VERSION "FL_IC_CANFD"

NS_ :

BS_:

BU_: AVAS BBCM CMSM DVR EAMP EPC FLZCU ICC PCL PLG SBOX SCU

BO_ 1265 ICC_ZCU_25: 24 ICC
 SG_ ICC_PwrOff : 18|1@0+ (1,0) [0|1] ""  FLZCU
 SG_ ICC_EtmEgySave : 20|1@0+ (1,0) [0|1] ""  FLZCU
 SG_ ICC_HoodSW : 23|2@0+ (1,0) [0|3] ""  FLZCU
 SG_ ICC_GloveboxSW : 25|2@0+ (1,0) [0|3] ""  FLZCU
 SG_ ICC_ChrgPortCover_Switch : 27|2@0+ (1,0) [0|3] ""  FLZCU
 SG_ ICC_ReWinDefrstSwt : 29|2@0+ (1,0) [0|3] ""  FLZCU
 SG_ ICC_RearMirrorFoldCmd : 31|2@0+ (1,0) [0|3] ""  FLZCU
 SG_ ICC_CenterLockSwt : 33|2@0+ (1,0) [0|3] ""  FLZCU
 SG_ ICC_ReverseExtMirrorSts : 36|3@0+ (1,0) [0|7] ""  FLZCU
 SG_ ICC_LightMainSwitchSts : 39|3@0+ (1,0) [0|7] ""  FLZCU
 SG_ ICC_AutoFoldSts : 41|2@0+ (1,0) [0|3] ""  FLZCU
 SG_ ICC_HeadlampHeightSts : 44|3@0+ (1,0) [0|7] ""  FLZCU
 SG_ ICC_WiprSnvty : 47|3@0+ (1,0) [0|7] ""  FLZCU
 SG_ ICC_WindowCmd : 52|5@0+ (1,0) [0|31] ""  FLZCU
 SG_ ICC_LowBeamDelayOff : 55|3@0+ (1,0) [0|7] ""  FLZCU
 SG_ DrvWinCmd_4F1h : 62|7@0+ (1,-1) [-1|100] "%"  FLZCU
 SG_ PassWinCmd_4F1h : 86|7@0+ (1,-1) [-1|100] "%"  FLZCU
 SG_ DrvRearWinCmd_4F1h : 94|7@0+ (1,-1) [-1|100] "%"  FLZCU
 SG_ PassRearWinCmd_4F1h : 102|7@0+ (1,-1) [-1|100] "%"  FLZCU
 SG_ ICC_FGHeatSts : 105|2@0+ (1,0) [0|3] ""  FLZCU
 SG_ ICC_AutolockSts : 107|2@0+ (1,0) [0|3] ""  FLZCU
 SG_ ICC_WiperID : 109|2@0+ (1,0) [0|3] ""  FLZCU
 SG_ ICC_MaintenanceMode : 111|2@0+ (1,0) [0|3] ""  FLZCU
 SG_ ICC_lockSetSwitchSts : 113|2@0+ (1,0) [0|3] ""  FLZCU
 SG_ ICC_ChildLockSW : 115|2@0+ (1,0) [0|3] ""  FLZCU
 SG_ ICC_ParkUnlockEnable : 117|2@0+ (1,0) [0|3] ""  FLZCU
 SG_ ICC_BLEOpenDriverDoorEnable : 119|2@0+ (1,0) [0|3] ""  FLZCU
 SG_ ICC_WinInhbSwt : 121|2@0+ (1,0) [0|3] ""  FLZCU
 SG_ ICC_SteerWhlHeatgSwt : 124|3@0+ (1,0) [0|7] ""  FLZCU
 SG_ ICC_AutoHeatingset : 127|2@0+ (1,0) [0|3] ""  FLZCU
 SG_ ICC_FrontFogSw : 145|2@0+ (1,0) [0|3] ""  FLZCU
 SG_ ICC_RearFogSw : 147|2@0+ (1,0) [0|3] ""  FLZCU
 SG_ ICC_DoorControlSW : 149|2@0+ (1,0) [0|3] ""  FLZCU
 SG_ ICC_LockCarWinCloseSw : 151|2@0+ (1,0) [0|3] ""  FLZCU
 SG_ ICC_NapStatusSet : 153|2@0+ (1,0) [0|3] ""  FLZCU
 SG_ ICC_NapAreaSet : 155|2@0+ (1,0) [0|3] ""  FLZCU
 SG_ ICC_EasyEntryExitSet : 157|2@0+ (1,0) [0|3] ""  FLZCU
 SG_ ICC_RainCarWinCloseSw : 159|2@0+ (1,0) [0|3] ""  FLZCU
 SG_ ICC_NapTimeSet : 166|6@0+ (1,-1) [-1|60] "min"  FLZCU
 SG_ ICC_NapSetTemperature : 173|5@0+ (0.5,15.5) [15.5|30.5] "℃"  FLZCU
 SG_ ICC_NapCFSStatusSet : 175|2@0+ (1,0) [0|3] ""  FLZCU
 SG_ ICC_HazardLightReq : 177|2@0+ (1,0) [0|3] ""  FLZCU
 SG_ ICC_SpoilerCtrlCmd : 181|3@0+ (1,0) [0|7] ""  FLZCU
 SG_ ICC_SpoilerWelcomeFunSet : 183|2@0+ (1,0) [0|3] ""  FLZCU
 SG_ ICC_CinemaStatus : 185|2@0+ (1,0) [0|3] ""  BBCM,FLZCU,PCL
 SG_ ICC_MusicStatus : 187|2@0+ (1,0) [0|3] ""  FLZCU

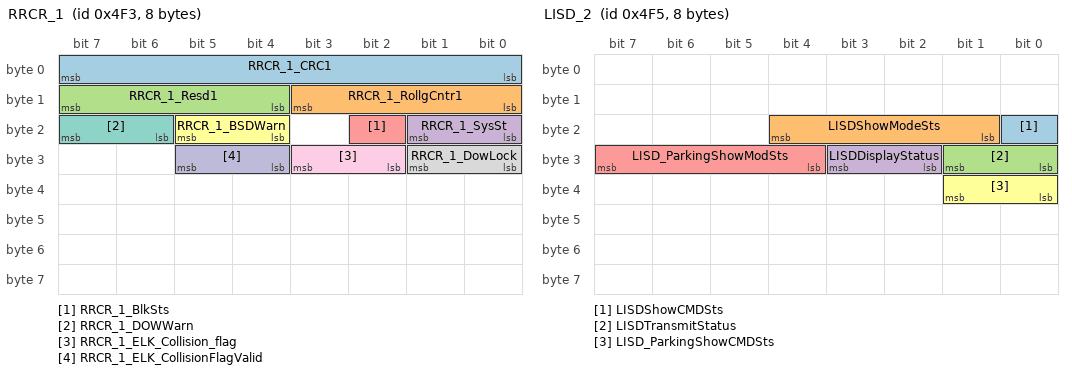
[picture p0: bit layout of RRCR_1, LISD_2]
BO_ 1267 RRCR_1: 8 FLZCU
 SG_ RRCR_1_CRC1 : 7|8@0+ (1,0) [0|255] ""  ICC
 SG_ RRCR_1_RollgCntr1 : 11|4@0+ (1,0) [0|14] ""  ICC
 SG_ RRCR_1_Resd1 : 15|4@0+ (1,0) [0|15] ""  ICC
 SG_ RRCR_1_SysSt : 17|2@0+ (1,0) [0|3] ""  ICC
 SG_ RRCR_1_BlkSts : 18|1@0+ (1,0) [0|1] ""  ICC
 SG_ RRCR_1_BSDWarn : 21|2@0+ (1,0) [0|3] ""  ICC
 SG_ RRCR_1_DOWWarn : 23|2@0+ (1,0) [0|3] ""  ICC
 SG_ RRCR_1_DowLock : 25|2@0+ (1,0) [0|3] ""  ICC
 SG_ RRCR_1_ELK_Collision_flag : 27|2@0+ (1,0) [0|3] ""  ICC
 SG_ RRCR_1_ELK_CollisionFlagValid : 29|2@0+ (1,0) [0|3] ""  ICC

BO_ 1269 LISD_2: 8 FLZCU
 SG_ LISDShowCMDSts : 16|1@0+ (1,0) [0|1] ""  ICC
 SG_ LISDShowModeSts : 20|4@0+ (1,0) [0|15] ""  ICC
 SG_ LISDTransmitStatus : 25|2@0+ (1,0) [0|3] ""  ICC
 SG_ LISDDisplayStatus : 27|2@0+ (1,0) [0|3] ""  ICC
 SG_ LISD_ParkingShowModSts : 31|4@0+ (1,0) [0|15] ""  ICC
 SG_ LISD_ParkingShowCMDSts : 33|2@0+ (1,0) [0|3] ""  ICC

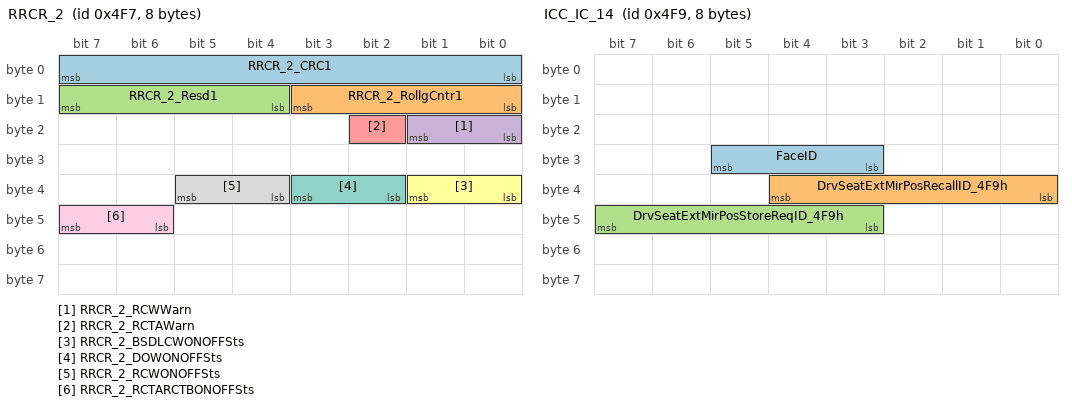
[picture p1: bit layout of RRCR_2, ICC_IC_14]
BO_ 1271 RRCR_2: 8 FLZCU
 SG_ RRCR_2_CRC1 : 7|8@0+ (1,0) [0|255] ""  ICC
 SG_ RRCR_2_RollgCntr1 : 11|4@0+ (1,0) [0|14] ""  ICC
 SG_ RRCR_2_Resd1 : 15|4@0+ (1,0) [0|15] ""  ICC
 SG_ RRCR_2_RCWWarn : 17|2@0+ (1,0) [0|3] ""  ICC
 SG_ RRCR_2_RCTAWarn : 18|1@0+ (1,0) [0|1] ""  ICC
 SG_ RRCR_2_BSDLCWONOFFSts : 33|2@0+ (1,0) [0|3] ""  ICC
 SG_ RRCR_2_DOWONOFFSts : 35|2@0+ (1,0) [0|3] ""  ICC
 SG_ RRCR_2_RCWONOFFSts : 37|2@0+ (1,0) [0|3] ""  ICC
 SG_ RRCR_2_RCTARCTBONOFFSts : 47|2@0+ (1,0) [0|3] ""  ICC

BO_ 1273 ICC_IC_14: 8 ICC
 SG_ FaceID : 29|3@0+ (1,0) [0|7] ""  FLZCU
 SG_ DrvSeatExtMirPosRecallID_4F9h : 36|5@0+ (1,0) [0|31] ""  FLZCU
 SG_ DrvSeatExtMirPosStoreReqID_4F9h : 47|5@0+ (1,0) [0|31] ""  FLZCU

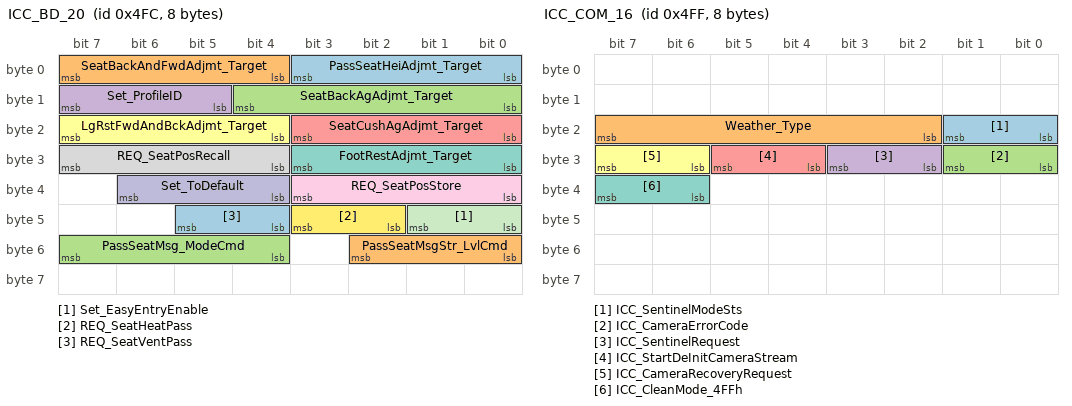
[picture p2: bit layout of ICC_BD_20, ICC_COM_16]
BO_ 1276 ICC_BD_20: 8 ICC
 SG_ PassSeatHeiAdjmt_Target : 3|4@0+ (1,0) [0|15] "" Vector__XXX
 SG_ SeatBackAndFwdAdjmt_Target : 7|4@0+ (1,0) [0|15] "" Vector__XXX
 SG_ SeatBackAgAdjmt_Target : 12|5@0+ (1,0) [0|31] "" Vector__XXX
 SG_ Set_ProfileID : 15|3@0+ (1,0) [0|7] "" Vector__XXX
 SG_ SeatCushAgAdjmt_Target : 19|4@0+ (1,0) [0|15] "" Vector__XXX
 SG_ LgRstFwdAndBckAdjmt_Target : 23|4@0+ (1,0) [0|15] "" Vector__XXX
 SG_ FootRestAdjmt_Target : 27|4@0+ (1,0) [0|15] "" Vector__XXX
 SG_ REQ_SeatPosRecall : 31|4@0+ (1,0) [0|15] "" Vector__XXX
 SG_ REQ_SeatPosStore : 35|4@0+ (1,0) [0|15] "" Vector__XXX
 SG_ Set_ToDefault : 38|3@0+ (1,0) [0|7] "" Vector__XXX
 SG_ Set_EasyEntryEnable : 41|2@0+ (1,0) [0|3] "" Vector__XXX
 SG_ REQ_SeatHeatPass : 43|2@0+ (1,0) [0|3] "" Vector__XXX
 SG_ REQ_SeatVentPass : 45|2@0+ (1,0) [0|3] "" Vector__XXX
 SG_ PassSeatMsgStr_LvlCmd : 50|3@0+ (1,0) [0|7] "" Vector__XXX
 SG_ PassSeatMsg_ModeCmd : 55|4@0+ (1,0) [0|15] "" Vector__XXX

BO_ 1279 ICC_COM_16: 8 ICC
 SG_ ICC_SentinelModeSts : 17|2@0+ (1,0) [0|3] ""  FLZCU
 SG_ Weather_Type : 23|6@0+ (1,0) [0|63] ""  FLZCU
 SG_ ICC_CameraErrorCode : 25|2@0+ (1,0) [0|3] ""  FLZCU
 SG_ ICC_SentinelRequest : 27|2@0+ (1,0) [0|3] ""  FLZCU
 SG_ ICC_StartDeInitCameraStream : 29|2@0+ (1,0) [0|3] ""  FLZCU
 SG_ ICC_CameraRecoveryRequest : 31|2@0+ (1,0) [0|3] ""  FLZCU
 SG_ ICC_CleanMode_4FFh : 39|2@0+ (1,0) [0|3] ""  FLZCU

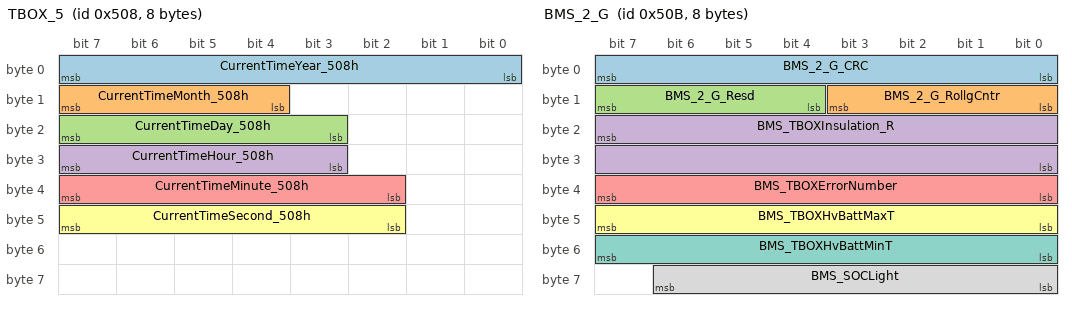
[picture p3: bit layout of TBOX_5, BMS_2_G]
BO_ 1288 TBOX_5: 8 FLZCU
 SG_ CurrentTimeYear_508h : 7|8@0+ (1,2000) [2000|2255] ""  ICC
 SG_ CurrentTimeMonth_508h : 15|4@0+ (1,0) [1|12] ""  ICC
 SG_ CurrentTimeDay_508h : 23|5@0+ (1,0) [1|31] ""  ICC
 SG_ CurrentTimeHour_508h : 31|5@0+ (1,0) [0|23] ""  ICC
 SG_ CurrentTimeMinute_508h : 39|6@0+ (1,0) [0|59] ""  ICC
 SG_ CurrentTimeSecond_508h : 47|6@0+ (1,0) [0|59] ""  ICC

BO_ 1289 ICC_34: 32 ICC
 SG_ ICC_ToggleUnits : 19|2@0+ (1,0) [0|3] ""  FLZCU
 SG_ ICC_TireTemperatureDisplayUnit : 21|2@0+ (1,0) [0|3] ""  FLZCU
 SG_ ICC_TirePressureDisplayUnit : 23|2@0+ (1,0) [0|3] ""  FLZCU
 SG_ ICC_GPSSwitchSet : 25|2@0+ (1,0) [0|3] ""  FLZCU
 SG_ ICC_BtConFlag : 28|3@0+ (1,0) [0|7] ""  FLZCU,SBOX
 SG_ ICC_LanguageSet_509h : 37|6@0+ (1,0) [0|63] ""  FLZCU
 SG_ ICC_Day_Displaysts_509h : 49|2@0+ (1,0) [0|3] ""  FLZCU

BO_ 1290 BMS_8: 8 FLZCU
 SG_ BMS_8_CRC1 : 7|8@0+ (1,0) [0|255] ""  ICC
 SG_ BMS_8_RollgCntr1 : 11|4@0+ (1,0) [0|14] ""  ICC
 SG_ BMS_8_Resd1 : 15|4@0+ (1,0) [0|15] ""  ICC
 SG_ BMS_HvBattCellOverU : 18|3@0+ (1,0) [0|7] ""  ICC
 SG_ BMS_HvBattCellUnderU : 21|3@0+ (1,0) [0|7] ""  ICC
 SG_ BMS_HvBattUnderU : 23|2@0+ (1,0) [0|3] ""  ICC
 SG_ BMS_HvBattDischargeOverCurrent : 26|3@0+ (1,0) [0|7] ""  ICC
 SG_ BMS_HvBattChargeOverCurrent : 29|3@0+ (1,0) [0|7] ""  ICC
 SG_ BMS_HvBattOverU : 31|2@0+ (1,0) [0|3] ""  ICC
 SG_ BMS_HvBattMismatching : 32|1@0+ (1,0) [0|1] ""  ICC
 SG_ BMS_HvBattSocJump : 33|1@0+ (1,0) [0|1] ""  ICC
 SG_ BMS_HvBattCellUUnif : 34|1@0+ (1,0) [0|1] ""  ICC
 SG_ BMS_HvBattLowSoc : 35|1@0+ (1,0) [0|1] ""  ICC
 SG_ BMS_HvBattOverSoc : 36|1@0+ (1,0) [0|1] ""  ICC
 SG_ BMS_HvBattTempUniformity : 37|1@0+ (1,0) [0|1] ""  ICC
 SG_ BMS_BattInterCANErr : 38|1@0+ (1,0) [0|1] ""  ICC
 SG_ BMS_HvBattOverCharging : 39|1@0+ (1,0) [0|1] ""  ICC
 SG_ BMS_HvBattOverTemperature : 47|3@0+ (1,0) [0|7] ""  ICC

BO_ 1291 BMS_2_G: 8 FLZCU
 SG_ BMS_2_G_CRC : 7|8@0+ (1,0) [0|255] ""  ICC
 SG_ BMS_2_G_RollgCntr : 11|4@0+ (1,0) [0|14] ""  ICC
 SG_ BMS_2_G_Resd : 15|4@0+ (1,0) [0|15] ""  ICC
 SG_ BMS_TBOXInsulation_R : 23|16@0+ (1,0) [0|60000] "kiloohm(kΩ)"  ICC
 SG_ BMS_TBOXErrorNumber : 39|8@0+ (1,0) [0|255] ""  ICC
 SG_ BMS_TBOXHvBattMaxT : 47|8@0+ (1,-40) [-40|210] "gradcelsius(°C)"  ICC
 SG_ BMS_TBOXHvBattMinT : 55|8@0+ (1,-40) [-40|210] "gradcelsius(°C)"  ICC
 SG_ BMS_SOCLight : 62|7@0+ (1,0) [0|100] "%"  ICC

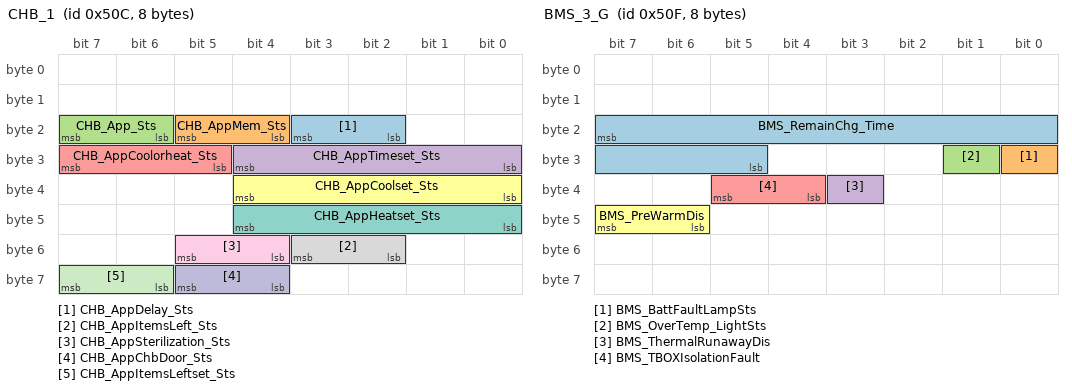
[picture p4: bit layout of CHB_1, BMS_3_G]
BO_ 1292 CHB_1: 8 FLZCU
 SG_ CHB_AppDelay_Sts : 19|2@0+ (1,0) [0|3] ""  ICC
 SG_ CHB_AppMem_Sts : 21|2@0+ (1,0) [0|3] ""  ICC
 SG_ CHB_App_Sts : 23|2@0+ (1,0) [0|3] ""  ICC
 SG_ CHB_AppTimeset_Sts : 28|5@0+ (1,0) [0|31] "h"  ICC
 SG_ CHB_AppCoolorheat_Sts : 31|3@0+ (1,0) [0|7] ""  ICC
 SG_ CHB_AppCoolset_Sts : 36|5@0+ (1,0) [0|31] ""  ICC
 SG_ CHB_AppHeatset_Sts : 44|5@0+ (1,0) [0|31] ""  ICC
 SG_ CHB_AppItemsLeft_Sts : 51|2@0+ (1,0) [0|3] ""  ICC
 SG_ CHB_AppSterilization_Sts : 53|2@0+ (1,0) [0|3] ""  ICC
 SG_ CHB_AppChbDoor_Sts : 61|2@0+ (1,0) [0|3] ""  ICC
 SG_ CHB_AppItemsLeftset_Sts : 63|2@0+ (1,0) [0|3] ""  ICC

BO_ 1295 BMS_3_G: 8 FLZCU
 SG_ BMS_RemainChg_Time : 23|11@0+ (1,0) [0|2047] "min"  ICC
 SG_ BMS_BattFaultLampSts : 24|1@0+ (1,0) [0|1] ""  ICC
 SG_ BMS_OverTemp_LightSts : 25|1@0+ (1,0) [0|1] ""  ICC
 SG_ BMS_ThermalRunawayDis : 35|1@0+ (1,0) [0|1] ""  ICC
 SG_ BMS_TBOXIsolationFault : 37|2@0+ (1,0) [0|3] ""  ICC
 SG_ BMS_PreWarmDis : 47|2@0+ (1,0) [0|3] ""  ICC

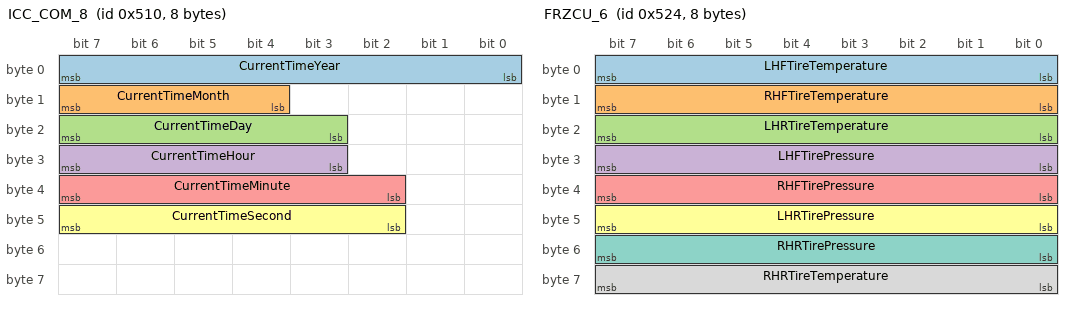
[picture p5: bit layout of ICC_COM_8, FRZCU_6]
BO_ 1296 ICC_COM_8: 8 ICC
 SG_ CurrentTimeYear : 7|8@0+ (1,2000) [2000|2255] ""  DVR,EPC,FLZCU,PLG
 SG_ CurrentTimeMonth : 15|4@0+ (1,0) [1|12] ""  DVR,EPC,FLZCU,PLG
 SG_ CurrentTimeDay : 23|5@0+ (1,0) [1|31] ""  DVR,EPC,FLZCU,PLG
 SG_ CurrentTimeHour : 31|5@0+ (1,0) [0|23] ""  DVR,EPC,FLZCU,PLG
 SG_ CurrentTimeMinute : 39|6@0+ (1,0) [0|59] ""  DVR,EPC,FLZCU,PLG
 SG_ CurrentTimeSecond : 47|6@0+ (1,0) [0|59] ""  DVR,EPC,FLZCU,PLG

BO_ 1299 BMS_1_G: 8 FLZCU
 SG_ BMS_PackVoltageDis : 23|16@0+ (0.1,0) [0|1000] "volt(V)"  ICC
 SG_ BMS_PackCurrentDis : 39|16@0+ (0.1,-2047) [-2047|2047] "ampere(A)"  ICC

BO_ 1310 BBCM_1: 32 SCU
 SG_ DrvSecSeatEasyEntryExitFb_51Eh : 17|2@0+ (1,0) [0|3] ""  ICC
 SG_ PassSecSeatEasyEntryExitFb_51Eh : 19|2@0+ (1,0) [0|3] ""  ICC
 SG_ DrvSecSeatNeedMemory_51Eh : 21|2@0+ (1,0) [0|3] ""  ICC
 SG_ DrvSecMemoryFb_51Eh : 23|2@0+ (1,0) [0|3] ""  ICC
 SG_ DrvSecRecoverFb_51Eh : 25|2@0+ (1,0) [0|3] ""  ICC
 SG_ PassSecSeatNeedMemory_51Eh : 27|2@0+ (1,0) [0|3] ""  ICC
 SG_ PassSecMemoryFb_51Eh : 29|2@0+ (1,0) [0|3] ""  ICC
 SG_ PassSecRecoverFb_51Eh : 31|2@0+ (1,0) [0|3] ""  ICC
 SG_ DrvSecSeatLvlFb_51Eh : 38|7@0+ (1,-1) [-1|100] "%"  ICC
 SG_ DrvSecSeatBackAgFb_51Eh : 46|7@0+ (1,-1) [-1|100] "%"  ICC
 SG_ DrvSecSeatLegSpprtFb_51Eh : 54|7@0+ (1,-1) [-1|100] "%"  ICC
 SG_ DrvSecSeatLegRestAngleFb_51Eh : 62|7@0+ (1,-1) [-1|100] "%"  ICC
 SG_ PassSecSeatLvlFb_51Eh : 70|7@0+ (1,-1) [-1|100] "%"  ICC
 SG_ PassSecSeatBackAgFb_51Eh : 78|7@0+ (1,-1) [-1|100] "%"  ICC
 SG_ PassSecSeatLegSpprtFb_51Eh : 86|7@0+ (1,-1) [-1|100] "%"  ICC
 SG_ PassSecSeatLegRestAngleFb_51Eh : 94|7@0+ (1,-1) [-1|100] "%"  ICC
 SG_ DrvTrdSeatBackAgFb_51Eh : 102|7@0+ (1,-1) [-1|100] "%"  ICC
 SG_ PassTrdSeatBackAgFb_51Eh : 110|7@0+ (1,-1) [-1|100] "%"  ICC
 SG_ DrvTrdSeatFrontFlipFb_51Eh : 118|7@0+ (1,-1) [-1|100] "%"  ICC
 SG_ PassTrdSeatFrontFlipFb_51Eh : 126|7@0+ (1,-1) [-1|100] "%"  ICC
 SG_ PassSecSeatExpSwCmd_51Eh : 145|2@0+ (1,0) [0|3] ""  ICC
 SG_ PassTrdSeatSwCmd_51Eh : 148|3@0+ (1,0) [0|7] ""  ICC
 SG_ BBCM_RLSeatSwCmd3rd : 151|3@0+ (1,0) [0|7] ""  ICC
 SG_ BBCM_RLSeatExpSwCmd2rd : 153|2@0+ (1,0) [0|3] ""  ICC
 SG_ BBCM_RLSeatExpSwSt2rd : 157|2@0+ (1,0) [0|3] ""  ICC
 SG_ PassSecSeatExpSwSt_51Eh : 159|2@0+ (1,0) [0|3] ""  ICC
 SG_ BBCM_RRSeatZeroFb2nd : 166|7@0+ (1,-1) [-1|100] "%"  ICC
 SG_ BBCM_RLSeatZeroFb2nd : 174|7@0+ (1,-1) [-1|100] "%"  ICC
 SG_ BBCM_RLSeatExpRstStsFb : 211|2@0+ (1,0) [0|3] ""  ICC
 SG_ PassSecSeatMovFailCause_51Eh : 243|4@0+ (1,0) [0|15] ""  ICC
 SG_ DrvSecSeatMovFailCause_51Eh : 247|4@0+ (1,0) [0|15] ""  ICC
 SG_ PassTrdSeatMovFailCause_51Eh : 251|4@0+ (1,0) [0|15] ""  ICC
 SG_ DrvTrdSeatMovFailCause_51Eh : 255|4@0+ (1,0) [0|15] ""  ICC

BO_ 1312 ICC_RemoteDiag: 32 ICC
 SG_ ICC_TotalFaultNum : 7|8@0+ (1,0) [0|255] ""  FLZCU
 SG_ ICC_FrameIndex : 12|5@0+ (1,0) [0|31] ""  FLZCU
 SG_ ICC_SupplierNum : 15|3@0+ (1,0) [0|7] ""  FLZCU
 SG_ ICC_FaultNum1 : 23|12@0+ (1,0) [0|4095] ""  FLZCU
 SG_ ICC_FaultNum2 : 27|12@0+ (1,0) [0|4095] ""  FLZCU
 SG_ ICC_FaultNum3 : 47|12@0+ (1,0) [0|4095] ""  FLZCU
 SG_ ICC_FaultNum4 : 51|12@0+ (1,0) [0|4095] ""  FLZCU
 SG_ ICC_FaultNum5 : 71|12@0+ (1,0) [0|4095] ""  FLZCU
 SG_ ICC_FaultNum6 : 75|12@0+ (1,0) [0|4095] ""  FLZCU
 SG_ ICC_FaultNum7 : 95|12@0+ (1,0) [0|4095] ""  FLZCU
 SG_ ICC_FaultNum8 : 99|12@0+ (1,0) [0|4095] ""  FLZCU
 SG_ ICC_FaultNum9 : 119|12@0+ (1,0) [0|4095] ""  FLZCU
 SG_ ICC_FaultNum10 : 123|12@0+ (1,0) [0|4095] ""  FLZCU
 SG_ ICC_FaultNum11 : 143|12@0+ (1,0) [0|4095] ""  FLZCU
 SG_ ICC_FaultNum12 : 147|12@0+ (1,0) [0|4095] ""  FLZCU
 SG_ ICC_FaultNum13 : 167|12@0+ (1,0) [0|4095] ""  FLZCU
 SG_ ICC_FaultNum14 : 171|12@0+ (1,0) [0|4095] ""  FLZCU
 SG_ ICC_FaultNum15 : 191|12@0+ (1,0) [0|4095] ""  FLZCU
 SG_ ICC_FaultNum16 : 195|12@0+ (1,0) [0|4095] ""  FLZCU
 SG_ ICC_FaultNum17 : 215|12@0+ (1,0) [0|4095] ""  FLZCU
 SG_ ICC_FaultNum18 : 219|12@0+ (1,0) [0|4095] ""  FLZCU
 SG_ ICC_FaultNum19 : 239|12@0+ (1,0) [0|4095] ""  FLZCU
 SG_ ICC_FaultNum20 : 243|12@0+ (1,0) [0|4095] ""  FLZCU

BO_ 1314 HCU_25: 64 FLZCU
 SG_ HCU_V2lDisChgBck : 17|2@0+ (1,0) [0|3] ""  ICC
 SG_ HCU_DisChgMemFed : 19|2@0+ (1,0) [0|3] ""  ICC
 SG_ HCU_V2VDisChgBck : 21|2@0+ (1,0) [0|3] ""  ICC
 SG_ HCU_V2l_IntlDisChgBck : 23|2@0+ (1,0) [0|3] ""  ICC
 SG_ HCU_FuelDetnOpDefeated : 25|2@0+ (1,0) [0|3] ""  ICC
 SG_ HCU_FuelDetnModSwtFed : 27|2@0+ (1,0) [0|3] ""  ICC
 SG_ HCU_FuelDetnStateFed : 29|2@0+ (1,0) [0|3] ""  ICC
 SG_ HCU_HVDownRepairModeFed : 31|2@0+ (1,0) [0|3] ""  ICC
 SG_ HCU_SumFuCns : 37|9@0+ (0.1,0) [0|50] "L/km"  ICC
 SG_ HCU_TrailerMode : 39|2@0+ (1,0) [0|3] ""  ICC
 SG_ HCU_TABSwtFed_522h : 40|2@0+ (1,0) [0|3] ""  ICC
 SG_ HCU_KeyDriveModememory : 49|2@0+ (1,0) [0|3] ""  ICC
 SG_ HCU_DrivePowerDispSetFed : 51|2@0+ (1,0) [0|3] ""  ICC
 SG_ HCU_EXPERTNormFed : 57|2@0+ (1,0) [0|3] ""  ICC
 SG_ HCU_4LModeFed : 58|1@0+ (1,0) [0|1] ""  ICC
 SG_ HCU_EXPERTEcoFed : 60|2@0+ (1,0) [0|3] ""  ICC
 SG_ HCU_SingleRegnRmn : 61|1@0+ (1,0) [0|1] ""  ICC
 SG_ HCU_DRIFTModeSts : 63|2@0+ (1,0) [0|3] ""  ICC
 SG_ HCU_EXPERTAWDFed : 81|2@0+ (1,0) [0|3] ""  ICC
 SG_ HCU_EXPERTRWDFed : 83|2@0+ (1,0) [0|3] ""  ICC
 SG_ HCU_CrossaxisFed : 85|2@0+ (1,0) [0|3] ""  ICC
 SG_ HCU_EXPERTSportFed : 87|2@0+ (1,0) [0|3] ""  ICC
 SG_ HCU_StopChrgnModeFed : 89|2@0+ (1,0) [0|3] ""  ICC
 SG_ HCU_StopChrgnFed : 91|2@0+ (1,0) [0|3] ""  ICC
 SG_ HCU_CLIMBFed : 93|2@0+ (1,0) [0|3] ""  ICC
 SG_ HCU_EXPERTAutoFed : 95|2@0+ (1,0) [0|3] ""  ICC
 SG_ HCU_HEV_FunctionLimit : 96|1@0+ (1,0) [0|1] ""  ICC
 SG_ HCU_ParkingChargeReminder : 97|1@0+ (1,0) [0|1] ""  ICC
 SG_ HCU_PowerCut : 98|1@0+ (1,0) [0|1] ""  ICC
 SG_ HCU_IMMOReleaseSignal : 99|1@0+ (1,0) [0|1] ""  ICC
 SG_ HCU_LVPowSupSYSAbn_lit : 100|1@0+ (1,0) [0|1] ""  ICC
 SG_ HCU_ChrgnFctMemSt : 102|2@0+ (1,0) [0|3] ""  ICC
 SG_ HCU_PowerModeChangeInhibit : 104|1@0+ (1,0) [0|1] ""  ICC
 SG_ HCU_DisconnectChagWarn : 105|1@0+ (1,0) [0|1] ""  ICC
 SG_ HCU_EngineRunClmReq : 106|1@0+ (1,0) [0|1] ""  ICC
 SG_ HCU_VehicleSpeedMax_Limit : 107|1@0+ (1,0) [0|1] ""  ICC
 SG_ HCU_AccleAbility_Limit : 108|1@0+ (1,0) [0|1] ""  ICC
 SG_ HCU_DriveInhibit_GearP : 109|1@0+ (1,0) [0|1] ""  ICC
 SG_ HCU_SetModeNotChange : 110|1@0+ (1,0) [0|1] ""  ICC
 SG_ HCU_UTURNSnowFed : 111|1@0+ (1,0) [0|1] ""  ICC
 SG_ HCU_PowerLevel : 114|3@0+ (1,0) [0|7] ""  ICC
 SG_ HCU_TowingModeEna : 115|1@0+ (1,0) [0|1] ""  ICC
 SG_ HCU_LeaveVehicleWarning : 116|1@0+ (1,0) [0|1] ""  ICC
 SG_ HCU_DedicatedModeInhibit : 117|1@0+ (1,0) [0|1] ""  ICC
 SG_ HCU_DisChargeStopFault : 119|2@0+ (1,0) [0|3] ""  ICC
 SG_ HCU_RearEDLSts : 123|4@0+ (1,0) [0|15] ""  ICC
 SG_ HCU_FrntEDLSts : 127|4@0+ (1,0) [0|15] ""  ICC
 SG_ HCU_CruiseLimitSpeedValue : 146|13@0+ (0.0625,0) [0|511.875] "km/h"  ICC
 SG_ HCU_DriveMode_JT : 151|5@0+ (1,0) [0|31] ""  ICC
 SG_ HCU_SocManageFed : 162|3@0+ (1,0) [0|7] ""  ICC
 SG_ HCU_SinglePedalMemFed : 163|1@0+ (1,0) [0|1] ""  ICC
 SG_ HCU_CCOSwtFed : 165|2@0+ (1,0) [0|3] ""  ICC
 SG_ HCU_Pwr : 175|12@0+ (1,-2000) [-2000|2000] "KW"  ICC
 SG_ HCU_DrvGearShiftFailureIndcn : 179|4@0+ (1,0) [0|15] ""  ICC
 SG_ HCU_UTURNSandFed : 184|1@0+ (1,0) [0|1] ""  ICC
 SG_ HCU_CruiseControlStatus : 186|2@0+ (1,0) [0|3] ""  ICC
 SG_ HCU_EXPERTEESPSet : 188|2@0+ (1,0) [0|3] ""  ICC
 SG_ HCU_EgyRegenLevel : 191|3@0+ (1,0) [0|7] ""  ICC
 SG_ HCU_EngyFlowToDisp : 211|5@0+ (1,0) [0|31] ""  ICC
 SG_ HCU_UTURNGrassFed : 212|1@0+ (1,0) [0|1] ""  ICC
 SG_ HCU_UTURNMudFed : 213|1@0+ (1,0) [0|1] ""  ICC
 SG_ HCU_LTCDispFed : 215|2@0+ (1,0) [0|3] ""  ICC
 SG_ HCU_iTAS_Warn : 217|3@0+ (1,0) [0|7] ""  ICC
 SG_ HCU_iCCO_Warn : 221|4@0+ (1,0) [0|15] ""  ICC
 SG_ HCU_DriveModeChangeFail : 222|1@0+ (1,0) [0|1] ""  ICC
 SG_ HCU_25_Crossaxis_Warn : 225|3@0+ (1,0) [0|7] ""  ICC
 SG_ HCU_25_EDLFed : 227|2@0+ (1,0) [0|3] ""  ICC
 SG_ HCU_DraggingModeRemind : 230|3@0+ (1,0) [0|7] ""  ICC
 SG_ HCU_iTASSceneReq : 232|3@0+ (1,0) [0|7] ""  ICC
 SG_ HCU_25_iTAS_SlopWarn : 234|2@0+ (1,0) [0|3] ""  ICC
 SG_ HCU_ExterTempLowHint : 236|2@0+ (1,0) [0|3] ""  ICC
 SG_ HCU_iTAS_Active : 238|2@0+ (1,0) [0|3] ""  ICC
 SG_ HCU_25_VehSpdOffroadRmn : 240|1@0+ (1,0) [0|1] ""  ICC
 SG_ HCU_DrivingModReq : 245|5@0+ (1,0) [0|31] ""  ICC
 SG_ HCU_25_iDRIFT_Warn : 298|3@0+ (1,0) [0|7] ""  ICC
 SG_ HCU_25_SetVehSpdOffroad : 300|2@0+ (1,0) [0|3] ""  ICC
 SG_ HCU_25_LaunchMod_Warn : 303|3@0+ (1,0) [0|7] ""  ICC
 SG_ HCU_25_TAB_Warn : 307|3@0+ (1,0) [0|7] ""  ICC
 SG_ HCU_25_CCO_TextDisp : 311|4@0+ (1,0) [0|15] ""  ICC
 SG_ HCU_25_DCM_Warn : 315|4@0+ (1,0) [0|15] ""  ICC
 SG_ HCU_25_CCMFed : 317|2@0+ (1,0) [0|3] ""  ICC
 SG_ HCU_SumElecCns : 339|12@0+ (0.1,-100) [-100|100] "kwh/100km"  ICC
 SG_ HCU_CrossBorderSts : 341|2@0+ (1,0) [0|3] ""  ICC
 SG_ HCU_DischgSetSOCFed : 367|8@0+ (1,0) [0|100] "%"  ICC
 SG_ HCU_facCleverDrvAct_522h : 369|5@0+ (0.1,-1) [-1|2.1] ""  ICC
 SG_ HCU_stCleverDrvAct_522h : 371|2@0+ (1,0) [0|3] ""  ICC
 SG_ HCU_stCleverRgnAct_522h : 373|2@0+ (1,0) [0|3] ""  ICC
 SG_ HCU_stCleverMainAct_522h : 375|2@0+ (1,0) [0|3] ""  ICC
 SG_ EnergySavingModeSts_522h : 378|2@0+ (1,0) [0|3] ""  ICC
 SG_ HCU_facCleverDrvActRstFed_522h : 380|2@0+ (1,0) [0|3] ""  ICC
 SG_ HCU_SailramainingT_Indc_522h : 407|16@0+ (1,0) [0|65535] "s"  ICC
 SG_ HCU_ATCM_Operation_REQ_522h : 416|3@0+ (1,0) [0|7] ""  ICC
 SG_ HCU_ModeSwFailureIndc_522h : 419|3@0+ (1,0) [0|7] ""  ICC
 SG_ HCU_Sailmode_522h : 423|4@0+ (1,0) [0|15] ""  ICC
 SG_ HCU_CarSickRelfModeFb : 425|2@0+ (1,0) [0|3] ""  ICC
 SG_ HCU_DeepSnowSts_522h : 427|2@0+ (1,0) [0|3] ""  ICC
 SG_ DriveModeChangeFailReason_522h : 429|2@0+ (1,0) [0|3] ""  ICC
 SG_ HCU_CarSickRelfModeDisReason : 436|3@0+ (1,0) [0|7] ""  ICC
 SG_ HCU_DCMSwtFed : 439|3@0+ (1,0) [0|7] ""  ICC

BO_ 1316 FRZCU_6: 8 FLZCU
 SG_ LHFTireTemperature : 7|8@0+ (0.65,-40) [-40|125.1] "℃"  ICC
 SG_ RHFTireTemperature : 15|8@0+ (0.65,-40) [-40|125.1] "℃"  ICC
 SG_ LHRTireTemperature : 23|8@0+ (0.65,-40) [-40|125.1] "℃"  ICC
 SG_ LHFTirePressure : 31|8@0+ (2.75,0) [0|701.25] "kPa"  ICC
 SG_ RHFTirePressure : 39|8@0+ (2.75,0) [0|701.25] "kPa"  ICC
 SG_ LHRTirePressure : 47|8@0+ (2.75,0) [0|701.25] "kPa"  ICC
 SG_ RHRTirePressure : 55|8@0+ (2.75,0) [0|701.25] "kPa"  ICC
 SG_ RHRTireTemperature : 63|8@0+ (0.65,-40) [-40|125.1] "℃"  ICC

BO_ 1318 ICC_TDL_41: 8 ICC
 SG_ ICC_SET_TDL_Rhythm_Switch : 1|2@0+ (1,0) [0|3] ""  FLZCU
 SG_ ICC_SET_TDL_Switch : 3|2@0+ (1,0) [0|3] ""  FLZCU
 SG_ ICC_SET_TDL_ColourModeAdj : 6|3@0+ (1,0) [0|7] ""  FLZCU
 SG_ ICC_TDL_RhythmReq : 10|3@0+ (1,0) [0|7] ""  FLZCU
 SG_ ICC_VoiceWake : 13|3@0+ (1,0) [0|7] ""  FLZCU
 SG_ ICC_TDLAssociatedDriverModeSw : 15|2@0+ (1,0) [0|3] ""  FLZCU
 SG_ ICC_SET_ApiluminanceAdj : 19|4@0+ (1,0) [0|15] ""  FLZCU
 SG_ ICC_SET_MusicLoudness_120HZ : 23|4@0+ (1,0) [0|15] ""  FLZCU
 SG_ ICC_SET_MusicLoudness_250HZ : 27|4@0+ (1,0) [0|15] ""  FLZCU
 SG_ ICC_SET_MusicLoudness_500HZ : 31|4@0+ (1,0) [0|15] ""  FLZCU
 SG_ ICC_SET_MusicLoudness_1000HZ : 35|4@0+ (1,0) [0|15] ""  FLZCU
 SG_ ICC_SET_MusicLoudness_1500HZ : 39|4@0+ (1,0) [0|15] ""  FLZCU
 SG_ ICC_SET_MusicLoudness_2000HZ : 43|4@0+ (1,0) [0|15] ""  FLZCU
 SG_ ICC_SET_MusicLoudness_6000HZ : 47|4@0+ (1,0) [0|15] ""  FLZCU
 SG_ ICC_SET_256ColourAdj : 48|9@0+ (1,0) [0|511] ""  FLZCU
 SG_ ICC_TDL_FlowLightSw : 51|2@0+ (1,0) [0|3] ""  FLZCU
 SG_ ICC_TDL_FlowLightModeAdj : 54|3@0+ (1,0) [0|7] ""  FLZCU

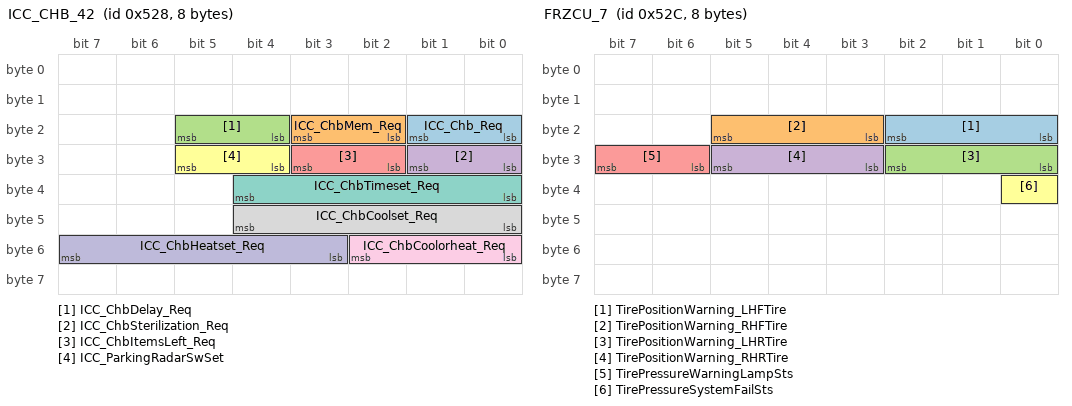
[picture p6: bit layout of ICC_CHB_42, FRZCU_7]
BO_ 1320 ICC_CHB_42: 8 ICC
 SG_ ICC_Chb_Req : 17|2@0+ (1,0) [0|3] ""  FLZCU
 SG_ ICC_ChbMem_Req : 19|2@0+ (1,0) [0|3] ""  FLZCU
 SG_ ICC_ChbDelay_Req : 21|2@0+ (1,0) [0|3] ""  FLZCU
 SG_ ICC_ChbSterilization_Req : 25|2@0+ (1,0) [0|3] ""  FLZCU
 SG_ ICC_ChbItemsLeft_Req : 27|2@0+ (1,0) [0|3] ""  FLZCU
 SG_ ICC_ParkingRadarSwSet : 29|2@0+ (1,0) [0|3] ""  FLZCU
 SG_ ICC_ChbTimeset_Req : 36|5@0+ (1,0) [0|31] "h"  FLZCU
 SG_ ICC_ChbCoolset_Req : 44|5@0+ (1,0) [0|31] ""  FLZCU
 SG_ ICC_ChbCoolorheat_Req : 50|3@0+ (1,0) [0|7] ""  FLZCU
 SG_ ICC_ChbHeatset_Req : 55|5@0+ (1,0) [0|31] ""  FLZCU

BO_ 1322 ICC_IC_2: 8 ICC
 SG_ STAT_AMPAlarm : 7|6@0+ (1,0) [0|63] ""  EAMP

BO_ 1324 FRZCU_7: 8 FLZCU
 SG_ TirePositionWarning_LHFTire : 18|3@0+ (1,0) [0|7] ""  ICC
 SG_ TirePositionWarning_RHFTire : 21|3@0+ (1,0) [0|7] ""  ICC
 SG_ TirePositionWarning_LHRTire : 26|3@0+ (1,0) [0|7] ""  ICC
 SG_ TirePositionWarning_RHRTire : 29|3@0+ (1,0) [0|7] ""  ICC
 SG_ TirePressureWarningLampSts : 31|2@0+ (1,0) [0|3] ""  ICC
 SG_ TirePressureSystemFailSts : 32|1@0+ (1,0) [0|1] ""  ICC

BO_ 1326 ICC_BD_36: 8 ICC
 SG_ ICC_DWDOnOff_Req : 17|2@0+ (1,0) [0|3] ""  FLZCU
 SG_ ICC_ContainerLightSet : 19|2@0+ (1,0) [0|3] ""  FLZCU

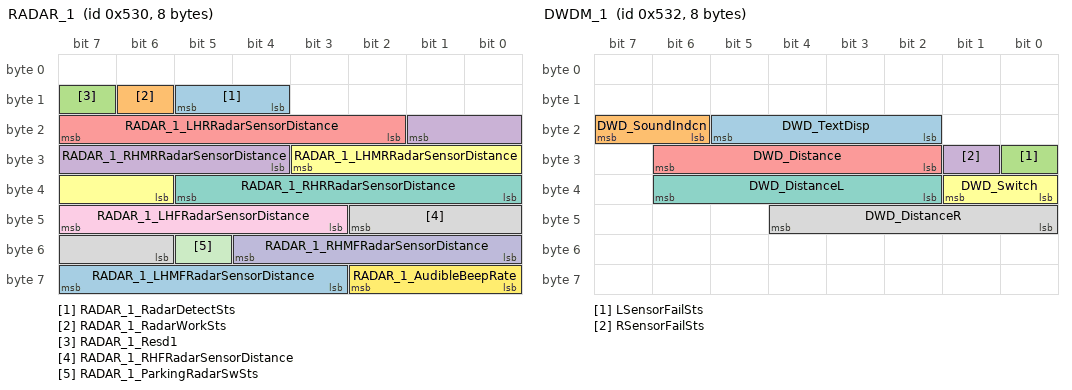
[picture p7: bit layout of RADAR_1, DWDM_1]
BO_ 1328 RADAR_1: 8 FLZCU
 SG_ RADAR_1_RadarDetectSts : 13|2@0+ (1,0) [0|3] ""  ICC
 SG_ RADAR_1_RadarWorkSts : 14|1@0+ (1,0) [0|1] ""  ICC
 SG_ RADAR_1_Resd1 : 15|1@0+ (1,0) [0|1] ""  ICC
 SG_ RADAR_1_RHMRRadarSensorDistance : 17|6@0+ (5,25) [25|180] "Cm"  ICC
 SG_ RADAR_1_LHRRadarSensorDistance : 23|6@0+ (5,25) [25|180] "Cm"  ICC
 SG_ RADAR_1_LHMRRadarSensorDistance : 27|6@0+ (5,25) [25|180] "Cm"  ICC
 SG_ RADAR_1_RHRRadarSensorDistance : 37|6@0+ (5,25) [25|180] "Cm"  ICC
 SG_ RADAR_1_RHFRadarSensorDistance : 42|5@0+ (5,25) [25|160] "Cm"  ICC
 SG_ RADAR_1_LHFRadarSensorDistance : 47|5@0+ (5,25) [25|160] "Cm"  ICC
 SG_ RADAR_1_RHMFRadarSensorDistance : 52|5@0+ (5,25) [25|160] "Cm"  ICC
 SG_ RADAR_1_ParkingRadarSwSts : 53|1@0+ (1,0) [0|1] ""  ICC
 SG_ RADAR_1_AudibleBeepRate : 58|3@0+ (1,0) [0|7] ""  ICC
 SG_ RADAR_1_LHMFRadarSensorDistance : 63|5@0+ (5,25) [25|160] "Cm"  ICC

BO_ 1330 DWDM_1: 8 FLZCU
 SG_ DWD_TextDisp : 21|4@0+ (1,0) [0|15] ""  ICC
 SG_ DWD_SoundIndcn : 23|2@0+ (1,0) [0|3] ""  ICC
 SG_ LSensorFailSts : 24|1@0+ (1,0) [0|1] ""  ICC
 SG_ RSensorFailSts : 25|1@0+ (1,0) [0|1] ""  ICC
 SG_ DWD_Distance : 30|5@0+ (1,0) [0|31] ""  ICC
 SG_ DWD_Switch : 33|2@0+ (1,0) [0|3] ""  ICC
 SG_ DWD_DistanceL : 38|5@0+ (1,0) [0|31] ""  ICC
 SG_ DWD_DistanceR : 44|5@0+ (1,0) [0|31] ""  ICC

BO_ 1331 ICC_IC_37: 32 ICC
 SG_ Set_AMPSoundEffectSupTreble : 147|4@0+ (1,0) [0|15] ""  EAMP,FLZCU
 SG_ ICC_RLSeatEasyEntryExitSet : 17|2@0+ (1,0) [0|3] ""  BBCM,FLZCU,PCL
 SG_ ICC_RRSeatEasyEntryExitSet : 19|2@0+ (1,0) [0|3] ""  BBCM,FLZCU,PCL
 SG_ ICC_RLMemoryRecoveryCmd : 21|2@0+ (1,0) [0|3] ""  BBCM,FLZCU,PCL
 SG_ ICC_RRMemoryRecoveryCmd : 23|2@0+ (1,0) [0|3] ""  BBCM,FLZCU,PCL
 SG_ ICC_RLSitPosnlocation : 25|2@0+ (1,0) [0|3] ""  BBCM,FLZCU,PCL
 SG_ ICC_RRSitPosnlocation : 27|2@0+ (1,0) [0|3] ""  BBCM,FLZCU,PCL
 SG_ ICC_CMSMDisplaySwitch : 29|2@0+ (1,0) [0|3] ""  CMSM,FLZCU
 SG_ ICC_CMSMDisplayAdjustmode : 31|2@0+ (1,0) [0|3] ""  CMSM,FLZCU
 SG_ ICC_CMSMSetstandardSwitch : 33|2@0+ (1,0) [0|3] ""  CMSM,FLZCU
 SG_ ICC_LeftPedalControl : 35|2@0+ (1,0) [0|3] ""  EPC,FLZCU
 SG_ ICC_RightPedalControl : 37|2@0+ (1,0) [0|3] ""  EPC,FLZCU
 SG_ ICC_EPCEnable : 39|2@0+ (1,0) [0|3] ""  EPC,FLZCU
 SG_ ICC_AMPKTVvoiceVolumeSet : 45|6@0+ (1,0) [0|63] ""  EAMP,FLZCU
 SG_ ICC_AMPA2BENCSoundReq : 47|2@0+ (1,0) [0|3] ""  EAMP,FLZCU
 SG_ ICC_AMPENCVolumeSet : 53|6@0+ (1,0) [0|63] ""  EAMP,FLZCU
 SG_ ICC_AMPA2BChimeSoundReq : 55|2@0+ (1,0) [0|3] ""  EAMP,FLZCU
 SG_ ICC_AMPA2BKTVvoiceSoundReq : 58|3@0+ (1,0) [0|7] ""  EAMP,FLZCU
 SG_ Set_AMPSoundFocus_2 : 63|4@0+ (1,0) [0|15] ""  EAMP,FLZCU
 SG_ ICC_MedStatusSet : 81|2@0+ (1,0) [0|3] ""  FLZCU
 SG_ Set_AMPLoudness : 83|2@0+ (1,0) [0|3] ""  FLZCU
 SG_ ICC_MedAreaSet : 87|4@0+ (1,0) [0|15] ""  BBCM,FLZCU,PCL
 SG_ ICC_LeftElectricPedalsSet : 89|2@0+ (1,0) [0|3] ""  EPC,FLZCU
 SG_ ICC_RightElectricPedalsSet : 91|2@0+ (1,0) [0|3] ""  EPC,FLZCU
 SG_ ICC_NapAreaSet2 : 95|3@0+ (1,0) [0|7] ""  BBCM,FLZCU,PCL
 SG_ ICC_DisplayAdjustrAngReq : 103|8@0+ (1,0) [0|255] "°"  CMSM,FLZCU
 SG_ Set_AMPExSoundmode : 113|3@0+ (1,0) [0|7] ""  EAMP,FLZCU
 SG_ Set_AMPKeyVolume : 119|6@0+ (1,0) [0|63] ""  EAMP,FLZCU
 SG_ ICC_CMSMTouchSts : 123|2@0+ (1,0) [0|3] ""  CMSM,FLZCU
 SG_ Set_AMPA2BENCSound : 126|3@0+ (1,0) [0|7] ""  EAMP,FLZCU

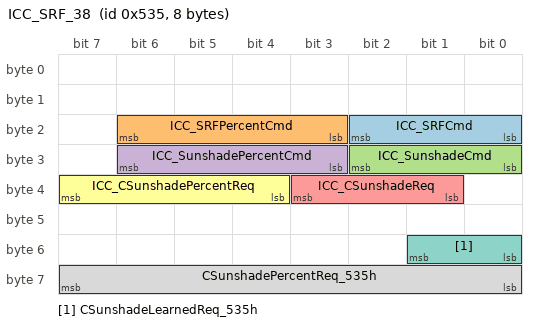
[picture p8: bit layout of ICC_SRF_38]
BO_ 1333 ICC_SRF_38: 8 ICC
 SG_ ICC_SRFCmd : 18|3@0+ (1,0) [0|7] ""  FLZCU
 SG_ ICC_SRFPercentCmd : 22|4@0+ (1,0) [0|15] ""  FLZCU
 SG_ ICC_SunshadeCmd : 26|3@0+ (1,0) [0|7] ""  FLZCU
 SG_ ICC_SunshadePercentCmd : 30|4@0+ (1,0) [0|15] ""  FLZCU
 SG_ ICC_CSunshadeReq : 35|3@0+ (1,0) [0|7] ""  FLZCU
 SG_ ICC_CSunshadePercentReq : 39|4@0+ (1,0) [0|15] ""  FLZCU
 SG_ CSunshadeLearnedReq_535h : 49|2@0+ (1,0) [0|3] ""  FLZCU
 SG_ CSunshadePercentReq_535h : 63|8@0+ (1,0) [0|255] "%"  FLZCU

BO_ 1335 ICC_CH_39: 32 ICC
 SG_ ICC_SET_EPS_SteerReturnRmdSts : 17|2@0+ (1,0) [0|3] ""  FLZCU
 SG_ ICC_SET_MFSShake : 19|2@0+ (1,0) [0|3] ""  FLZCU
 SG_ ICC_DMS_1_DistractionLevel : 22|3@0+ (1,0) [0|7] ""  FLZCU
 SG_ ICC_SET_EPS_AsociWithDrvModSts : 25|2@0+ (1,0) [0|3] ""  FLZCU
 SG_ ICC_OverLoadWarnShieldSet : 27|2@0+ (1,0) [0|3] ""  FLZCU
 SG_ ICC_BSWReq : 29|2@0+ (1,0) [0|3] ""  FLZCU
 SG_ ICC_horizontalReq : 31|2@0+ (1,0) [0|3] ""  FLZCU
 SG_ ICC_RolloverSetCmd : 33|2@0+ (1,0) [0|3] ""  FLZCU
 SG_ ICC_TrekThroughReq_537h : 35|2@0+ (1,0) [0|3] ""  FLZCU
 SG_ ICC_InflateReq_537h : 37|2@0+ (1,0) [0|3] ""  FLZCU
 SG_ ICC_UndergroundModeReq_537h : 39|2@0+ (1,0) [0|3] ""  FLZCU
 SG_ ICC_SandABSSw_537h : 41|2@0+ (1,0) [0|3] ""  FLZCU
 SG_ ICC_SandABSCmd_537h : 43|2@0+ (1,0) [0|3] ""  FLZCU
 SG_ ICC_EPBAUTOCmd_537h : 45|2@0+ (1,0) [0|3] ""  FLZCU
 SG_ ICC_SpeParkSet_537h : 47|2@0+ (1,0) [0|3] ""  FLZCU

BO_ 1337 ICC_TMS_40: 16 ICC
 SG_ ICC_SET_BT_ReduceWindSpeed : 17|2@0+ (1,0) [0|3] ""  FLZCU
 SG_ ICC_SET_IPM_FirstBlowing : 19|2@0+ (1,0) [0|3] ""  FLZCU
 SG_ ICC_SET_IPM_BlowerDelay : 21|2@0+ (1,0) [0|3] ""  FLZCU
 SG_ ICC_SET_CirculationInTunnels : 23|2@0+ (1,0) [0|3] ""  FLZCU
 SG_ ICC_UVCLuminanceReq : 25|2@0+ (1,0) [0|3] ""  FLZCU
 SG_ ICC_UVCControlReq : 27|2@0+ (1,0) [0|3] ""  FLZCU
 SG_ ICC_CrossCountryCoolingReq : 29|2@0+ (1,0) [0|3] ""  FLZCU
 SG_ ICC_KeepWarmReq : 31|2@0+ (1,0) [0|3] ""  FLZCU
 SG_ ICC_keepwarmSetTemperatureReq : 39|8@0+ (1,0) [0|255] ""  FLZCU
 SG_ ICC_ParkingAirConditioning : 41|2@0+ (1,0) [0|3] ""  FLZCU
 SG_ ICC_CoolantFill_Req : 43|2@0+ (1,0) [0|3] ""  FLZCU
 SG_ ICC_FraganceLightoffReq : 45|2@0+ (1,0) [0|3] ""  FLZCU
 SG_ ICC_FraganceMemoffReq : 47|2@0+ (1,0) [0|3] ""  FLZCU
 SG_ ICC_TimingLevel : 50|3@0+ (1,0) [0|7] ""  FLZCU
 SG_ ICC_CFSCycleLevel : 53|3@0+ (1,0) [0|7] ""  FLZCU
 SG_ ICC_AirPurgeReminderReq : 55|2@0+ (1,0) [0|3] ""  FLZCU
 SG_ ICC_TimedVentilationReq : 57|2@0+ (1,0) [0|3] ""  FLZCU
 SG_ ICC_BiochemicalFuncReq : 59|2@0+ (1,0) [0|3] ""  FLZCU
 SG_ ICC_ModeAdjustDisplaySts : 63|4@0+ (1,0) [0|15] ""  FLZCU
 SG_ ICC_PetModeSetTemperature_R_C : 82|5@0+ (0.5,15.5) [15.5|30.5] "℃"  FLZCU
 SG_ ICC_PetmodeSetTemperature_L_C : 87|5@0+ (0.5,15.5) [15.5|30.5] "℃"  FLZCU
 SG_ ICC_PetModeSetCirculationSts : 89|2@0+ (1,0) [0|3] ""  FLZCU
 SG_ ICC_PetModeSetAutoKeySts : 91|2@0+ (1,0) [0|3] ""  FLZCU
 SG_ ICC_PetModeSetCLMOn : 93|2@0+ (1,0) [0|3] ""  FLZCU
 SG_ ICC_ISSFctCmd_539h : 97|2@0+ (1,0) [0|3] ""  FLZCU

BO_ 1338 FMCU_1_G: 8 FLZCU
 SG_ FMCU_ErrLvlDis : 19|3@0+ (1,0) [0|7] ""  ICC
 SG_ FMCU_SpdAct_EDR : 39|16@0+ (1,-32767) [-32767|32766] "rpm"  ICC

BO_ 1341 BMS_44: 48 FLZCU
 SG_ BMS_44_PackPowerRealTime : 23|15@0+ (0.1,-1024) [-1024|1024] "kW"  ICC

BO_ 1345 DVR_1: 16 DVR
 SG_ DVR_1_DVRFailReasons : 20|3@0+ (1,0) [0|7] ""  ICC
 SG_ DVR_1_RecordSts : 22|2@0+ (1,0) [0|3] ""  ICC
 SG_ DVR_1_Sdcard_Sts : 26|3@0+ (1,0) [0|7] ""  ICC

BO_ 1349 SBOX_MSD_1: 16 SBOX
 SG_ SBOX_MSD_Res : 3|4@0+ (1,0) [0|15] ""  ICC
 SG_ SBOX_Ecallphonenub_Res : 7|4@0+ (1,0) [0|15] ""  ICC

BO_ 1351 SBOX_CFG_3: 32 SBOX
 SG_ SBOX_SetMsgTotal : 15|16@0+ (1,0) [0|1000] ""  ICC
 SG_ SBOX_SetMSDTotal : 31|16@0+ (1,0) [0|1000] ""  ICC
 SG_ SBOX_SetCallTimeThreshold : 55|16@0+ (1,0) [0|65535] "min"  ICC
 SG_ SBOX_SetTodayCallTimeThreshold : 71|16@0+ (1,0) [0|65535] "min"  ICC
 SG_ SBOX_SetCurretnCallTime : 87|16@0+ (1,0) [0|65535] "min"  ICC
 SG_ SBOX_SetCurretnMsgThreshold : 103|16@0+ (1,0) [0|1000] ""  ICC
 SG_ SBOX_SetMsgTotalThreshold : 119|16@0+ (1,0) [0|1000] ""  ICC
 SG_ SBOX_SetMsdThreshold : 135|16@0+ (1,0) [0|1000] ""  ICC
 SG_ SBOX_SetCurrenMsdCnt : 151|16@0+ (1,0) [0|1000] ""  ICC
 SG_ SBOX_SetCustomMsgThreshold : 167|16@0+ (1,0) [0|1000] ""  ICC
 SG_ SBOX_SetCurrentCustomMsgCnt : 183|16@0+ (1,0) [0|1000] ""  ICC

BO_ 1353 SBOX_CFG_4: 16 SBOX
 SG_ SBOX_ICC_MACReq : 0|1@0+ (1,0) [0|1] ""  ICC
 SG_ SBOX_MAC_Req0 : 15|8@0+ (1,0) [0|255] ""  ICC
 SG_ SBOX_MAC_Req1 : 23|8@0+ (1,0) [0|255] ""  ICC
 SG_ SBOX_MAC_Req2 : 31|8@0+ (1,0) [0|255] ""  ICC
 SG_ SBOX_MAC_Req3 : 39|8@0+ (1,0) [0|255] ""  ICC
 SG_ SBOX_MAC_Req4 : 47|8@0+ (1,0) [0|255] ""  ICC
 SG_ SBOX_MAC_Req5 : 55|8@0+ (1,0) [0|255] ""  ICC

BO_ 1354 ICC_CFG_46: 32 ICC
 SG_ ICC_SetMsgTotal : 15|16@0+ (1,0) [0|1000] ""  SBOX
 SG_ ICC_SetMSDTotal : 31|16@0+ (1,0) [0|1000] ""  SBOX
 SG_ ICC_SetCallTimeThreshold : 55|16@0+ (1,0) [0|65535] "min"  SBOX
 SG_ ICC_SetTodayCallTimeThreshold : 71|16@0+ (1,0) [0|65535] "min"  SBOX
 SG_ ICC_SetCurretnCallTime : 87|16@0+ (1,0) [0|65535] "min"  SBOX
 SG_ ICC_SetCurretnMsgThreshold : 103|16@0+ (1,0) [0|1000] ""  SBOX
 SG_ ICC_SetMsgTotalThreshold : 119|16@0+ (1,0) [0|1000] ""  SBOX
 SG_ ICC_SetMsdThreshold : 135|16@0+ (1,0) [0|1000] ""  SBOX
 SG_ ICC_SetCurrenMsdCnt : 151|16@0+ (1,0) [0|1000] ""  SBOX
 SG_ ICC_SetCustomMsgThreshold : 167|16@0+ (1,0) [0|1000] ""  SBOX
 SG_ ICC_SetCurrentCustomMsgCnt : 183|16@0+ (1,0) [0|1000] ""  SBOX

BO_ 1356 ICC_CFG_47: 32 ICC
 SG_ ICC_flag : 1|2@0+ (1,0) [0|3] ""  SBOX
 SG_ ICC_ActiveTsp_Req : 3|2@0+ (1,0) [0|3] ""  SBOX
 SG_ ICC_ActiveSim_Req : 5|2@0+ (1,0) [0|3] ""  SBOX
 SG_ ICC_GetMac_req : 6|1@0+ (1,0) [0|1] ""  SBOX
 SG_ ICC_GetIccid_Vin : 7|1@0+ (1,0) [0|1] ""  SBOX
 SG_ ICC_Platform_Phonenub1 : 11|4@0+ (1,0) [0|9] ""  SBOX
 SG_ ICC_Platform_Phonenub2 : 15|4@0+ (1,0) [0|9] ""  SBOX
 SG_ ICC_Platform_Phonenub3 : 19|4@0+ (1,0) [0|9] ""  SBOX
 SG_ ICC_Platform_Phonenub4 : 23|4@0+ (1,0) [0|9] ""  SBOX
 SG_ ICC_Platform_Phonenub5 : 27|4@0+ (1,0) [0|9] ""  SBOX
 SG_ ICC_Platform_Phonenub6 : 31|4@0+ (1,0) [0|9] ""  SBOX
 SG_ ICC_Platform_Phonenub7 : 35|4@0+ (1,0) [0|9] ""  SBOX
 SG_ ICC_Platform_Phonenub8 : 39|4@0+ (1,0) [0|9] ""  SBOX
 SG_ ICC_Platform_Phonenub9 : 43|4@0+ (1,0) [0|9] ""  SBOX
 SG_ ICC_Platform_Phonenub10 : 47|4@0+ (1,0) [0|9] ""  SBOX
 SG_ ICC_Platform_Phonenub11 : 51|4@0+ (1,0) [0|9] ""  SBOX
 SG_ ICC_Platform_Phonenub12 : 55|4@0+ (1,0) [0|9] ""  SBOX
 SG_ ICC_Platform_Phonenub13 : 59|4@0+ (1,0) [0|9] ""  SBOX
 SG_ ICC_Platform_Phonenub14 : 63|4@0+ (1,0) [0|9] ""  SBOX
 SG_ ICC_Platform_Phonenub15 : 67|4@0+ (1,0) [0|9] ""  SBOX
 SG_ ICC_Platform_Phonenub16 : 71|4@0+ (1,0) [0|9] ""  SBOX
 SG_ ICC_Platform_Phonenub17 : 75|4@0+ (1,0) [0|9] ""  SBOX
 SG_ ICC_Platform_Phonenub18 : 79|4@0+ (1,0) [0|9] ""  SBOX
 SG_ ICC_Platform_Phonenub19 : 83|4@0+ (1,0) [0|9] ""  SBOX
 SG_ ICC_Platform_Phonenub20 : 87|4@0+ (1,0) [0|9] ""  SBOX
 SG_ ICC_Mac0 : 95|8@0+ (1,0) [0|255] ""  SBOX
 SG_ ICC_Mac1 : 103|8@0+ (1,0) [0|255] ""  SBOX
 SG_ ICC_Mac2 : 111|8@0+ (1,0) [0|255] ""  SBOX
 SG_ ICC_Mac3 : 119|8@0+ (1,0) [0|255] ""  SBOX
 SG_ ICC_Mac4 : 127|8@0+ (1,0) [0|255] ""  SBOX
 SG_ ICC_Mac5 : 135|8@0+ (1,0) [0|255] ""  SBOX
 SG_ ICC_GivePlatformNumber_Flag : 248|1@0+ (1,0) [0|1] ""  SBOX
 SG_ ICC_Mac_Flag : 249|1@0+ (1,0) [0|1] ""  SBOX

BO_ 1358 SBOX_CFG_5: 64 SBOX
 SG_ SBOX_ActiveTsp_Res : 0|1@0+ (1,0) [0|1] ""  ICC
 SG_ SBOX_ActiveSim_Res : 1|1@0+ (1,0) [0|1] ""  ICC
 SG_ SBOX_GetPlatformNumberRes : 2|1@0+ (1,0) [0|1] ""  ICC
 SG_ SBOX_Mac_Res0 : 15|8@0+ (1,0) [0|255] ""  ICC
 SG_ SBOX_Mac_Res1 : 23|8@0+ (1,0) [0|255] ""  ICC
 SG_ SBOX_Mac_Res2 : 31|8@0+ (1,0) [0|255] ""  ICC
 SG_ SBOX_Mac_Res3 : 39|8@0+ (1,0) [0|255] ""  ICC
 SG_ SBOX_Mac_Res4 : 47|8@0+ (1,0) [0|255] ""  ICC
 SG_ SBOX_Mac_Res5 : 55|8@0+ (1,0) [0|255] ""  ICC
 SG_ SBOX_ICCId_Res0 : 99|4@0+ (1,0) [0|9] ""  ICC
 SG_ SBOX_ICCId_Res1 : 103|4@0+ (1,0) [0|9] ""  ICC
 SG_ SBOX_ICCId_Res2 : 107|4@0+ (1,0) [0|9] ""  ICC
 SG_ SBOX_ICCId_Res3 : 111|4@0+ (1,0) [0|9] ""  ICC
 SG_ SBOX_ICCId_Res4 : 115|4@0+ (1,0) [0|9] ""  ICC
 SG_ SBOX_ICCId_Res5 : 119|4@0+ (1,0) [0|9] ""  ICC
 SG_ SBOX_ICCId_Res6 : 123|4@0+ (1,0) [0|9] ""  ICC
 SG_ SBOX_ICCId_Res7 : 127|4@0+ (1,0) [0|9] ""  ICC
 SG_ SBOX_ICCId_Res8 : 131|4@0+ (1,0) [0|9] ""  ICC
 SG_ SBOX_ICCId_Res9 : 135|4@0+ (1,0) [0|9] ""  ICC
 SG_ SBOX_ICCId_Res10 : 139|4@0+ (1,0) [0|9] ""  ICC
 SG_ SBOX_ICCId_Res11 : 143|4@0+ (1,0) [0|9] ""  ICC
 SG_ SBOX_ICCId_Res12 : 147|4@0+ (1,0) [0|9] ""  ICC
 SG_ SBOX_ICCId_Res13 : 151|4@0+ (1,0) [0|9] ""  ICC
 SG_ SBOX_ICCId_Res14 : 155|4@0+ (1,0) [0|9] ""  ICC
 SG_ SBOX_ICCId_Res15 : 159|4@0+ (1,0) [0|9] ""  ICC
 SG_ SBOX_ICCId_Res16 : 163|4@0+ (1,0) [0|9] ""  ICC
 SG_ SBOX_ICCId_Res17 : 167|4@0+ (1,0) [0|9] ""  ICC
 SG_ SBOX_ICCId_Res18 : 171|4@0+ (1,0) [0|9] ""  ICC
 SG_ SBOX_ICCId_Res19 : 175|4@0+ (1,0) [0|9] ""  ICC
 SG_ SBOX_Vin0 : 183|8@0+ (1,0) [0|90] ""  ICC
 SG_ SBOX_Vin1 : 191|8@0+ (1,0) [0|90] ""  ICC
 SG_ SBOX_Vin2 : 199|8@0+ (1,0) [0|90] ""  ICC
 SG_ SBOX_Vin3 : 207|8@0+ (1,0) [0|90] ""  ICC
 SG_ SBOX_Vin4 : 215|8@0+ (1,0) [0|90] ""  ICC
 SG_ SBOX_Vin5 : 223|8@0+ (1,0) [0|90] ""  ICC
 SG_ SBOX_Vin6 : 231|8@0+ (1,0) [0|90] ""  ICC
 SG_ SBOX_Vin7 : 239|8@0+ (1,0) [0|90] ""  ICC
 SG_ SBOX_Vin8 : 247|8@0+ (1,0) [0|90] ""  ICC
 SG_ SBOX_Vin9 : 255|8@0+ (1,0) [0|90] ""  ICC
 SG_ SBOX_Vin10 : 263|8@0+ (1,0) [0|90] ""  ICC
 SG_ SBOX_Vin11 : 271|8@0+ (1,0) [0|90] ""  ICC
 SG_ SBOX_Vin12 : 279|8@0+ (1,0) [0|90] ""  ICC
 SG_ SBOX_Vin13 : 287|8@0+ (1,0) [0|90] ""  ICC
 SG_ SBOX_Vin14 : 295|8@0+ (1,0) [0|90] ""  ICC
 SG_ SBOX_Vin15 : 303|8@0+ (1,0) [0|90] ""  ICC
 SG_ SBOX_Vin16 : 311|8@0+ (1,0) [0|90] ""  ICC

BO_ 1360 ICC_LC_42: 64 ICC
 SG_ ICC_LISD_DisplaySwitch : 1|2@0+ (1,0) [0|3] ""  FLZCU
 SG_ ICC_LISD_ParkingShowCMD : 3|2@0+ (1,0) [0|3] ""  FLZCU
 SG_ ICC_RISD_DisplaySwitch : 7|2@0+ (1,0) [0|3] ""  FLZCU
 SG_ ICC_RISD_ParkingShowCMD : 9|2@0+ (1,0) [0|3] ""  FLZCU
 SG_ ICC_LogoParkingReq : 13|2@0+ (1,0) [0|3] ""  FLZCU
 SG_ ICC_LogoChargingReq : 15|2@0+ (1,0) [0|3] ""  FLZCU
 SG_ ICC_DRLSw : 17|2@0+ (1,0) [0|3] ""  FLZCU
 SG_ ICC_LISD_ParkingShowMod : 27|4@0+ (1,0) [0|15] ""  FLZCU
 SG_ ICC_RISD_ParkingShowMod : 31|4@0+ (1,0) [0|15] ""  FLZCU
 SG_ ICC_LogoColorReq : 33|9@0+ (1,0) [0|511] ""  FLZCU
 SG_ ICC_MusicLampShowSW : 35|2@0+ (1,0) [0|3] ""  FLZCU
 SG_ ICC_PenetrationLampSetF : 37|2@0+ (1,0) [0|3] ""  FLZCU
 SG_ ICC_XDriveMode : 40|5@0+ (1,0) [0|31] ""  FLZCU
 SG_ ICC_DowWaringSw : 57|2@0+ (1,0) [0|3] ""  FLZCU
 SG_ ICC_CarSearhSetSwitchSts : 59|2@0+ (1,0) [0|3] ""  FLZCU
 SG_ ICC_TDL_NightBright_SW_550h : 61|2@0+ (1,0) [0|3] ""  FLZCU

BO_ 1361 EPC_1: 64 EPC
 SG_ EPC_LeftPedalSystem_Sts : 27|4@0+ (1,0) [0|15] ""  ICC
 SG_ EPC_RightPedalSystem_Sts : 31|4@0+ (1,0) [0|15] ""  ICC
 SG_ EPC_LeftPedalTimeTravel : 39|8@0+ (1,0) [0|100] "%"  ICC
 SG_ EPC_RightPedalTimeTravel : 47|8@0+ (1,0) [0|100] "%"  ICC
 SG_ EPC_RightPedalRealTime_Sts : 50|3@0+ (1,0) [0|7] ""  ICC
 SG_ EPC_LeftPedalBreakIce_Sts : 52|2@0+ (1,0) [0|3] ""  ICC
 SG_ EPC_LeftPedalRealTime_Sts : 55|3@0+ (1,0) [0|7] ""  ICC
 SG_ EPC_RightPedalCmdStatus : 57|2@0+ (1,0) [0|3] ""  ICC
 SG_ EPC_LeftPedalCmdStatus : 59|2@0+ (1,0) [0|3] ""  ICC
 SG_ EPC_Enable_CmdStatus : 61|2@0+ (1,0) [0|3] ""  ICC
 SG_ EPC_RightPedalBreakIce_Sts : 63|2@0+ (1,0) [0|3] ""  ICC
 SG_ EPC_RightPedal3D_Sts : 253|2@0+ (1,0) [0|3] ""  ICC
 SG_ EPC_LeftPedal3D_Sts : 255|2@0+ (1,0) [0|3] ""  ICC

BO_TX_BU_ 1310 : SCU,BBCM;
CM_ SG_ 1265 ICC_PwrOff "车辆下电";
CM_ SG_ 1265 ICC_EtmEgySave "极致节能模式";
CM_ SG_ 1265 ICC_HoodSW "前舱盖开关";
CM_ SG_ 1265 ICC_GloveboxSW "手套箱开关";
CM_ SG_ 1265 ICC_ChrgPortCover_Switch "充电口盖开关";
CM_ SG_ 1265 ICC_ReWinDefrstSwt "Rear window defrost后风窗加热";
CM_ SG_ 1265 ICC_RearMirrorFoldCmd "后视镜手动折叠开关";
CM_ SG_ 1265 ICC_CenterLockSwt "CenterLock中控锁开关";
CM_ SG_ 1265 ICC_ReverseExtMirrorSts "DVD设置倒车外后视镜下翻功能开启";
CM_ SG_ 1265 ICC_LightMainSwitchSts "小灯、近光、Auto开关";
CM_ SG_ 1265 ICC_AutoFoldSts "后视镜自动折叠";
CM_ SG_ 1265 ICC_HeadlampHeightSts "大灯高度调节设置信号";
CM_ SG_ 1265 ICC_WiprSnvty "WiperSensitivity雨刮灵敏度";
CM_ SG_ 1265 ICC_WindowCmd "语音控制车窗指令：
1、包含对左前车窗、右前车窗、左后车窗、右后车窗、前排车窗、后排车窗、全部车窗的指令控制；
2、具备open（打开）、close（关闭）、comfort（通风）三种动作指令，目前只有同时控制四个车窗时有comfort指令。
3、没有此功能，其他信号触发此帧报文发送时，此信号发“Not active”；";
CM_ SG_ 1265 ICC_LowBeamDelayOff "大灯延迟关闭开关";
CM_ SG_ 1265 DrvWinCmd_4F1h "玻璃升降防夹（霍尔、纹波）主驾窗";
CM_ SG_ 1265 PassWinCmd_4F1h "玻璃升降防夹（霍尔、纹波）副驾窗";
CM_ SG_ 1265 DrvRearWinCmd_4F1h "玻璃升降防夹（霍尔、纹波）主驾后窗";
CM_ SG_ 1265 PassRearWinCmd_4F1h "玻璃升降防夹（霍尔、纹波）副驾后窗";
CM_ SG_ 1265 ICC_FGHeatSts "设置前挡风加热";
CM_ SG_ 1265 ICC_AutolockSts "设置自动落锁模式";
CM_ SG_ 1265 ICC_WiperID "雨刮ID";
CM_ SG_ 1265 ICC_MaintenanceMode "雨刮维修模式开关";
CM_ SG_ 1265 ICC_lockSetSwitchSts "解闭锁设置";
CM_ SG_ 1265 ICC_ChildLockSW "儿童锁开关";
CM_ SG_ 1265 ICC_ParkUnlockEnable "驻车解锁设置";
CM_ SG_ 1265 ICC_BLEOpenDriverDoorEnable "蓝牙靠近开门设置";
CM_ SG_ 1265 ICC_WinInhbSwt "Window Inhibit 玻璃禁止开关";
CM_ SG_ 1265 ICC_SteerWhlHeatgSwt "Steering Wheel heating方向盘加热";
CM_ SG_ 1265 ICC_AutoHeatingset "后视镜自动加热设置";
CM_ SG_ 1265 ICC_FrontFogSw "屏内前雾灯开关";
CM_ SG_ 1265 ICC_RearFogSw "屏内后雾灯开关";
CM_ SG_ 1265 ICC_DoorControlSW "顶灯门控开关";
CM_ SG_ 1265 ICC_LockCarWinCloseSw "锁车自动升窗开关";
CM_ SG_ 1265 ICC_NapStatusSet "小憩模式开关设置";
CM_ SG_ 1265 ICC_NapAreaSet "小憩模式开启区域设置";
CM_ SG_ 1265 ICC_EasyEntryExitSet "便捷进入\离车";
CM_ SG_ 1265 ICC_RainCarWinCloseSw "雨天自动升窗开关";
CM_ SG_ 1265 ICC_NapTimeSet "小憩模式时长设置
0x0:Not Active";
CM_ SG_ 1265 ICC_NapSetTemperature "小憩模式设置空调温度";
CM_ SG_ 1265 ICC_NapCFSStatusSet "小憩模式香氛系统开关设置";
CM_ SG_ 1265 ICC_HazardLightReq "双闪灯请求";
CM_ SG_ 1265 ICC_SpoilerCtrlCmd "电动尾翼控制设置";
CM_ SG_ 1265 ICC_SpoilerWelcomeFunSet "电动尾翼迎宾功能设置";
CM_ SG_ 1265 ICC_CinemaStatus "影院模式状态";
CM_ SG_ 1265 ICC_MusicStatus "K歌模式状态";
CM_ BO_ 1267 "报文路由（捷途域控控制BSD灯）";
CM_ SG_ 1267 RRCR_1_CRC1 "Profile1A:E2E CRC (SAE J1850 CRC-8) for 8 Bytes
DataID:0x0046";
CM_ SG_ 1267 RRCR_1_RollgCntr1 "Profile1A:E2E Rolling message counter(the maximum value of Alive counter is 14)";
CM_ SG_ 1267 RRCR_1_Resd1 "Profile1A:E2E Reserved";
CM_ SG_ 1267 RRCR_1_SysSt "System self-test State";
CM_ SG_ 1267 RRCR_1_BlkSts "Blockage Status";
CM_ SG_ 1267 RRCR_1_BSDWarn "BSD/LCA Warning";
CM_ SG_ 1267 RRCR_1_DOWWarn "Door open warning Warning";
CM_ SG_ 1267 RRCR_1_DowLock "Door locking Warning
功能预留，不发";
CM_ SG_ 1269 LISDShowCMDSts "ISD灯光开启状态";
CM_ SG_ 1269 LISDShowModeSts "ISD灯光模式状态";
CM_ SG_ 1269 LISDTransmitStatus "灯具反馈信息：反馈当前数据帧是否接收成功、数据校验是否正确、图片显示是否成功。";
CM_ SG_ 1269 LISDDisplayStatus "灯具反馈信息：反馈当前图片显示状态。";
CM_ SG_ 1269 LISD_ParkingShowModSts "驻车动画状态反馈";
CM_ SG_ 1269 LISD_ParkingShowCMDSts "驻车动画开关反馈";
CM_ SG_ 1271 RRCR_2_CRC1 "Profile1A:E2E CRC (SAE J1850 CRC-8) for 8 Bytes
DataID:0x0047";
CM_ SG_ 1271 RRCR_2_RollgCntr1 "Profile1A:E2E Rolling message counter(the maximum value of Alive counter is 14)";
CM_ SG_ 1271 RRCR_2_Resd1 "Profile1A:E2E Reserved";
CM_ SG_ 1271 RRCR_2_RCWWarn "Rear Collision Warning Warning";
CM_ SG_ 1271 RRCR_2_RCTAWarn "FCTA Warning高配不发";
CM_ SG_ 1271 RRCR_2_BSDLCWONOFFSts "BSD/LCA Switch status";
CM_ SG_ 1271 RRCR_2_DOWONOFFSts "Door open warning Switch status";
CM_ SG_ 1271 RRCR_2_RCWONOFFSts "Rear Collision Warning Switch Status";
CM_ SG_ 1271 RRCR_2_RCTARCTBONOFFSts "RCTA/RCTB Switch status
高配不发
无RCTB功能，开关反馈无0x2";
CM_ SG_ 1273 FaceID "人脸ID";
CM_ SG_ 1273 DrvSeatExtMirPosRecallID_4F9h "主驾座椅位置调出请求";
CM_ SG_ 1273 DrvSeatExtMirPosStoreReqID_4F9h "主驾座椅位置记忆请求";
CM_ SG_ 1276 PassSeatHeiAdjmt_Target "座椅高度调节目标位置（大屏调节请求）";
CM_ SG_ 1276 SeatBackAndFwdAdjmt_Target "座椅水平调节目标值（大屏调节请求）";
CM_ SG_ 1276 SeatBackAgAdjmt_Target "座椅靠背角度调节目标值（大屏调节请求）";
CM_ SG_ 1276 Set_ProfileID "Set personalization profile ID number（记忆设置）";
CM_ SG_ 1276 SeatCushAgAdjmt_Target "座椅坐垫角度调节目标值（大屏调节请求）";
CM_ SG_ 1276 LgRstFwdAndBckAdjmt_Target "腿托前后位置目标值（大屏调节请求）";
CM_ SG_ 1276 FootRestAdjmt_Target "脚托调整位置目标值（大屏调节请求）";
CM_ SG_ 1276 REQ_SeatPosRecall "Seat position recall request";
CM_ SG_ 1276 REQ_SeatPosStore "Seat position store request";
CM_ SG_ 1276 Set_ToDefault "IHU setting function";
CM_ SG_ 1276 Set_EasyEntryEnable "Easy entry Set";
CM_ SG_ 1276 REQ_SeatHeatPass "Passenger Seat heating request from head unit";
CM_ SG_ 1276 REQ_SeatVentPass "Passenger Seat venting request from head unit";
CM_ SG_ 1276 PassSeatMsgStr_LvlCmd "0x0:未激活
0x1:关
0x2:低
0x3:中
0x4:高";
CM_ SG_ 1276 PassSeatMsg_ModeCmd "00x0：无动作
0x1:脉冲模式
0x2:波浪模式
0x3:猫步模式
0x4:单排模式
0x5:交叉模式
0x6:蝶形模式
0x7:腰部按摩模式
0x8:蛇形模式
0x9:特殊模式1
0xA:特殊模式2
0xB:特殊模式3
0xC:特殊模式4";
CM_ SG_ 1279 ICC_SentinelModeSts "哨兵模式开启/关闭的状态";
CM_ SG_ 1279 Weather_Type "天气类型
0x1：晴天
0x2：多云
0x3：阴天
0x4：阵雨
0x5：雷阵雨
0x6：雷阵雨夹冰雹
0x7：雨夹雪
0x8：小雨
0x9：中雨
0xA：大雨
0xB：暴风雨
0xF：小雪
0x10：中雪
0x11：大雪
0x12：暴风雪
0x13：雾天
0x15：尘暴
0x1E：尘埃
0x1F：风沙
0x21：雾霾";
CM_ SG_ 1279 ICC_CameraErrorCode "ICC侧Camera链路错误码";
CM_ SG_ 1279 ICC_SentinelRequest "哨兵模式进入，退出请求";
CM_ SG_ 1279 ICC_StartDeInitCameraStream "ICC通知ADCC开始关闭Camera视频流";
CM_ SG_ 1279 ICC_CameraRecoveryRequest "ICC通知ADCC恢复Camera视频链路";
CM_ SG_ 1279 ICC_CleanMode_4FFh "洗车模式(主项目沿用)";
CM_ BO_ 1288 "ICC收到此帧报文后通过ICC_COM_8（0x510）转发出去";
CM_ SG_ 1288 CurrentTimeYear_508h "GPS时间（年）";
CM_ SG_ 1288 CurrentTimeMonth_508h "GPS时间（月）";
CM_ SG_ 1288 CurrentTimeDay_508h "GPS时间（日）";
CM_ SG_ 1288 CurrentTimeHour_508h "GPS时间（时）";
CM_ SG_ 1288 CurrentTimeMinute_508h "GPS时间（分）";
CM_ SG_ 1288 CurrentTimeSecond_508h "GPS时间（秒）";
CM_ SG_ 1289 ICC_ToggleUnits "英制单位切换";
CM_ SG_ 1289 ICC_TireTemperatureDisplayUnit "胎温显示单位";
CM_ SG_ 1289 ICC_TirePressureDisplayUnit "胎压显示单位";
CM_ SG_ 1289 ICC_GPSSwitchSet "GPS定位开关设置";
CM_ SG_ 1289 ICC_BtConFlag "蓝牙连接状态反馈";
CM_ SG_ 1289 ICC_LanguageSet_509h "语言设置信号";
CM_ SG_ 1289 ICC_Day_Displaysts_509h "白天黑夜模式设置：
0x0:白天模式
0x1:黑夜模式";
CM_ SG_ 1290 BMS_8_CRC1 "Profile1A:E2E CRC (SAE J1850 CRC-8) for 8 Bytes
DataID:0x0023";
CM_ SG_ 1290 BMS_8_RollgCntr1 "Profile1A:E2E Rolling message counter(the maximum value of Alive counter is 14)";
CM_ SG_ 1290 BMS_8_Resd1 "Profile1A:E2E Reserved";
CM_ SG_ 1290 BMS_HvBattCellOverU "电池电芯过压故障  
（默认发0，检测到电芯过压时根据阈值发送过压等级)";
CM_ SG_ 1290 BMS_HvBattCellUnderU "电池电芯欠压故障
（默认发0，检测到电芯欠压时根据阈值发送过压等级)";
CM_ SG_ 1290 BMS_HvBattUnderU "电池包总压欠压故障
（默认发0，检测到电池过压时根据阈值发送过压等级)";
CM_ SG_ 1290 BMS_HvBattDischargeOverCurrent "放电过流
（默认发0 检测到放电电流过流时根据阈值发送过流等级)";
CM_ SG_ 1290 BMS_HvBattChargeOverCurrent "充电过流
（默认发0 检测到充电电流过流时根据阈值发送过流等级)";
CM_ SG_ 1290 BMS_HvBattOverU "电池包总压过压故障 
（默认发0，检测到电池过压时根据阈值发送过压等级)";
CM_ SG_ 1290 BMS_HvBattMismatching "电池包不匹配故障";
CM_ SG_ 1290 BMS_HvBattSocJump "SOC跳变故障（默认发0，检测到SOC跳变发1）";
CM_ SG_ 1290 BMS_HvBattCellUUnif "电芯压差过大";
CM_ SG_ 1290 BMS_HvBattLowSoc "SOC过低
（默认发0检测到SOC过低时发1)";
CM_ SG_ 1290 BMS_HvBattOverSoc "SOC过高（默认发0检测到SOC过高时发1)";
CM_ SG_ 1290 BMS_HvBattTempUniformity "电池温差过大（默认发0，检测到电池温差过大故障发1）";
CM_ SG_ 1290 BMS_BattInterCANErr "内部CAN通讯故障  
（当出现：
SCAN总线故障
SCAN BUSOFF故障
菊花链通讯故障
任一故障均发1，默认发0）";
CM_ SG_ 1290 BMS_HvBattOverCharging "电池电压过充故障（默认 发0 检测到电池包过压一级及以上时发1）";
CM_ SG_ 1290 BMS_HvBattOverTemperature "电池过温故障
（默认发0检测到电池包过温时根据阈值发送过温故障等级）";
CM_ SG_ 1291 BMS_2_G_CRC "Profile1A:E2E CRC (SAE J1850 CRC-8) for 8 Bytes
DataID:0x0075";
CM_ SG_ 1291 BMS_2_G_RollgCntr "Profile1A:E2E Rolling message counter(the maximum value of Alive counter is 14)";
CM_ SG_ 1291 BMS_2_G_Resd "Profile1A:E2E Reserved";
CM_ SG_ 1291 BMS_TBOXInsulation_R "insulation resistance";
CM_ SG_ 1291 BMS_TBOXErrorNumber "BMS Error Numbers";
CM_ SG_ 1291 BMS_TBOXHvBattMaxT "battery max temperature";
CM_ SG_ 1291 BMS_TBOXHvBattMinT "battery min temperature";
CM_ SG_ 1291 BMS_SOCLight "BMS SOCLight
SOC电量显示（仪表显示）";
CM_ SG_ 1292 CHB_AppDelay_Sts "延时开关状态/离车持续工作开关状态";
CM_ SG_ 1292 CHB_AppMem_Sts "记忆开关状态";
CM_ SG_ 1292 CHB_App_Sts "冰箱开关状态（捷途预留）";
CM_ SG_ 1292 CHB_AppTimeset_Sts "延时时间设置/离车持续工作时间设置";
CM_ SG_ 1292 CHB_AppCoolorheat_Sts "制冷制热选择状态
冰箱工作模式（捷途使用）
0x0：无请求
0x1：制冷
0x2：制热
0x3：关
0x4：冷饮模式
0x5：冰淇淋模式
0x6：温奶模式
0x7：热饮模式";
CM_ SG_ 1292 CHB_AppCoolset_Sts "制冷温度设置
0x1~0xD:-6℃~6℃（捷途使用）
0xE~0x19:-18℃~-7℃（股份使用，捷途预留）";
CM_ SG_ 1292 CHB_AppHeatset_Sts "制热温度调节设置";
CM_ SG_ 1292 CHB_AppItemsLeft_Sts "物品遗留开关状态";
CM_ SG_ 1292 CHB_AppSterilization_Sts "杀菌开关状态";
CM_ SG_ 1292 CHB_AppChbDoor_Sts "冰箱是门开关状态反馈信号";
CM_ SG_ 1292 CHB_AppItemsLeftset_Sts "冰箱是否检测到物品的状态";
CM_ SG_ 1295 BMS_RemainChg_Time "BMS_RemainChg_Time";
CM_ SG_ 1295 BMS_BattFaultLampSts "高压电池故障灯显示";
CM_ SG_ 1295 BMS_OverTemp_LightSts "BMS_OverTemp_LightSts";
CM_ SG_ 1295 BMS_ThermalRunawayDis "Thermal run-away";
CM_ SG_ 1295 BMS_TBOXIsolationFault "battery insulation fault state";
CM_ SG_ 1295 BMS_PreWarmDis "preheat and keepwarm indication";
CM_ SG_ 1296 CurrentTimeYear "时间（年)";
CM_ SG_ 1296 CurrentTimeMonth "时间（月）";
CM_ SG_ 1296 CurrentTimeDay "时间（日）";
CM_ SG_ 1296 CurrentTimeHour "时间（时）";
CM_ SG_ 1296 CurrentTimeMinute "时间（分）";
CM_ SG_ 1296 CurrentTimeSecond "时间（秒）";
CM_ SG_ 1299 BMS_PackVoltageDis "Battery Voltage";
CM_ SG_ 1299 BMS_PackCurrentDis "Baattery Current(direction:discharge+ charge -)";
CM_ SG_ 1310 DrvSecSeatEasyEntryExitFb_51Eh "二排主驾侧便捷进入\离车";
CM_ SG_ 1310 PassSecSeatEasyEntryExitFb_51Eh "二排副驾便捷进入\离车";
CM_ SG_ 1310 DrvSecSeatNeedMemory_51Eh "二排主驾侧座椅记忆弹框请求";
CM_ SG_ 1310 DrvSecMemoryFb_51Eh "二排左主驾侧记忆保存状态";
CM_ SG_ 1310 DrvSecRecoverFb_51Eh "二排主驾侧记忆恢复状态";
CM_ SG_ 1310 PassSecSeatNeedMemory_51Eh "二排副驾侧座椅记忆弹框请求";
CM_ SG_ 1310 PassSecMemoryFb_51Eh "二排副驾侧记忆保存状态";
CM_ SG_ 1310 PassSecRecoverFb_51Eh "二排副驾侧记忆恢复状态";
CM_ SG_ 1310 DrvSecSeatLvlFb_51Eh "二排主驾侧座椅水平位置
0x0:Not active";
CM_ SG_ 1310 DrvSecSeatBackAgFb_51Eh "二排主驾侧座椅靠背角度位置
0x0:Not active";
CM_ SG_ 1310 DrvSecSeatLegSpprtFb_51Eh "二排主驾侧座椅腿托旋转位置
0x0:Not active";
CM_ SG_ 1310 DrvSecSeatLegRestAngleFb_51Eh "二排主驾侧座椅腿托延伸位置
0x0:Not active";
CM_ SG_ 1310 PassSecSeatLvlFb_51Eh "二排副驾侧座椅水平位置
0x0:Not active";
CM_ SG_ 1310 PassSecSeatBackAgFb_51Eh "二排副驾侧座椅靠背角度位置
0x0:Not active";
CM_ SG_ 1310 PassSecSeatLegSpprtFb_51Eh "二排副驾侧座椅腿托旋转位置
0x0:Not active";
CM_ SG_ 1310 PassSecSeatLegRestAngleFb_51Eh "二排副驾侧座椅腿托延伸位置
0x0:Not active";
CM_ SG_ 1310 DrvTrdSeatBackAgFb_51Eh "三排主驾侧座椅靠背角度位置
0x0:Not active";
CM_ SG_ 1310 PassTrdSeatBackAgFb_51Eh "三排副驾侧座椅靠背角度位置
0x0:Not active";
CM_ SG_ 1310 DrvTrdSeatFrontFlipFb_51Eh "三排主驾侧座椅前翻角度位置
0x0:Not active";
CM_ SG_ 1310 PassTrdSeatFrontFlipFb_51Eh "三排副驾侧座椅前翻角度位置
0x0:Not active";
CM_ SG_ 1310 PassSecSeatExpSwCmd_51Eh "二排副驾侧座椅一键展开/复位执行状态";
CM_ SG_ 1310 PassTrdSeatSwCmd_51Eh "三排副驾侧座椅一键开关调节指令
0x1:靠背折叠
0x2:靠背展开
0x3:坐垫前翻
0x4:坐垫回位";
CM_ SG_ 1310 BBCM_RLSeatSwCmd3rd "三排左侧座椅一键开关调节指令
0x1:靠背折叠
0x2:靠背展开
0x3:坐垫前翻
0x4:坐垫回位";
CM_ SG_ 1310 BBCM_RLSeatExpSwCmd2rd "二排左侧座椅一键展开/复位执行状态（ICC进行提示）";
CM_ SG_ 1310 BBCM_RLSeatExpSwSt2rd "二排左侧座椅一键展开/复位调节指令(FLZCU进行主驾避让)";
CM_ SG_ 1310 PassSecSeatExpSwSt_51Eh "二排副驾侧座椅一键展开/复位调节指令";
CM_ SG_ 1310 BBCM_RRSeatZeroFb2nd "二排右侧座椅零重力位置
0x0:Not active";
CM_ SG_ 1310 BBCM_RLSeatZeroFb2nd "二排左侧座椅零重力位置
0x0:Not active";
CM_ SG_ 1310 BBCM_RLSeatExpRstStsFb "二排左侧座椅是否处于一键展开位置
0x0:不处于一键展开位置
0x1:处于一键展开位置";
CM_ SG_ 1310 PassSecSeatMovFailCause_51Eh "二排副驾侧座椅调节失败原因
0x1:发生防夹
0x2:座椅未学习
0x3:存在故障（电机故障/开关故障/过压/欠压/霍尔丢失）
0x4:二排右侧座椅手动调节开关打断
0x5:三排一键开关打断
0x6:副驾坐人
0x7:三排右侧座椅坐人
0x8:三排右侧座椅不在展开状态
0x9:副驾调节异常中断
0xA:当前处于女王副驾模式中
0xB:优先级不满足
0xC:无当前配置";
CM_ SG_ 1310 DrvSecSeatMovFailCause_51Eh "二排主驾侧座椅调节失败原因
0x1:发生防夹
0x2:座椅未学习
0x3:存在故障（电机故障/开关故障/过压/欠压/霍尔丢失）
0x4:二排左侧座椅手动调节开关打断
0x5:优先级不满足
0x6:无当前配置";
CM_ SG_ 1310 PassTrdSeatMovFailCause_51Eh "三排副驾侧座椅调节失败原因
0x0:Not active
0x1:发生防夹
0x2:座椅未学习
0x3:存在故障（电机故障/开关故障/过压/欠压/霍尔丢失）
0x4:车辆非P挡
0x5:三排右侧座椅坐人
0x6:三排右侧座椅手动开关按键打断
0x7:优先级不满足
0x8:触发防玩保护
0x9:三排右侧靠背未处于折叠状态
0xA:三排右侧座椅坐垫未处于回位状态
0xB:无当前配置";
CM_ SG_ 1310 DrvTrdSeatMovFailCause_51Eh "三排主驾侧座椅调节失败原因
0x0:Not active
0x1:发生防夹
0x2:座椅未学习
0x3:存在故障（电机故障/开关故障/过压/欠压/霍尔丢失）
0x4:车辆非P挡
0x5:三排左侧座椅坐人
0x6:三排左侧座椅手动开关按键打断
0x7:优先级不满足
0x8:触发防玩保护
0x9:三排左侧靠背未处于折叠状态
0xA:三排左侧座椅坐垫未处于回位状态
0xB:无当前配置";
CM_ SG_ 1312 ICC_TotalFaultNum "当前故障总数";
CM_ SG_ 1312 ICC_FrameIndex "帧序号";
CM_ SG_ 1312 ICC_SupplierNum "供应商代码";
CM_ SG_ 1312 ICC_FaultNum1 "故障列表1";
CM_ SG_ 1312 ICC_FaultNum2 "故障列表2";
CM_ SG_ 1312 ICC_FaultNum3 "故障列表3";
CM_ SG_ 1312 ICC_FaultNum4 "故障列表4";
CM_ SG_ 1312 ICC_FaultNum5 "故障列表5";
CM_ SG_ 1312 ICC_FaultNum6 "故障列表6";
CM_ SG_ 1312 ICC_FaultNum7 "故障列表7";
CM_ SG_ 1312 ICC_FaultNum8 "故障列表8";
CM_ SG_ 1312 ICC_FaultNum9 "故障列表9";
CM_ SG_ 1312 ICC_FaultNum10 "故障列表10";
CM_ SG_ 1312 ICC_FaultNum11 "故障列表11";
CM_ SG_ 1312 ICC_FaultNum12 "故障列表12";
CM_ SG_ 1312 ICC_FaultNum13 "故障列表13";
CM_ SG_ 1312 ICC_FaultNum14 "故障列表14";
CM_ SG_ 1312 ICC_FaultNum15 "故障列表15";
CM_ SG_ 1312 ICC_FaultNum16 "故障列表16";
CM_ SG_ 1312 ICC_FaultNum17 "故障列表17";
CM_ SG_ 1312 ICC_FaultNum18 "故障列表18";
CM_ SG_ 1312 ICC_FaultNum19 "故障列表19";
CM_ SG_ 1312 ICC_FaultNum20 "故障列表20";
CM_ SG_ 1314 HCU_V2lDisChgBck "V2L外放电开关反馈";
CM_ SG_ 1314 HCU_DisChgMemFed "V2L外放电记忆开关反馈";
CM_ SG_ 1314 HCU_V2VDisChgBck "V2V放电开关反馈";
CM_ SG_ 1314 HCU_V2l_IntlDisChgBck "V2L内放电开关反馈";
CM_ SG_ 1314 HCU_FuelDetnOpDefeated "燃油检测开启失败提示";
CM_ SG_ 1314 HCU_FuelDetnModSwtFed "燃油检测开关反馈";
CM_ SG_ 1314 HCU_FuelDetnStateFed "燃油检测模式状态反馈";
CM_ SG_ 1314 HCU_HVDownRepairModeFed "断高压维修模式开关反馈";
CM_ SG_ 1314 HCU_SumFuCns "自清零后累计百公里油耗显示(仅仪表使用)";
CM_ SG_ 1314 HCU_TrailerMode "被拖模式开关反馈";
CM_ SG_ 1314 HCU_TABSwtFed_522h "ICC坦克转向开关反馈
0x0:Not_Active 使能位
0x1:Active 激活
0x2:Stand_by 就绪
0x3:Failed 失败";
CM_ SG_ 1314 HCU_KeyDriveModememory "驾驶模式记忆开关反馈";
CM_ SG_ 1314 HCU_DrivePowerDispSetFed "驱动系统功率显示方式开关反馈";
CM_ SG_ 1314 HCU_EXPERTNormFed "专家模式动力设置标准模式开关反馈";
CM_ SG_ 1314 HCU_4LModeFed "低速四驱开关反馈";
CM_ SG_ 1314 HCU_EXPERTEcoFed "专家模式动力设置柔和模式开关反馈";
CM_ SG_ 1314 HCU_SingleRegnRmn "当车机收到HCU发送信号“HCU_SingleRegnRmn =0x1”时，弹框提示“单踏板受限已退出，请注意安全驾驶！”，并播放报警音持续3s；
当车机收到HCU发送信号“HCU_SingleRegnRmn=0x0”时，停止提示，并停止报警音；";
CM_ SG_ 1314 HCU_DRIFTModeSts "通过大屏设置漂移模式灵敏度开关反馈
0x0:不动作
0x1:入门
0x2:大师
0x3:专家";
CM_ SG_ 1314 HCU_EXPERTAWDFed "专家模式驱动形式四驱开关设置反馈";
CM_ SG_ 1314 HCU_EXPERTRWDFed "专家模式驱动形式后驱开关设置反馈";
CM_ SG_ 1314 HCU_CrossaxisFed "专家模式交叉轴模式开关设置反馈";
CM_ SG_ 1314 HCU_EXPERTSportFed "专家模式动力设置激进模式开关反馈";
CM_ SG_ 1314 HCU_StopChrgnModeFed "驻车发电模式开关反馈";
CM_ SG_ 1314 HCU_StopChrgnFed "驻车发电开关反馈";
CM_ SG_ 1314 HCU_CLIMBFed "防溜设置开关反馈";
CM_ SG_ 1314 HCU_EXPERTAutoFed "专家模式驱动形式Auto开关设置反馈";
CM_ SG_ 1314 HCU_HEV_FunctionLimit "仪表文字提示“HEV模式不可用”";
CM_ SG_ 1314 HCU_ParkingChargeReminder "仪表文字提示“请先驻车再充电”";
CM_ SG_ 1314 HCU_PowerCut "仪表文字提示“动力即将切断，请靠边停车”";
CM_ SG_ 1314 HCU_IMMOReleaseSignal "防盗报警指示灯信号";
CM_ SG_ 1314 HCU_LVPowSupSYSAbn_lit "低压供电系统异常状态";
CM_ SG_ 1314 HCU_ChrgnFctMemSt "强制保电记忆开关反馈";
CM_ SG_ 1314 HCU_PowerModeChangeInhibit "仪表文字提示“为保障越野性能，模式无法切换”";
CM_ SG_ 1314 HCU_DisconnectChagWarn "仪表文字提示“请拔下充电枪”";
CM_ SG_ 1314 HCU_EngineRunClmReq "仪表文字提示“空调请求发动机运行中”";
CM_ SG_ 1314 HCU_VehicleSpeedMax_Limit "仪表文字提示“最高车速受限，请尽快联系售后检修”";
CM_ SG_ 1314 HCU_AccleAbility_Limit "仪表文字提示“加速性能受限，请尽快联系售后检修”";
CM_ SG_ 1314 HCU_DriveInhibit_GearP "仪表文字提示“动力受限，进入P挡后无法再次行驶，请尽快联系售后检修”";
CM_ SG_ 1314 HCU_SetModeNotChange "仪表文字提示“模式禁止切换”";
CM_ SG_ 1314 HCU_UTURNSnowFed "极限调头雪地场景反馈";
CM_ SG_ 1314 HCU_PowerLevel "仪表驱动能力等级";
CM_ SG_ 1314 HCU_TowingModeEna "大屏被拖提醒文字提示ICC接收
0x1时，大屏文字提示“切换至被拖模式需满足以下条件：1、挡位处于P挡；2、踩下刹车；3、车辆不在充电状态”";
CM_ SG_ 1314 HCU_LeaveVehicleWarning "仪表声音提醒";
CM_ SG_ 1314 HCU_DedicatedModeInhibit "仪表文字提示“当前模式不可用，请切换至越野模式”";
CM_ SG_ 1314 HCU_DisChargeStopFault "0x1时仪表文字提示“电池电量过低，放电停止”0x2时仪表文字提示“燃油不足，放电停止”";
CM_ SG_ 1314 HCU_RearEDLSts "后差速锁状态
0x0:不锁
0x1:解锁
0x2:锁止
0x3:切换提醒
0x4:不满足锁止条件
0x5:差速锁无法锁止故障
0x6:差速锁无法解锁故障";
CM_ SG_ 1314 HCU_FrntEDLSts "前差速锁状态
0x0: 不锁
0x1: 解锁
0x2：锁止
0x3：切换提醒
0x4：不满足锁止条件
0x5：差速锁无法锁止故障
0x6：差速锁无法解锁故障
0x7：提示需挂入后锁和4L
0x8：提示开启后锁
0x9：提示开启4L";
CM_ SG_ 1314 HCU_CruiseLimitSpeedValue "定速巡航设定车速";
CM_ SG_ 1314 HCU_DriveMode_JT "驾驶模式反馈
0x0:经济
0x1:标准
0x2:运动
0x3:雪/草地
0x4:泥地
0x5:越野
0x6:沙地
0x7:岩石
0x8:专家
0x9:智能
0xA:涉水
0xB:极限掉头
0xC:漂移
0xD:拖挂
0xE:越野竞速
0xF:晕车舒缓
0x10:智慧能量管理
0x11:纵横征服
0x12~0x1F：预留";
CM_ SG_ 1314 HCU_SocManageFed "Soc_Manage_Feedback";
CM_ SG_ 1314 HCU_SinglePedalMemFed "单踏板记忆开关反馈";
CM_ SG_ 1314 HCU_CCOSwtFed "越野蠕行开关反馈";
CM_ SG_ 1314 HCU_Pwr "instant_power";
CM_ SG_ 1314 HCU_UTURNSandFed "极限调头泥地场景开关反馈";
CM_ SG_ 1314 HCU_CruiseControlStatus "定速巡航指示灯";
CM_ SG_ 1314 HCU_EXPERTEESPSet "关闭牵引力控制系统&车身稳定控制系统（TCS&VDC_OFF）
全开（TCS、VDC等与ESP有关功能全部开启）
全关（TCS、VDC及RMI放侧翻、DTC发动机拖滞力矩管理）";
CM_ SG_ 1314 HCU_EgyRegenLevel "power_regeneration_level";
CM_ SG_ 1314 HCU_EngyFlowToDisp "0x0:初始化
0x1:无能量流状态
0x2:发动机单独运行
0x3:纯电前驱
0x4:纯电前驱回馈
0x5:纯电后驱
0x6:纯电后驱回馈
0x7:纯电四驱
0x8:纯电四驱回馈
0x9:串联前驱电池充电
0xA:串联前驱电池放电
0xB:串联前驱电池无电流
0xC:串联前驱回馈
0xD:串联后驱电池充电
0xE:串联后驱电池放电
0xF:串联后驱电池无电流
0x10:串联后驱回馈
0x11:串联四驱电池充电
0x12:串联四驱电池放电
0x13:串联四驱电池无电流
0x14:串联四驱回馈
0x15:并联前驱电池充电
0x16:并联前驱电池放电
0x17:并联前驱电池无电流
0x18:并联前驱回馈
0x19:并联四驱电池充电
0x1A:并联四驱电池放电
0x1B:并联四驱电池无电流
0x1C:并联四驱回馈
0x1D:原地发电电池充电
0x1E:原地发电电池放电
0x1F:原地发电电池无电流";
CM_ SG_ 1314 HCU_UTURNGrassFed "极限调头草地场景反馈";
CM_ SG_ 1314 HCU_UTURNMudFed "极限调头沙地场景开关反馈";
CM_ SG_ 1314 HCU_LTCDispFed "续航里程选择开关反馈";
CM_ SG_ 1314 HCU_iTAS_Warn "0x0: 无提示
0x1:iTAS功能已激活，无法锁止后桥差速锁
0x2:请释放EPB
0x3:当前车速过高，请减速
0x4：制动盘温度过高，极限掉头功能已退出
0x5：车辆被卡住，极限掉头功能退出
0x6：极限掉头使用时间到达极限，功能退出
0x7：请切换至D档开启极限掉头";
CM_ SG_ 1314 HCU_iCCO_Warn "0x0: 无提示
0x1:请释放EPB
0x2:当前车速过高，请减速
0x3:请关好车门，系好安全带
0x4:请切换至D档或N档开启越野蠕行
0x5:请关闭 APA/ACC/CC巡航
0x6:请退出HDC陡坡缓降/自动驻车
0x7:请手动切换驾驶模式至雪地或泥地或沙地或岩石
0x8:请踩制动踏板
0x9:iCCO越野蠕行已退出";
CM_ SG_ 1314 HCU_DriveModeChangeFail "驾驶模式切换不满足条件，提示“请停车后退出当前驾驶模式”";
CM_ SG_ 1314 HCU_25_Crossaxis_Warn "0x0: 无提示
0x1:请释放EPB
0x2:当前车速过高，交叉轴功能已退出
0x3:请切换至D档开启交叉轴功能
0x4:请关好车门，系好安全带
0x5:请将车辆静止后踩制动踏板
0x6:进入交叉轴模式后进行空簧高度调节";
CM_ SG_ 1314 HCU_25_EDLFed "中央差速锁显示信号";
CM_ SG_ 1314 HCU_DraggingModeRemind "0x0: 无提示
0x1:禁用ECO和越野模式
0x2:拖挂模式下仅支持Normal和Sport
0x3:ECO和越野模式恢复
0x4~0x7:预留";
CM_ SG_ 1314 HCU_iTASSceneReq "iTAS场景选择信息";
CM_ SG_ 1314 HCU_25_iTAS_SlopWarn "极限调头坡度条件不满足提醒
0x0:无提示
0x1:地面坡度过大
0x2~0x3:Reserved";
CM_ SG_ 1314 HCU_ExterTempLowHint "0x0:无提示
0x1:环境温度低切换为HEV模式
0x2:环境温度过低发动机运行中";
CM_ SG_ 1314 HCU_iTAS_Active "极限掉头激活状态（仪表）";
CM_ SG_ 1314 HCU_25_VehSpdOffroadRmn "漂移，掉头，专家，交叉轴，越野蠕行，越野竞速功能，用户在车辆未静止状态下点退出按钮或硬开关，仪表接收该信号0x1后显示“请将车辆禁止后再设置”";
CM_ SG_ 1314 HCU_DrivingModReq "HCU给IPB映射驾驶模式";
CM_ SG_ 1314 HCU_25_iDRIFT_Warn "0x0:无提示
0x1:请关好车门，系好安全带
0x2:请将车辆停止
0x3:系统故障，漂移模式暂无法开启
0x4:进入漂移模式后进行空簧高度调节";
CM_ SG_ 1314 HCU_25_SetVehSpdOffroad "越野模式切换车速条件不满足提示
0x0:无提示
0x1:请将车辆静止后再设置
0x2~0x3:Reserved";
CM_ SG_ 1314 HCU_25_LaunchMod_Warn "越野竞速弹射模式弹窗提示
0x0:无提示
0x1:弹射模式已激活，松开制动踏板，开始弹射
0x2:弹射模式已退出
0x3:条件不满足，弹射模式不可用
0x4~0x7:Reserved";
CM_ SG_ 1314 HCU_25_TAB_Warn "TAB功能提醒(T1J FL2华为智驾使用，D01及D01华为智驾版不使用)";
CM_ SG_ 1314 HCU_25_CCO_TextDisp "CCO功能提示信息
越野蠕行功能提示
(T1J FL2华为智驾使用，D01及D01华为智驾版不使用)";
CM_ SG_ 1314 HCU_25_DCM_Warn "纵横征服功能提示
0x0:No_Warn
0x1:请释放 EPB
0x2:请关好车门,系好安全带
0x3:请切换至D/R档开启攀爬模式
0x4:请关闭APA/ACC/CC巡航
0x5:请退出HDC 陡坡缓降/AVH自动驻车
0x6:请踩制动踏板
0x7:纵横征服 已退出
0x8: 请在车辆静止时进入或退出该模式
0x9:功率限制，功能无法正常使用
0xA: 请丢开加速踏板
0xB:请踩制动
0xC~0xF:Reserved";
CM_ SG_ 1314 HCU_25_CCMFed "攀爬设置开关反馈";
CM_ SG_ 1314 HCU_SumElecCns "自清零后累计百公里电耗显示(仅仪表使用)";
CM_ SG_ 1314 HCU_CrossBorderSts "HCU 反馈飞车模式执行情况
0x1: On 表示飞车模式限制已开启
0x2: Off 表示飞车模式限制未开启";
CM_ SG_ 1314 HCU_DischgSetSOCFed "放电SOC设置状态反馈
0xFE:Abnormal
0xFF:Invalid";
CM_ SG_ 1314 HCU_facCleverDrvAct_522h "驾驶运动因子";
CM_ SG_ 1314 HCU_stCleverDrvAct_522h "智慧驾驶风格状态";
CM_ SG_ 1314 HCU_stCleverRgnAct_522h "智慧能量回收状态";
CM_ SG_ 1314 HCU_stCleverMainAct_522h "智慧能量管理状态";
CM_ SG_ 1314 EnergySavingModeSts_522h "节能模式设置反馈";
CM_ SG_ 1314 HCU_facCleverDrvActRstFed_522h "驾驶运动因子重置反馈";
CM_ SG_ 1314 HCU_SailramainingT_Indc_522h "剩余航行时间（对比）,真实显示的";
CM_ SG_ 1314 HCU_ATCM_Operation_REQ_522h "航行模式按键确认信号
0x0:Not Active
0x1:进入航行提示  Switch to sailfunc indiction
0x2:进入上滩提示Switch to upbeach indiction
0x3:陆地时点击航行物理开关误操作提示 misoperation indiction: press sailfunc sw when conenmod 
0x4:陆地时点击上滩物理开关误操作提示misoperation indiction: press upbeach  sw when conenmod 
0x5:涉水时点击上滩物理开关误操作提示misoperation indiction: press upbeach sw when wadests
0x6:reserved
0x7:reserved";
CM_ SG_ 1314 HCU_ModeSwFailureIndc_522h "模式切换失效提示
0x0: Not Active
0x1:进入航行失败：车门未关
Entry navigation failed: Car door is not closed
0x2：进入航行失败：后视镜未展开
Entry navigation failed: Rearview mirror not deployed
0x3:进入航行失败：进排气防水阀故障
Entry navigation failed: Intake and exhaust waterproof valve malfunction
0x4：进入航行失败：车速过大
Entry navigation failed: Speed too fast
0x5：进入航行失败：电量过低
Entry navigation failed: Low battery
0x6：进入航行失败：空调放水阀故障|散热风扇故障
Entry navigation failed: Air conditioning drain valve malfunction| Cooling fan malfunction";
CM_ SG_ 1314 HCU_Sailmode_522h "涉水模式
0x0:Convenmod
0x1:SalWadeSts  浅涉水
0x2:DpWadeSts 深涉水（保留）
0x3:SailingFunc  航行
0x4:UpbeachSts  上滩
0x5:WaitfinspSts 待检（保留）
0x6:EmerfloatingSts 应急浮水
0x7:Reserved2";
CM_ SG_ 1314 HCU_CarSickRelfModeFb "晕车舒缓状态反馈";
CM_ SG_ 1314 HCU_DeepSnowSts_522h "深雪模式状态信号";
CM_ SG_ 1314 DriveModeChangeFailReason_522h "驾驶模式切换失败原因提示";
CM_ SG_ 1314 HCU_CarSickRelfModeDisReason "晕车舒缓开启失败原因
0x0:不提示
0x1:请退出越野模式
0x2:请退出越野蠕行
0X3:请退出节能模式
0X4:请退出拖挂模式
0X5:请退出被拖模式
0X6:请退出定速巡航模式
0X7:请退出智驾模式";
CM_ SG_ 1314 HCU_DCMSwtFed "纵横征服模式场景
0x0:not active
0x1:泥沙脱困
0x2:雪地暴行
0x3:攀爬挑战
0x4:丛林探路
0x5:拔河
0x6:救援
0x7:Reserved";
CM_ SG_ 1316 LHFTireTemperature "左前方位轮胎温度";
CM_ SG_ 1316 RHFTireTemperature "右前方位轮胎温度";
CM_ SG_ 1316 LHRTireTemperature "左后方位轮胎温度";
CM_ SG_ 1316 LHFTirePressure "左前方位轮胎胎压";
CM_ SG_ 1316 RHFTirePressure "右前方位轮胎胎压";
CM_ SG_ 1316 LHRTirePressure "左后方位轮胎胎压";
CM_ SG_ 1316 RHRTirePressure "右后方位轮胎胎压";
CM_ SG_ 1316 RHRTireTemperature "右后方位轮胎温度";
CM_ SG_ 1318 ICC_SET_TDL_Rhythm_Switch "氛围灯律动开关";
CM_ SG_ 1318 ICC_SET_TDL_Switch "氛围灯开关";
CM_ SG_ 1318 ICC_SET_TDL_ColourModeAdj "氛围灯颜色模式调节

Monochrome_单色
panchromatic为全色
FLZCU_TDL";
CM_ SG_ 1318 ICC_TDL_RhythmReq "音乐律动模式调节";
CM_ SG_ 1318 ICC_VoiceWake "语音唤醒";
CM_ SG_ 1318 ICC_TDLAssociatedDriverModeSw "氛围灯关联驾驶模式开关";
CM_ SG_ 1318 ICC_SET_ApiluminanceAdj "氛围灯亮度调节
氛围灯亮度_Level1最暗_Level8最亮FLZCU_TDL";
CM_ SG_ 1318 ICC_SET_MusicLoudness_120HZ "均衡器设置";
CM_ SG_ 1318 ICC_SET_MusicLoudness_250HZ "均衡器设置";
CM_ SG_ 1318 ICC_SET_MusicLoudness_500HZ "均衡器设置";
CM_ SG_ 1318 ICC_SET_MusicLoudness_1000HZ "均衡器设置";
CM_ SG_ 1318 ICC_SET_MusicLoudness_1500HZ "均衡器设置";
CM_ SG_ 1318 ICC_SET_MusicLoudness_2000HZ "均衡器设置";
CM_ SG_ 1318 ICC_SET_MusicLoudness_6000HZ "均衡器设置";
CM_ SG_ 1318 ICC_SET_256ColourAdj "多元颜色设置（256色）";
CM_ SG_ 1318 ICC_TDL_FlowLightSw "流水灯开关";
CM_ SG_ 1318 ICC_TDL_FlowLightModeAdj "流水灯模式调节";
CM_ BO_ 1320 "触发一次发送三帧有效+三帧 Not Active";
CM_ SG_ 1320 ICC_Chb_Req "冰箱开关请求";
CM_ SG_ 1320 ICC_ChbMem_Req "记忆开关请求";
CM_ SG_ 1320 ICC_ChbDelay_Req "延时开关请求";
CM_ SG_ 1320 ICC_ChbSterilization_Req "杀菌开关请求";
CM_ SG_ 1320 ICC_ChbItemsLeft_Req "物品遗留开关请求";
CM_ SG_ 1320 ICC_ParkingRadarSwSet "驻车雷达开关请求";
CM_ SG_ 1320 ICC_ChbTimeset_Req "延时时间设置请求";
CM_ SG_ 1320 ICC_ChbCoolset_Req "制冷温度设置
0x1~0xD:-6℃~6℃（捷途使用）
0xE~0x19:-18℃~-7℃（股份使用，捷途预留）";
CM_ SG_ 1320 ICC_ChbCoolorheat_Req "制冷制热开关请求";
CM_ SG_ 1320 ICC_ChbHeatset_Req "制热温度调节设置请求";
CM_ SG_ 1322 STAT_AMPAlarm "Instrument panel cluster alarm status to amplifier for chime play";
CM_ SG_ 1324 TirePositionWarning_LHFTire "左前方位轮胎胎压报警，含快速失压、低压、高压、高温。";
CM_ SG_ 1324 TirePositionWarning_RHFTire "右前方位轮胎胎压报警，含快速失压、低压、高压、高温。";
CM_ SG_ 1324 TirePositionWarning_LHRTire "左后方位轮胎胎压报警，含快速失压、低压、高压、高温。";
CM_ SG_ 1324 TirePositionWarning_RHRTire "右后方位轮胎胎压报警，含快速失压、低压、高压、高温。";
CM_ SG_ 1324 TirePressureWarningLampSts "胎压报警灯状态，含熄灭、闪烁（快速失压）、常亮（低压）三种状态";
CM_ SG_ 1324 TirePressureSystemFailSts "胎压系统失效状态";
CM_ BO_ 1326 "触发一次发送三帧有效+三帧 Not Active";
CM_ SG_ 1326 ICC_DWDOnOff_Req "涉水雷达开关设置";
CM_ SG_ 1326 ICC_ContainerLightSet "货箱灯开关(D01P）";
CM_ SG_ 1328 RADAR_1_RadarDetectSts "雷达探测状态
当发01，IHU_以前探头音讯蜂鸣扬声器；
当发10，IHU_以后探头音讯蜂鸣扬声器
ICM_接收此信号，但前_后探头均用一种音讯蜂鸣。";
CM_ SG_ 1328 RADAR_1_RadarWorkSts "雷达系统工作状态
1、Active:当打开PAS_开关或打到倒文件，雷达模块开始工作，此时发1，
IHU_接收到后即便用户未打开IHU，也会通过此信号自动点亮屏幕；
2、Not_Active:当不在倒档且PAS_开关关闭，或者车速大于15km_h_时，发0(Not_Active)。
3、自检提示音:雷达工作状态位由0_变化为1_时，仪表根据探头状态信息发出相应提示音，如果探头有故障则长鸣2_秒提示探头故障，如果探头没有故障则鸣叫，0.5_秒提示雷达进入工作状态。";
CM_ SG_ 1328 RADAR_1_Resd1 "Profile1A:E2E_Reserved";
CM_ SG_ 1328 RADAR_1_RHMRRadarSensorDistance "右中后探头信息
自检故障:发送Sensor_Err
自检正常或雷达待机:发送0x3
E正常测距:距离=(D)*5+25
无障碍物:发送0x3E
0x20~0x3D:无效数据";
CM_ SG_ 1328 RADAR_1_LHRRadarSensorDistance "左后探头信息
自检故障:发送Sensor_Err
自检正常或雷达待机:发送0x3
E正常测距:距离=(D)*5+25
无障碍物:发送0x3E
0x20~0x3D:无效数据";
CM_ SG_ 1328 RADAR_1_LHMRRadarSensorDistance "左中后探头信息
自检故障:发送Sensor_Err
自检正常或雷达待机:发送0x3
E正常测距:距离=(D)*5+25
无障碍物:发送0x3E
0x20~0x3D:无效数据";
CM_ SG_ 1328 RADAR_1_RHRRadarSensorDistance "右后探头信息
自检故障:发送Sensor_Err
自检正常或雷达待机:发送0x3
E正常测距:距离=(D)*5+25
无障碍物:发送0x3E
0x20~0x3D:无效数据";
CM_ SG_ 1328 RADAR_1_RHFRadarSensorDistance "右前探头信息
自检故障:发送Sensor_Err
自检正常或雷达待机:发送0x3
E正常测距:距离=(D)*5+25
无障碍物:发送0x1E
0x20~0x3D:无效数据";
CM_ SG_ 1328 RADAR_1_LHFRadarSensorDistance "左前探头信息
自检故障:发送Sensor_Err
自检正常或雷达待机:发送0x3
E正常测距:距离=(D)*5+25
无障碍物:发送0x1E
0x20~0x3D:无效数据";
CM_ SG_ 1328 RADAR_1_RHMFRadarSensorDistance "右中前探头信息
自检故障:发送Sensor_Err
自检正常或雷达待机:发送0x1E
正常测距:距离=(D)*5+25
无障碍物:发送0x1E
低配雷达(后4_探头):发送0x1E
0x1C~0x1D:无效数据";
CM_ SG_ 1328 RADAR_1_AudibleBeepRate "报警频率
1、自检过程或雷达待机时发送Startup
2、进入测距模式后:发送频率信息
3、自检提示音见
RadarWorkSts_详细说明";
CM_ SG_ 1328 RADAR_1_LHMFRadarSensorDistance "左中前探头信息
自检故障:发送Sensor_Err
自检正常或雷达待机:发送0x1E
正常测距:距离=(D)*5+25
无障碍物:发送0x1E
低配雷达(后4_探头):发送0x1E
0x1C~0x1D:无效数据";
CM_ SG_ 1330 DWD_TextDisp "报警提示内容";
CM_ SG_ 1330 DWD_SoundIndcn "报警声音提示";
CM_ SG_ 1330 LSensorFailSts "左探头工作状态";
CM_ SG_ 1330 RSensorFailSts "右探头工作状态";
CM_ SG_ 1330 DWD_Distance "报警距离分段";
CM_ SG_ 1330 DWD_Switch "涉水雷达开关状态";
CM_ SG_ 1330 DWD_DistanceL "左报警距离分段";
CM_ BO_ 1331 "触发一次发送三帧有效+三帧 Not Active";
CM_ SG_ 1331 ICC_RLSeatEasyEntryExitSet "二排左侧便捷进入\离车";
CM_ SG_ 1331 ICC_RRSeatEasyEntryExitSet "二排右侧便捷进入\离车";
CM_ SG_ 1331 ICC_RLMemoryRecoveryCmd "ICC二排左侧记忆保存/恢复指令";
CM_ SG_ 1331 ICC_RRMemoryRecoveryCmd "ICC二排右侧记忆保存/恢复指令";
CM_ SG_ 1331 ICC_RLSitPosnlocation "二排左侧座椅记忆设置";
CM_ SG_ 1331 ICC_RRSitPosnlocation "二排右侧座椅记忆设置";
CM_ SG_ 1331 ICC_CMSMDisplaySwitch "吸顶屏开关";
CM_ SG_ 1331 ICC_CMSMDisplayAdjustmode "吸顶屏模式调节
0x1:正常角度
0x2:观影角度";
CM_ SG_ 1331 ICC_CMSMSetstandardSwitch "吸顶屏标定开关0x1:标定打开 0x2:标定关闭";
CM_ SG_ 1331 ICC_LeftPedalControl "左边电踏请求（左边电踏软开关展开缩回请求）";
CM_ SG_ 1331 ICC_RightPedalControl "右边电踏请求（右边电踏软开关展开缩回请求）";
CM_ SG_ 1331 ICC_EPCEnable "电踏电动功能模式
0：无效值；
1：电动踏板启用（软开关启用）
2：电动踏板禁用（软开关禁用）";
CM_ SG_ 1331 ICC_AMPKTVvoiceVolumeSet "Amplifier KTV voice volume status
KTV人声音量设定";
CM_ SG_ 1331 ICC_AMPA2BENCSoundReq "Head unit ENC sound request to amplifier
ENC音源需求状态";
CM_ SG_ 1331 ICC_AMPENCVolumeSet "Amplifier ENC volume status
ENC声音量设定";
CM_ SG_ 1331 ICC_AMPA2BChimeSoundReq "Head unit Chime sound request to amplifier
Chime音源需求状态";
CM_ SG_ 1331 ICC_AMPA2BKTVvoiceSoundReq "Head unit KTV voice/IESS sound request to amplifier
KTV人声/模拟声浪音源需求状态";
CM_ SG_ 1331 Set_AMPSoundFocus_2 "Amplifier sound focus status";
CM_ SG_ 1331 ICC_MedStatusSet "冥想模式开关";
CM_ SG_ 1331 Set_AMPLoudness "Amplifier Loudness setting / 响度设定";
CM_ SG_ 1331 ICC_MedAreaSet "冥想模式开启区域设置";
CM_ SG_ 1331 ICC_LeftElectricPedalsSet "左电踏收回和展开软开关（前提自动打开）
0x1:踏板3D软开关开启
0x2:踏板3D软开关关闭";
CM_ SG_ 1331 ICC_RightElectricPedalsSet "右电踏收回和展开软开关（前提自动打开）
0x1:踏板3D软开关开启
0x2:踏板3D软开关关闭";
CM_ SG_ 1331 ICC_NapAreaSet2 "小憩模式开启区域设置2";
CM_ SG_ 1331 ICC_DisplayAdjustrAngReq "微信小程序遥控器控制吸顶屏角度90-110
0x0:Not active";
CM_ SG_ 1331 Set_AMPExSoundmode "Amplifier Exsound mode setting / 设定高级音效模式";
CM_ SG_ 1331 Set_AMPKeyVolume "Amplifier Keytone volume setting /设定按键音通道音量设定";
CM_ SG_ 1331 ICC_CMSMTouchSts "吸顶屏触摸信号0x1:有触摸 0x2:无触摸";
CM_ SG_ 1331 Set_AMPA2BENCSound "扬声器位置";
CM_ BO_ 1333 "触发一次发送三帧有效+三帧 Not Active";
CM_ SG_ 1333 ICC_SRFCmd "天窗开关设置
全开
全关
翘起";
CM_ SG_ 1333 ICC_SRFPercentCmd "手滑动开启天窗百分比";
CM_ SG_ 1333 ICC_SunshadeCmd "遮阳帘开关设置
全开
全关
一半";
CM_ SG_ 1333 ICC_SunshadePercentCmd "手滑动开启遮阳帘百分比";
CM_ SG_ 1333 ICC_CSunshadeReq "天幕遮阳帘开关设置";
CM_ SG_ 1333 ICC_CSunshadePercentReq "手滑动开启天幕遮阳帘百分比";
CM_ SG_ 1333 CSunshadeLearnedReq_535h "遮阳帘学习请求";
CM_ SG_ 1333 CSunshadePercentReq_535h "遮阳帘开度";
CM_ BO_ 1335 "触发一次发送三帧有效+三帧 Not Active";
CM_ SG_ 1335 ICC_SET_EPS_SteerReturnRmdSts "方向盘回正开关";
CM_ SG_ 1335 ICC_SET_MFSShake "方向盘震动开关";
CM_ SG_ 1335 ICC_DMS_1_DistractionLevel "方向盘震动等级调节";
CM_ SG_ 1335 ICC_SET_EPS_AsociWithDrvModSts "EPS与驾驶模式关联开关";
CM_ SG_ 1335 ICC_OverLoadWarnShieldSet "重量报警屏蔽软开关";
CM_ SG_ 1335 ICC_BSWReq "智能擦盘开启信号";
CM_ SG_ 1335 ICC_horizontalReq "露营找平软开关";
CM_ SG_ 1335 ICC_RolloverSetCmd "翻滚设置开关";
CM_ SG_ 1335 ICC_TrekThroughReq_537h "越野穿越开关";
CM_ SG_ 1335 ICC_InflateReq_537h "一键充气开关";
CM_ SG_ 1335 ICC_UndergroundModeReq_537h "地库模式开关";
CM_ SG_ 1335 ICC_SandABSSw_537h "沙地ABS模式-ABS状态请求";
CM_ SG_ 1335 ICC_SandABSCmd_537h "沙地ABS模式-开启请求";
CM_ SG_ 1335 ICC_EPBAUTOCmd_537h "熄火自动驻车
EPB AUTO开关
0x1:开关按钮点亮，功能开启
0x2:开关按钮熄灭，功能关闭";
CM_ SG_ 1335 ICC_SpeParkSet_537h "熄火移车/印尼驻车";
CM_ BO_ 1337 "触发一次发送三帧有效+三帧 Not Active";
CM_ SG_ 1337 ICC_SET_BT_ReduceWindSpeed "大屏设置蓝牙通话降低风速";
CM_ SG_ 1337 ICC_SET_IPM_FirstBlowing "夏日热风规避_大屏设置空调启动时第一口风";
CM_ SG_ 1337 ICC_SET_IPM_BlowerDelay "大屏设置车辆熄火空调鼓风机延时";
CM_ SG_ 1337 ICC_SET_CirculationInTunnels "大屏设置隧道内循环";
CM_ SG_ 1337 ICC_UVCLuminanceReq "大屏设置紫外线杀菌灯强度请求";
CM_ SG_ 1337 ICC_UVCControlReq "大屏设置紫外线杀菌灯";
CM_ SG_ 1337 ICC_CrossCountryCoolingReq "越野散热开关";
CM_ SG_ 1337 ICC_KeepWarmReq "恒温模式状态开关请求";
CM_ SG_ 1337 ICC_keepwarmSetTemperatureReq "恒温模式温度设置请求";
CM_ SG_ 1337 ICC_ParkingAirConditioning "驻车空调使能开关
ventilate通风";
CM_ SG_ 1337 ICC_CoolantFill_Req "冷却液加注开关请求";
CM_ SG_ 1337 ICC_FraganceLightoffReq "香氛氛围灯开关状态";
CM_ SG_ 1337 ICC_FraganceMemoffReq "香氛记忆开关状态";
CM_ SG_ 1337 ICC_TimingLevel "香氛定时等级";
CM_ SG_ 1337 ICC_CFSCycleLevel "香氛循环等级";
CM_ SG_ 1337 ICC_AirPurgeReminderReq "空气净化提醒开关请求";
CM_ SG_ 1337 ICC_TimedVentilationReq "大屏定时换气功能开关";
CM_ SG_ 1337 ICC_BiochemicalFuncReq "大屏生化功能开关";
CM_ SG_ 1337 ICC_ModeAdjustDisplaySts "空调模式";
CM_ SG_ 1337 ICC_PetModeSetTemperature_R_C "宠物模式前右空调温度设置";
CM_ SG_ 1337 ICC_PetmodeSetTemperature_L_C "宠物模式前左空调温度设置";
CM_ SG_ 1337 ICC_PetModeSetCirculationSts "宠物模式空调内外循环切换设置";
CM_ SG_ 1337 ICC_PetModeSetAutoKeySts "宠物模式空调自动模式设置";
CM_ SG_ 1337 ICC_PetModeSetCLMOn "宠物模式空调开关设置";
CM_ SG_ 1337 ICC_ISSFctCmd_539h "启停开关信号";
CM_ SG_ 1338 FMCU_ErrLvlDis "前驱动电机故障等级";
CM_ SG_ 1338 FMCU_SpdAct_EDR "前驱动电机实际转速";
CM_ BO_ 1341 "该报文为捷途在4.X平台上新增报文";
CM_ SG_ 1341 BMS_44_PackPowerRealTime "捷途新增动力电池包实时功率";
CM_ BO_ 1345 "捷途ID新增";
CM_ SG_ 1345 DVR_1_DVRFailReasons "DVR失效原因";
CM_ SG_ 1345 DVR_1_RecordSts "DVR普通录像状态";
CM_ SG_ 1345 DVR_1_Sdcard_Sts "DVR TF卡状态
0x0: Normal（正常）
0x1: Not inserted（TF卡未插入）
0x2: Filesystem unsupported（TF卡文件系统不支持）
0x3: Capacity unsupported（TF卡容量不支持）
0x4: Abnormal（TF卡异常）
0x5: Full（TF卡满）
0x6~0x7: Reserved";
CM_ BO_ 1349 "捷途ID新增";
CM_ SG_ 1349 SBOX_MSD_Res "MSD发送状态
0x0:inial
0x4:短信条数不够";
CM_ SG_ 1349 SBOX_Ecallphonenub_Res "通话状态";
CM_ BO_ 1351 "捷途ID新增";
CM_ SG_ 1351 SBOX_SetMsgTotal "当前短信总条数";
CM_ SG_ 1351 SBOX_SetMSDTotal "设置MSD短信阈值";
CM_ SG_ 1351 SBOX_SetCallTimeThreshold "设置通话总时长阈值";
CM_ SG_ 1351 SBOX_SetTodayCallTimeThreshold "设置当日通话时长阈值";
CM_ SG_ 1351 SBOX_SetCurretnCallTime "设置当前通话总时长";
CM_ SG_ 1351 SBOX_SetCurretnMsgThreshold "设置当前短信总条数";
CM_ SG_ 1351 SBOX_SetMsgTotalThreshold "设置短信总条数阈值";
CM_ SG_ 1351 SBOX_SetMsdThreshold "设置MSD短信阈值";
CM_ SG_ 1351 SBOX_SetCurrenMsdCnt "设置当前MSD短条数";
CM_ SG_ 1351 SBOX_SetCustomMsgThreshold "设置客户短信阈值";
CM_ SG_ 1351 SBOX_SetCurrentCustomMsgCnt "设置当前客户短信条数";
CM_ BO_ 1353 "捷途ID新增";
CM_ SG_ 1353 SBOX_ICC_MACReq "SBOX请求车机连接蓝牙";
CM_ SG_ 1353 SBOX_MAC_Req0 "本地MAC第0个字节";
CM_ SG_ 1353 SBOX_MAC_Req1 "本地MAC第1个字节";
CM_ SG_ 1353 SBOX_MAC_Req2 "本地MAC第2个字节";
CM_ SG_ 1353 SBOX_MAC_Req3 "本地MAC第3个字节";
CM_ SG_ 1353 SBOX_MAC_Req4 "本地MAC第4个字节";
CM_ SG_ 1353 SBOX_MAC_Req5 "本地MAC第5个字节";
CM_ SG_ 1354 ICC_SetMsgTotal "当前短信总条数";
CM_ SG_ 1354 ICC_SetMSDTotal "设置MSD短信阈值";
CM_ SG_ 1354 ICC_SetCallTimeThreshold "设置通话总时长阈值";
CM_ SG_ 1354 ICC_SetTodayCallTimeThreshold "设置当日通话时长阈值";
CM_ SG_ 1354 ICC_SetCurretnCallTime "设置当前通话总时长";
CM_ SG_ 1354 ICC_SetCurretnMsgThreshold "设置当前短信总条数";
CM_ SG_ 1354 ICC_SetMsgTotalThreshold "设置短信总条数阈值";
CM_ SG_ 1354 ICC_SetMsdThreshold "设置MSD短信阈值";
CM_ SG_ 1354 ICC_SetCurrenMsdCnt "设置当前MSD短条数";
CM_ SG_ 1354 ICC_SetCustomMsgThreshold "设置客户短信阈值";
CM_ SG_ 1354 ICC_SetCurrentCustomMsgCnt "设置当前客户短信条数";
CM_ SG_ 1356 ICC_flag "选择激活类型";
CM_ SG_ 1356 ICC_ActiveTsp_Req "车机发起SBOX端的TSP注册";
CM_ SG_ 1356 ICC_ActiveSim_Req "车机切换sbox sim卡激活与未激活状态";
CM_ SG_ 1356 ICC_GetMac_req "请求查询MAC地址";
CM_ SG_ 1356 ICC_GetIccid_Vin "查询VIN和ICCID请求";
CM_ SG_ 1356 ICC_Platform_Phonenub1 "平台号码第1个数（从最左边开始）";
CM_ SG_ 1356 ICC_Platform_Phonenub2 "平台号码第2个数";
CM_ SG_ 1356 ICC_Platform_Phonenub3 "平台号码第3个数";
CM_ SG_ 1356 ICC_Platform_Phonenub4 "平台号码第4个数";
CM_ SG_ 1356 ICC_Platform_Phonenub5 "平台号码第5个数";
CM_ SG_ 1356 ICC_Platform_Phonenub6 "平台号码第6个数";
CM_ SG_ 1356 ICC_Platform_Phonenub7 "平台号码第7个数";
CM_ SG_ 1356 ICC_Platform_Phonenub8 "平台号码第8个数";
CM_ SG_ 1356 ICC_Platform_Phonenub9 "平台号码第9个数";
CM_ SG_ 1356 ICC_Platform_Phonenub10 "平台号码第10个数";
CM_ SG_ 1356 ICC_Platform_Phonenub11 "平台号码第11个数";
CM_ SG_ 1356 ICC_Platform_Phonenub12 "平台号码第12个数";
CM_ SG_ 1356 ICC_Platform_Phonenub13 "平台号码第13个数";
CM_ SG_ 1356 ICC_Platform_Phonenub14 "平台号码第14个数";
CM_ SG_ 1356 ICC_Platform_Phonenub15 "平台号码第15个数";
CM_ SG_ 1356 ICC_Platform_Phonenub16 "平台号码第16个数";
CM_ SG_ 1356 ICC_Platform_Phonenub17 "平台号码第17个数";
CM_ SG_ 1356 ICC_Platform_Phonenub18 "平台号码第18个数";
CM_ SG_ 1356 ICC_Platform_Phonenub19 "平台号码第19个数";
CM_ SG_ 1356 ICC_Platform_Phonenub20 "平台号码第20个数";
CM_ SG_ 1356 ICC_Mac0 "车机MAC第0个字节";
CM_ SG_ 1356 ICC_Mac1 "车机MAC第1个字节";
CM_ SG_ 1356 ICC_Mac2 "车机MAC第2个字节";
CM_ SG_ 1356 ICC_Mac3 "车机MAC第3个字节";
CM_ SG_ 1356 ICC_Mac4 "车机MAC第4个字节";
CM_ SG_ 1356 ICC_Mac5 "车机MAC第5个字节";
CM_ SG_ 1356 ICC_GivePlatformNumber_Flag "平台号码是否有效";
CM_ SG_ 1356 ICC_Mac_Flag "车机蓝牙MAC是否有效";
CM_ BO_ 1358 "捷途ID新增";
CM_ SG_ 1358 SBOX_ActiveTsp_Res "TSP激活状态";
CM_ SG_ 1358 SBOX_ActiveSim_Res "SIM激活状态";
CM_ SG_ 1358 SBOX_GetPlatformNumberRes "平台号状态（有效，无效）";
CM_ SG_ 1358 SBOX_Mac_Res0 "本地MAC第0个字节";
CM_ SG_ 1358 SBOX_Mac_Res1 "本地MAC第1个字节";
CM_ SG_ 1358 SBOX_Mac_Res2 "本地MAC第2个字节";
CM_ SG_ 1358 SBOX_Mac_Res3 "本地MAC第3个字节";
CM_ SG_ 1358 SBOX_Mac_Res4 "本地MAC第4个字节";
CM_ SG_ 1358 SBOX_Mac_Res5 "本地MAC第5个字节";
CM_ SG_ 1358 SBOX_ICCId_Res0 "ICCID第0个字节（从左边开始）";
CM_ SG_ 1358 SBOX_ICCId_Res1 "ICCID第1个字节";
CM_ SG_ 1358 SBOX_ICCId_Res2 "ICCID第2个字节";
CM_ SG_ 1358 SBOX_ICCId_Res3 "ICCID第3个字节";
CM_ SG_ 1358 SBOX_ICCId_Res4 "ICCID第4个字节";
CM_ SG_ 1358 SBOX_ICCId_Res5 "ICCID第5个字节";
CM_ SG_ 1358 SBOX_ICCId_Res6 "ICCID第6个字节";
CM_ SG_ 1358 SBOX_ICCId_Res7 "ICCID第7个字节";
CM_ SG_ 1358 SBOX_ICCId_Res8 "ICCID第8个字节";
CM_ SG_ 1358 SBOX_ICCId_Res9 "ICCID第9个字节";
CM_ SG_ 1358 SBOX_ICCId_Res10 "ICCID第10个字节";
CM_ SG_ 1358 SBOX_ICCId_Res11 "ICCID第11个字节";
CM_ SG_ 1358 SBOX_ICCId_Res12 "ICCID第12个字节";
CM_ SG_ 1358 SBOX_ICCId_Res13 "ICCID第13个字节";
CM_ SG_ 1358 SBOX_ICCId_Res14 "ICCID第14个字节";
CM_ SG_ 1358 SBOX_ICCId_Res15 "ICCID第15个字节";
CM_ SG_ 1358 SBOX_ICCId_Res16 "ICCID第16个字节";
CM_ SG_ 1358 SBOX_ICCId_Res17 "ICCID第17个字节";
CM_ SG_ 1358 SBOX_ICCId_Res18 "ICCID第18个字节";
CM_ SG_ 1358 SBOX_ICCId_Res19 "ICCID第19个字节";
CM_ SG_ 1358 SBOX_Vin0 "VIN第0个字节（从左边开始）";
CM_ SG_ 1358 SBOX_Vin1 "VIN第1个字节('Z'-->5A(0101 1010))";
CM_ SG_ 1358 SBOX_Vin2 "VIN第2个字节";
CM_ SG_ 1358 SBOX_Vin3 "VIN第3个字节";
CM_ SG_ 1358 SBOX_Vin4 "VIN第4个字节";
CM_ SG_ 1358 SBOX_Vin5 "VIN第5个字节";
CM_ SG_ 1358 SBOX_Vin6 "VIN第6个字节";
CM_ SG_ 1358 SBOX_Vin7 "VIN第7个字节";
CM_ SG_ 1358 SBOX_Vin8 "VIN第8个字节";
CM_ SG_ 1358 SBOX_Vin9 "VIN第9个字节";
CM_ SG_ 1358 SBOX_Vin10 "VIN第10个字节";
CM_ SG_ 1358 SBOX_Vin11 "VIN第11个字节";
CM_ SG_ 1358 SBOX_Vin12 "VIN第12个字节";
CM_ SG_ 1358 SBOX_Vin13 "VIN第13个字节";
CM_ SG_ 1358 SBOX_Vin14 "VIN第14个字节";
CM_ SG_ 1358 SBOX_Vin15 "VIN第15个字节";
CM_ SG_ 1358 SBOX_Vin16 "VIN第16个字节";
CM_ BO_ 1360 "触发一次发送三帧有效+三帧 Not Active";
CM_ SG_ 1360 ICC_LISD_DisplaySwitch "自定义图片实时显示功能开关";
CM_ SG_ 1360 ICC_LISD_ParkingShowCMD "驻车动画开关（反馈已有）";
CM_ SG_ 1360 ICC_RISD_DisplaySwitch "自定义图片实时显示功能开关";
CM_ SG_ 1360 ICC_RISD_ParkingShowCMD "驻车动画开关（反馈已有）";
CM_ SG_ 1360 ICC_LogoParkingReq "前LOGO驻车点亮开关请求";
CM_ SG_ 1360 ICC_LogoChargingReq "前LOGO充电灯效开关请求";
CM_ SG_ 1360 ICC_DRLSw "日间行车灯软开关";
CM_ SG_ 1360 ICC_LISD_ParkingShowMod "LISD驻车动画模式";
CM_ SG_ 1360 ICC_RISD_ParkingShowMod "RISD驻车动画模式";
CM_ SG_ 1360 ICC_LogoColorReq "Logo灯颜色设置，1-256分别对应256种颜色";
CM_ SG_ 1360 ICC_MusicLampShowSW "0x0: 灯光秀总开关关闭
0x1: 灯光秀总开关开启";
CM_ SG_ 1360 ICC_PenetrationLampSetF "前贯穿灯软开关(D01P使用)";
CM_ SG_ 1360 ICC_XDriveMode "ICC通过视频流发给VCU进行驾驶模式设置
0x0:Not Active
0x1:无法判断 unidentifiable
0x2:普通1 Normal
0x3:雪地1 SNOW
0x4:泥地1 MUD
0x5:岩石1 ROCK
0x6:沙地1 SAND
0x7:水面1 WATER SURFACE
0x8：普通2 Normal
0x9:雪地2 SNOW
0xA:泥地2 MUD
0xB: 岩石2 ROCK
0xC:沙地2 SAND
0xD:水面2 WATER SURFACE
0xE:普通3 Normal
0xF:雪地3 SNOW
0x10:泥地3 MUD
0x11:岩石3 ROCK
0x12:沙地3 SAND";
CM_ SG_ 1360 ICC_DowWaringSw "盲区检测氛围灯联动闪烁开关";
CM_ SG_ 1360 ICC_CarSearhSetSwitchSts "寻车设置";
CM_ SG_ 1360 ICC_TDL_NightBright_SW_550h "夜间亮度开关";
CM_ BO_ 1361 "捷途ID新增";
CM_ SG_ 1361 EPC_LeftPedalSystem_Sts "左边电踏系统故障状态
0:正常
1:电压保护
2:系统故障
3:热保护
4:模式禁用
5:左边行驶保护
6:左边防夹保护";
CM_ SG_ 1361 EPC_RightPedalSystem_Sts "右边电踏系统状态
0:正常
1:电压保护
2:系统故障
3:热保护
4:模式禁用
5:右边行驶保护
6:右边防夹保护";
CM_ SG_ 1361 EPC_LeftPedalTimeTravel "左边电踏行程百分比";
CM_ SG_ 1361 EPC_RightPedalTimeTravel "右边电踏行程百分比";
CM_ SG_ 1361 EPC_RightPedalRealTime_Sts "右边电踏实时状态
0:无效
1:右边踏板收回到位
2:右边踏板收回中
3:右边踏板收回失败
4:右边踏板展开到位
5:右边踏板展开中
6:右边踏板展开失败";
CM_ SG_ 1361 EPC_LeftPedalBreakIce_Sts "左边电踏实时破冰状态
0:无效
1:左边正在破冰
2:左边破冰成功
3:左边破冰失败";
CM_ SG_ 1361 EPC_LeftPedalRealTime_Sts "左边电踏实时状态
0:无效
1:左边踏板收回到位
2:左边踏板收回中
3:左边踏板收回失败
4:左边踏板展开到位
5:左边踏板展开中
6:左边踏板展开失败";
CM_ SG_ 1361 EPC_RightPedalCmdStatus "右边踏板反馈信号
0x1:右边踏板展开
0x2:右边踏板回收
0x3:自动";
CM_ SG_ 1361 EPC_LeftPedalCmdStatus "左边踏板反馈信号
0x1:左踏板展开
0x2:左踏板回收
0x3:自动";
CM_ SG_ 1361 EPC_Enable_CmdStatus "电踏功能模式使能反馈
0x0:无效值
0x1:踏板功能使能
0x2:踏板功能禁能";
CM_ SG_ 1361 EPC_RightPedalBreakIce_Sts "右边电踏实时破冰状态
0:无效
1:右边正在破冰
2:右边破冰成功
3:右边破冰失败";
CM_ SG_ 1361 EPC_RightPedal3D_Sts "右电踏收回和展开反馈（前提自动打开）
0x1:踏板3D软开关开启
0x2:踏板3D软开关关闭";
CM_ SG_ 1361 EPC_LeftPedal3D_Sts "左电踏收回和展开反馈（前提自动打开）
0x1:踏板3D软开关开启
0x2:踏板3D软开关关闭";
BA_DEF_ SG_  "GenSigASIL" ENUM  "QM","A","B","C","D","vector_leerstring";
BA_DEF_ SG_  "ASIL" ENUM  "QM","A","B","C","D";
BA_DEF_ SG_  "E2EDataLength" INT 0 65535;
BA_DEF_ SG_  "GenSigInactiveValue" HEX 0 80000000;
BA_DEF_ SG_  "GenSigInvalidValue" HEX 0 281474976710655;
BA_DEF_ SG_  "GenSigStartValue" HEX 0 80000000;
BA_DEF_ SG_  "GenSigSendType" ENUM  "Cyclic","OnWrite","OnWriteWithRepetition","OnChange","OnChangeWithRepetition","IfActive","IfActiveWithRepetition","NoSigSendType";
BA_DEF_ BO_  "CANFD_BRS" ENUM  "0","1";
BA_DEF_ BO_  "DiagUudtResponse" ENUM  "True","False";
BA_DEF_ BO_  "GenMsgCycleTime" INT 0 65535;
BA_DEF_ BO_  "GenMsgCycleTimeFast" INT 0 65535;
BA_DEF_ BO_  "GenMsgDelayTime" INT 0 65535;
BA_DEF_ BO_  "GenMsgILSupport" ENUM  "No","Yes";
BA_DEF_ BO_  "GenMsgNrOfRepetition" INT 0 255;
BA_DEF_ BO_  "GenMsgSendType" ENUM  "Cyclic","Event","IfActive","CE","CA","NoMsgSendType";
BA_DEF_ BO_  "NmAsrMessage" ENUM  "No","Yes";
BA_DEF_ BO_  "NmMessage" ENUM  "No","Yes";
BA_DEF_ BO_  "SCP_AuthInfoTxLength" INT 9 512;
BA_DEF_ BO_  "SCP_FreshnessValueLength" INT 0 512;
BA_DEF_ BO_  "SCP_FreshnessValueTxLength" INT 0 512;
BA_DEF_ BO_  "VFrameFormat" ENUM  "StandardCAN","ExtendedCAN","reserved","J1939PG","reserved","reserved","reserved","reserved","reserved","reserved","reserved","reserved","reserved","reserved","StandardCAN_FD","ExtendedCAN_FD";
BA_DEF_DEF_  "GenSigASIL" "QM";
BA_DEF_DEF_  "ASIL" "QM";
BA_DEF_DEF_  "E2EDataLength" 64;
BA_DEF_DEF_  "GenSigInactiveValue" 0;
BA_DEF_DEF_  "GenSigInvalidValue" 0;
BA_DEF_DEF_  "GenSigStartValue" 0;
BA_DEF_DEF_  "GenSigSendType" "NoSigSendType";
BA_DEF_DEF_  "CANFD_BRS" "1";
BA_DEF_DEF_  "DiagUudtResponse" "True";
BA_DEF_DEF_  "GenMsgCycleTime" 0;
BA_DEF_DEF_  "GenMsgCycleTimeFast" 0;
BA_DEF_DEF_  "GenMsgDelayTime" 0;
BA_DEF_DEF_  "GenMsgILSupport" "Yes";
BA_DEF_DEF_  "GenMsgNrOfRepetition" 0;
BA_DEF_DEF_  "GenMsgSendType" "Cyclic";
BA_DEF_DEF_  "NmAsrMessage" "No";
BA_DEF_DEF_  "NmMessage" "No";
BA_DEF_DEF_  "SCP_AuthInfoTxLength" 28;
BA_DEF_DEF_  "SCP_FreshnessValueLength" 48;
BA_DEF_DEF_  "SCP_FreshnessValueTxLength" 4;
BA_DEF_DEF_  "VFrameFormat" "J1939PG";
BA_ "GenMsgNrOfRepetition" BO_ 1265 2;
BA_ "GenMsgCycleTime" BO_ 1265 100;
BA_ "GenMsgDelayTime" BO_ 1265 5;
BA_ "GenMsgCycleTimeFast" BO_ 1265 100;
BA_ "VFrameFormat" BO_ 1265 14;
BA_ "GenMsgCycleTime" BO_ 1267 100;
BA_ "VFrameFormat" BO_ 1267 14;
BA_ "GenMsgCycleTime" BO_ 1269 100;
BA_ "VFrameFormat" BO_ 1269 14;
BA_ "GenMsgCycleTime" BO_ 1271 100;
BA_ "VFrameFormat" BO_ 1271 14;
BA_ "GenMsgNrOfRepetition" BO_ 1273 2;
BA_ "GenMsgDelayTime" BO_ 1273 5;
BA_ "GenMsgCycleTimeFast" BO_ 1273 100;
BA_ "GenMsgSendType" BO_ 1273 1;
BA_ "VFrameFormat" BO_ 1273 14;
BA_ "GenMsgNrOfRepetition" BO_ 1276 2;
BA_ "GenMsgCycleTime" BO_ 1276 100;
BA_ "GenMsgDelayTime" BO_ 1276 5;
BA_ "GenMsgCycleTimeFast" BO_ 1276 50;
BA_ "VFrameFormat" BO_ 1276 14;
BA_ "GenMsgNrOfRepetition" BO_ 1279 2;
BA_ "GenMsgCycleTime" BO_ 1279 100;
BA_ "GenMsgDelayTime" BO_ 1279 5;
BA_ "GenMsgCycleTimeFast" BO_ 1279 50;
BA_ "VFrameFormat" BO_ 1279 14;
BA_ "GenMsgCycleTime" BO_ 1288 500;
BA_ "VFrameFormat" BO_ 1288 14;
BA_ "GenMsgCycleTime" BO_ 1289 500;
BA_ "VFrameFormat" BO_ 1289 14;
BA_ "GenMsgCycleTime" BO_ 1290 500;
BA_ "VFrameFormat" BO_ 1290 14;
BA_ "GenMsgCycleTime" BO_ 1291 500;
BA_ "VFrameFormat" BO_ 1291 14;
BA_ "GenMsgCycleTime" BO_ 1292 500;
BA_ "VFrameFormat" BO_ 1292 14;
BA_ "GenMsgCycleTime" BO_ 1295 500;
BA_ "VFrameFormat" BO_ 1295 14;
BA_ "GenMsgCycleTime" BO_ 1296 500;
BA_ "VFrameFormat" BO_ 1296 14;
BA_ "GenMsgCycleTime" BO_ 1299 500;
BA_ "VFrameFormat" BO_ 1299 14;
BA_ "GenMsgCycleTime" BO_ 1310 100;
BA_ "VFrameFormat" BO_ 1310 14;
BA_ "GenMsgCycleTime" BO_ 1312 500;
BA_ "VFrameFormat" BO_ 1312 14;
BA_ "GenMsgCycleTime" BO_ 1314 100;
BA_ "VFrameFormat" BO_ 1314 14;
BA_ "GenMsgCycleTime" BO_ 1316 500;
BA_ "VFrameFormat" BO_ 1316 14;
BA_ "GenMsgNrOfRepetition" BO_ 1318 2;
BA_ "GenMsgCycleTime" BO_ 1318 100;
BA_ "GenMsgDelayTime" BO_ 1318 5;
BA_ "GenMsgCycleTimeFast" BO_ 1318 100;
BA_ "VFrameFormat" BO_ 1318 14;
BA_ "GenMsgNrOfRepetition" BO_ 1320 2;
BA_ "GenMsgDelayTime" BO_ 1320 5;
BA_ "GenMsgCycleTimeFast" BO_ 1320 100;
BA_ "GenMsgSendType" BO_ 1320 1;
BA_ "VFrameFormat" BO_ 1320 14;
BA_ "GenMsgNrOfRepetition" BO_ 1322 2;
BA_ "GenMsgDelayTime" BO_ 1322 5;
BA_ "GenMsgCycleTimeFast" BO_ 1322 100;
BA_ "GenMsgSendType" BO_ 1322 1;
BA_ "VFrameFormat" BO_ 1322 14;
BA_ "GenMsgCycleTime" BO_ 1324 500;
BA_ "VFrameFormat" BO_ 1324 14;
BA_ "GenMsgNrOfRepetition" BO_ 1326 2;
BA_ "GenMsgDelayTime" BO_ 1326 5;
BA_ "GenMsgCycleTimeFast" BO_ 1326 100;
BA_ "GenMsgSendType" BO_ 1326 1;
BA_ "VFrameFormat" BO_ 1326 14;
BA_ "GenMsgCycleTime" BO_ 1328 100;
BA_ "VFrameFormat" BO_ 1328 14;
BA_ "GenMsgCycleTime" BO_ 1330 100;
BA_ "VFrameFormat" BO_ 1330 14;
BA_ "GenMsgNrOfRepetition" BO_ 1331 2;
BA_ "GenMsgDelayTime" BO_ 1331 5;
BA_ "GenMsgCycleTimeFast" BO_ 1331 100;
BA_ "GenMsgSendType" BO_ 1331 1;
BA_ "VFrameFormat" BO_ 1331 14;
BA_ "GenMsgNrOfRepetition" BO_ 1333 2;
BA_ "GenMsgDelayTime" BO_ 1333 5;
BA_ "GenMsgCycleTimeFast" BO_ 1333 100;
BA_ "GenMsgSendType" BO_ 1333 1;
BA_ "VFrameFormat" BO_ 1333 14;
BA_ "GenMsgNrOfRepetition" BO_ 1335 2;
BA_ "GenMsgCycleTime" BO_ 1335 100;
BA_ "GenMsgDelayTime" BO_ 1335 5;
BA_ "GenMsgCycleTimeFast" BO_ 1335 20;
BA_ "VFrameFormat" BO_ 1335 14;
BA_ "GenMsgNrOfRepetition" BO_ 1337 2;
BA_ "GenMsgDelayTime" BO_ 1337 5;
BA_ "GenMsgCycleTimeFast" BO_ 1337 100;
BA_ "GenMsgSendType" BO_ 1337 1;
BA_ "VFrameFormat" BO_ 1337 14;
BA_ "GenMsgCycleTime" BO_ 1338 500;
BA_ "VFrameFormat" BO_ 1338 14;
BA_ "GenMsgCycleTime" BO_ 1341 100;
BA_ "VFrameFormat" BO_ 1341 14;
BA_ "GenMsgNrOfRepetition" BO_ 1345 3;
BA_ "GenMsgCycleTime" BO_ 1345 100;
BA_ "GenMsgDelayTime" BO_ 1345 5;
BA_ "GenMsgCycleTimeFast" BO_ 1345 50;
BA_ "GenMsgSendType" BO_ 1345 3;
BA_ "VFrameFormat" BO_ 1345 14;
BA_ "GenMsgNrOfRepetition" BO_ 1349 3;
BA_ "GenMsgDelayTime" BO_ 1349 5;
BA_ "GenMsgCycleTimeFast" BO_ 1349 100;
BA_ "GenMsgSendType" BO_ 1349 1;
BA_ "VFrameFormat" BO_ 1349 14;
BA_ "GenMsgNrOfRepetition" BO_ 1351 3;
BA_ "GenMsgDelayTime" BO_ 1351 5;
BA_ "GenMsgCycleTimeFast" BO_ 1351 100;
BA_ "GenMsgSendType" BO_ 1351 1;
BA_ "VFrameFormat" BO_ 1351 14;
BA_ "GenMsgNrOfRepetition" BO_ 1353 3;
BA_ "GenMsgDelayTime" BO_ 1353 5;
BA_ "GenMsgCycleTimeFast" BO_ 1353 100;
BA_ "GenMsgSendType" BO_ 1353 1;
BA_ "VFrameFormat" BO_ 1353 14;
BA_ "GenMsgNrOfRepetition" BO_ 1354 2;
BA_ "GenMsgDelayTime" BO_ 1354 5;
BA_ "GenMsgCycleTimeFast" BO_ 1354 100;
BA_ "GenMsgSendType" BO_ 1354 1;
BA_ "VFrameFormat" BO_ 1354 14;
BA_ "GenMsgNrOfRepetition" BO_ 1356 2;
BA_ "GenMsgDelayTime" BO_ 1356 5;
BA_ "GenMsgCycleTimeFast" BO_ 1356 100;
BA_ "GenMsgSendType" BO_ 1356 1;
BA_ "VFrameFormat" BO_ 1356 14;
BA_ "GenMsgNrOfRepetition" BO_ 1358 3;
BA_ "GenMsgDelayTime" BO_ 1358 5;
BA_ "GenMsgCycleTimeFast" BO_ 1358 100;
BA_ "GenMsgSendType" BO_ 1358 1;
BA_ "VFrameFormat" BO_ 1358 14;
BA_ "GenMsgNrOfRepetition" BO_ 1360 2;
BA_ "GenMsgCycleTime" BO_ 1360 100;
BA_ "GenMsgDelayTime" BO_ 1360 5;
BA_ "GenMsgCycleTimeFast" BO_ 1360 100;
BA_ "VFrameFormat" BO_ 1360 14;
BA_ "GenMsgCycleTime" BO_ 1361 100;
BA_ "VFrameFormat" BO_ 1361 14;
BA_ "GenSigSendType" SG_ 1265 ICC_PwrOff 0;
BA_ "GenSigSendType" SG_ 1265 ICC_EtmEgySave 0;
BA_ "GenSigSendType" SG_ 1265 ICC_HoodSW 2;
BA_ "GenSigSendType" SG_ 1265 ICC_GloveboxSW 2;
BA_ "GenSigSendType" SG_ 1265 ICC_ChrgPortCover_Switch 2;
BA_ "GenSigSendType" SG_ 1265 ICC_ReWinDefrstSwt 2;
BA_ "GenSigSendType" SG_ 1265 ICC_RearMirrorFoldCmd 2;
BA_ "GenSigSendType" SG_ 1265 ICC_CenterLockSwt 2;
BA_ "GenSigSendType" SG_ 1265 ICC_ReverseExtMirrorSts 2;
BA_ "GenSigSendType" SG_ 1265 ICC_LightMainSwitchSts 2;
BA_ "GenSigSendType" SG_ 1265 ICC_AutoFoldSts 2;
BA_ "GenSigSendType" SG_ 1265 ICC_HeadlampHeightSts 2;
BA_ "GenSigSendType" SG_ 1265 ICC_WiprSnvty 2;
BA_ "GenSigSendType" SG_ 1265 ICC_WindowCmd 2;
BA_ "GenSigSendType" SG_ 1265 ICC_LowBeamDelayOff 2;
BA_ "GenSigInvalidValue" SG_ 1265 DrvWinCmd_4F1h 127;
BA_ "GenSigSendType" SG_ 1265 DrvWinCmd_4F1h 2;
BA_ "GenSigInvalidValue" SG_ 1265 PassWinCmd_4F1h 127;
BA_ "GenSigSendType" SG_ 1265 PassWinCmd_4F1h 2;
BA_ "GenSigInvalidValue" SG_ 1265 DrvRearWinCmd_4F1h 127;
BA_ "GenSigSendType" SG_ 1265 DrvRearWinCmd_4F1h 2;
BA_ "GenSigInvalidValue" SG_ 1265 PassRearWinCmd_4F1h 127;
BA_ "GenSigSendType" SG_ 1265 PassRearWinCmd_4F1h 2;
BA_ "GenSigSendType" SG_ 1265 ICC_FGHeatSts 4;
BA_ "GenSigSendType" SG_ 1265 ICC_AutolockSts 2;
BA_ "GenSigSendType" SG_ 1265 ICC_WiperID 2;
BA_ "GenSigSendType" SG_ 1265 ICC_MaintenanceMode 2;
BA_ "GenSigSendType" SG_ 1265 ICC_lockSetSwitchSts 2;
BA_ "GenSigSendType" SG_ 1265 ICC_ChildLockSW 2;
BA_ "GenSigSendType" SG_ 1265 ICC_ParkUnlockEnable 2;
BA_ "GenSigSendType" SG_ 1265 ICC_BLEOpenDriverDoorEnable 2;
BA_ "GenSigSendType" SG_ 1265 ICC_WinInhbSwt 2;
BA_ "GenSigSendType" SG_ 1265 ICC_SteerWhlHeatgSwt 2;
BA_ "GenSigSendType" SG_ 1265 ICC_AutoHeatingset 2;
BA_ "GenSigSendType" SG_ 1265 ICC_FrontFogSw 2;
BA_ "GenSigSendType" SG_ 1265 ICC_RearFogSw 2;
BA_ "GenSigSendType" SG_ 1265 ICC_DoorControlSW 2;
BA_ "GenSigSendType" SG_ 1265 ICC_LockCarWinCloseSw 2;
BA_ "GenSigSendType" SG_ 1265 ICC_NapStatusSet 2;
BA_ "GenSigSendType" SG_ 1265 ICC_NapAreaSet 2;
BA_ "GenSigSendType" SG_ 1265 ICC_EasyEntryExitSet 2;
BA_ "GenSigSendType" SG_ 1265 ICC_RainCarWinCloseSw 2;
BA_ "GenSigSendType" SG_ 1265 ICC_NapTimeSet 2;
BA_ "GenSigInvalidValue" SG_ 1265 ICC_NapSetTemperature 31;
BA_ "GenSigStartValue" SG_ 1265 ICC_NapSetTemperature 31;
BA_ "GenSigSendType" SG_ 1265 ICC_NapSetTemperature 2;
BA_ "GenSigSendType" SG_ 1265 ICC_NapCFSStatusSet 2;
BA_ "GenSigSendType" SG_ 1265 ICC_HazardLightReq 0;
BA_ "GenSigSendType" SG_ 1265 ICC_SpoilerCtrlCmd 2;
BA_ "GenSigSendType" SG_ 1265 ICC_SpoilerWelcomeFunSet 2;
BA_ "GenSigSendType" SG_ 1265 ICC_CinemaStatus 0;
BA_ "GenSigSendType" SG_ 1265 ICC_MusicStatus 0;
BA_ "GenSigSendType" SG_ 1267 RRCR_1_CRC1 0;
BA_ "GenSigSendType" SG_ 1267 RRCR_1_RollgCntr1 0;
BA_ "GenSigSendType" SG_ 1267 RRCR_1_Resd1 0;
BA_ "ASIL" SG_ 1267 RRCR_1_SysSt 2;
BA_ "GenSigSendType" SG_ 1267 RRCR_1_SysSt 0;
BA_ "ASIL" SG_ 1267 RRCR_1_BlkSts 2;
BA_ "GenSigSendType" SG_ 1267 RRCR_1_BlkSts 0;
BA_ "GenSigSendType" SG_ 1267 RRCR_1_BSDWarn 0;
BA_ "GenSigSendType" SG_ 1267 RRCR_1_DOWWarn 0;
BA_ "GenSigSendType" SG_ 1267 RRCR_1_DowLock 0;
BA_ "ASIL" SG_ 1267 RRCR_1_ELK_Collision_flag 2;
BA_ "GenSigSendType" SG_ 1267 RRCR_1_ELK_Collision_flag 0;
BA_ "ASIL" SG_ 1267 RRCR_1_ELK_CollisionFlagValid 2;
BA_ "GenSigSendType" SG_ 1267 RRCR_1_ELK_CollisionFlagValid 0;
BA_ "GenSigSendType" SG_ 1269 LISDShowCMDSts 0;
BA_ "GenSigSendType" SG_ 1269 LISDShowModeSts 0;
BA_ "GenSigSendType" SG_ 1269 LISDTransmitStatus 0;
BA_ "GenSigSendType" SG_ 1269 LISDDisplayStatus 0;
BA_ "GenSigSendType" SG_ 1269 LISD_ParkingShowModSts 0;
BA_ "GenSigSendType" SG_ 1269 LISD_ParkingShowCMDSts 0;
BA_ "GenSigSendType" SG_ 1271 RRCR_2_CRC1 0;
BA_ "GenSigSendType" SG_ 1271 RRCR_2_RollgCntr1 0;
BA_ "GenSigSendType" SG_ 1271 RRCR_2_Resd1 0;
BA_ "GenSigSendType" SG_ 1271 RRCR_2_RCWWarn 0;
BA_ "GenSigSendType" SG_ 1271 RRCR_2_RCTAWarn 0;
BA_ "GenSigSendType" SG_ 1271 RRCR_2_BSDLCWONOFFSts 0;
BA_ "GenSigSendType" SG_ 1271 RRCR_2_DOWONOFFSts 0;
BA_ "GenSigSendType" SG_ 1271 RRCR_2_RCWONOFFSts 0;
BA_ "GenSigSendType" SG_ 1271 RRCR_2_RCTARCTBONOFFSts 0;
BA_ "GenSigSendType" SG_ 1273 FaceID 2;
BA_ "GenSigSendType" SG_ 1273 DrvSeatExtMirPosRecallID_4F9h 2;
BA_ "GenSigSendType" SG_ 1273 DrvSeatExtMirPosStoreReqID_4F9h 2;
BA_ "GenSigSendType" SG_ 1276 PassSeatHeiAdjmt_Target 2;
BA_ "GenSigSendType" SG_ 1276 SeatBackAndFwdAdjmt_Target 2;
BA_ "GenSigSendType" SG_ 1276 SeatBackAgAdjmt_Target 2;
BA_ "GenSigSendType" SG_ 1276 Set_ProfileID 2;
BA_ "GenSigSendType" SG_ 1276 SeatCushAgAdjmt_Target 2;
BA_ "GenSigSendType" SG_ 1276 LgRstFwdAndBckAdjmt_Target 2;
BA_ "GenSigSendType" SG_ 1276 FootRestAdjmt_Target 2;
BA_ "GenSigSendType" SG_ 1276 REQ_SeatPosRecall 2;
BA_ "GenSigSendType" SG_ 1276 REQ_SeatPosStore 2;
BA_ "GenSigStartValue" SG_ 1276 Set_ToDefault 7;
BA_ "GenSigSendType" SG_ 1276 Set_ToDefault 2;
BA_ "GenSigStartValue" SG_ 1276 Set_EasyEntryEnable 3;
BA_ "GenSigSendType" SG_ 1276 Set_EasyEntryEnable 2;
BA_ "GenSigSendType" SG_ 1276 REQ_SeatHeatPass 2;
BA_ "GenSigSendType" SG_ 1276 REQ_SeatVentPass 2;
BA_ "GenSigSendType" SG_ 1276 PassSeatMsgStr_LvlCmd 2;
BA_ "GenSigSendType" SG_ 1276 PassSeatMsg_ModeCmd 2;
BA_ "GenSigSendType" SG_ 1279 ICC_SentinelModeSts 0;
BA_ "GenSigSendType" SG_ 1279 Weather_Type 0;
BA_ "GenSigSendType" SG_ 1279 ICC_CameraErrorCode 0;
BA_ "GenSigSendType" SG_ 1279 ICC_SentinelRequest 2;
BA_ "GenSigSendType" SG_ 1279 ICC_StartDeInitCameraStream 2;
BA_ "GenSigSendType" SG_ 1279 ICC_CameraRecoveryRequest 2;
BA_ "GenSigSendType" SG_ 1279 ICC_CleanMode_4FFh 2;
BA_ "GenSigSendType" SG_ 1288 CurrentTimeYear_508h 0;
BA_ "GenSigStartValue" SG_ 1288 CurrentTimeMonth_508h 1;
BA_ "GenSigSendType" SG_ 1288 CurrentTimeMonth_508h 0;
BA_ "GenSigStartValue" SG_ 1288 CurrentTimeDay_508h 1;
BA_ "GenSigSendType" SG_ 1288 CurrentTimeDay_508h 0;
BA_ "GenSigSendType" SG_ 1288 CurrentTimeHour_508h 0;
BA_ "GenSigSendType" SG_ 1288 CurrentTimeMinute_508h 0;
BA_ "GenSigSendType" SG_ 1288 CurrentTimeSecond_508h 0;
BA_ "GenSigSendType" SG_ 1289 ICC_ToggleUnits 0;
BA_ "GenSigSendType" SG_ 1289 ICC_TireTemperatureDisplayUnit 0;
BA_ "GenSigSendType" SG_ 1289 ICC_TirePressureDisplayUnit 0;
BA_ "GenSigSendType" SG_ 1289 ICC_GPSSwitchSet 0;
BA_ "GenSigSendType" SG_ 1289 ICC_BtConFlag 0;
BA_ "GenSigSendType" SG_ 1289 ICC_LanguageSet_509h 0;
BA_ "GenSigSendType" SG_ 1289 ICC_Day_Displaysts_509h 0;
BA_ "GenSigSendType" SG_ 1290 BMS_8_CRC1 0;
BA_ "GenSigSendType" SG_ 1290 BMS_8_RollgCntr1 0;
BA_ "GenSigSendType" SG_ 1290 BMS_8_Resd1 0;
BA_ "ASIL" SG_ 1290 BMS_HvBattCellOverU 3;
BA_ "GenSigSendType" SG_ 1290 BMS_HvBattCellOverU 0;
BA_ "ASIL" SG_ 1290 BMS_HvBattCellUnderU 3;
BA_ "GenSigSendType" SG_ 1290 BMS_HvBattCellUnderU 0;
BA_ "ASIL" SG_ 1290 BMS_HvBattUnderU 3;
BA_ "GenSigSendType" SG_ 1290 BMS_HvBattUnderU 0;
BA_ "ASIL" SG_ 1290 BMS_HvBattDischargeOverCurrent 3;
BA_ "GenSigSendType" SG_ 1290 BMS_HvBattDischargeOverCurrent 0;
BA_ "ASIL" SG_ 1290 BMS_HvBattChargeOverCurrent 3;
BA_ "GenSigSendType" SG_ 1290 BMS_HvBattChargeOverCurrent 0;
BA_ "ASIL" SG_ 1290 BMS_HvBattOverU 3;
BA_ "GenSigSendType" SG_ 1290 BMS_HvBattOverU 0;
BA_ "GenSigSendType" SG_ 1290 BMS_HvBattMismatching 0;
BA_ "GenSigSendType" SG_ 1290 BMS_HvBattSocJump 0;
BA_ "GenSigSendType" SG_ 1290 BMS_HvBattCellUUnif 0;
BA_ "GenSigSendType" SG_ 1290 BMS_HvBattLowSoc 0;
BA_ "GenSigSendType" SG_ 1290 BMS_HvBattOverSoc 0;
BA_ "GenSigSendType" SG_ 1290 BMS_HvBattTempUniformity 0;
BA_ "GenSigSendType" SG_ 1290 BMS_BattInterCANErr 0;
BA_ "ASIL" SG_ 1290 BMS_HvBattOverCharging 3;
BA_ "GenSigSendType" SG_ 1290 BMS_HvBattOverCharging 0;
BA_ "ASIL" SG_ 1290 BMS_HvBattOverTemperature 3;
BA_ "GenSigSendType" SG_ 1290 BMS_HvBattOverTemperature 0;
BA_ "GenSigSendType" SG_ 1291 BMS_2_G_CRC 0;
BA_ "GenSigSendType" SG_ 1291 BMS_2_G_RollgCntr 0;
BA_ "GenSigSendType" SG_ 1291 BMS_2_G_Resd 0;
BA_ "GenSigSendType" SG_ 1291 BMS_TBOXInsulation_R 0;
BA_ "GenSigSendType" SG_ 1291 BMS_TBOXErrorNumber 0;
BA_ "GenSigInvalidValue" SG_ 1291 BMS_TBOXHvBattMaxT 255;
BA_ "GenSigStartValue" SG_ 1291 BMS_TBOXHvBattMaxT 255;
BA_ "GenSigSendType" SG_ 1291 BMS_TBOXHvBattMaxT 0;
BA_ "GenSigInvalidValue" SG_ 1291 BMS_TBOXHvBattMinT 255;
BA_ "GenSigStartValue" SG_ 1291 BMS_TBOXHvBattMinT 255;
BA_ "GenSigSendType" SG_ 1291 BMS_TBOXHvBattMinT 0;
BA_ "GenSigInvalidValue" SG_ 1291 BMS_SOCLight 127;
BA_ "ASIL" SG_ 1291 BMS_SOCLight 2;
BA_ "GenSigSendType" SG_ 1291 BMS_SOCLight 0;
BA_ "GenSigSendType" SG_ 1292 CHB_AppDelay_Sts 0;
BA_ "GenSigSendType" SG_ 1292 CHB_AppMem_Sts 0;
BA_ "GenSigSendType" SG_ 1292 CHB_App_Sts 0;
BA_ "GenSigInvalidValue" SG_ 1292 CHB_AppTimeset_Sts 31;
BA_ "GenSigSendType" SG_ 1292 CHB_AppTimeset_Sts 0;
BA_ "GenSigSendType" SG_ 1292 CHB_AppCoolorheat_Sts 0;
BA_ "GenSigSendType" SG_ 1292 CHB_AppCoolset_Sts 0;
BA_ "GenSigSendType" SG_ 1292 CHB_AppHeatset_Sts 0;
BA_ "GenSigSendType" SG_ 1292 CHB_AppItemsLeft_Sts 0;
BA_ "GenSigSendType" SG_ 1292 CHB_AppSterilization_Sts 0;
BA_ "GenSigSendType" SG_ 1292 CHB_AppChbDoor_Sts 0;
BA_ "GenSigSendType" SG_ 1292 CHB_AppItemsLeftset_Sts 0;
BA_ "GenSigInvalidValue" SG_ 1295 BMS_RemainChg_Time 2047;
BA_ "GenSigSendType" SG_ 1295 BMS_RemainChg_Time 0;
BA_ "GenSigSendType" SG_ 1295 BMS_BattFaultLampSts 0;
BA_ "GenSigSendType" SG_ 1295 BMS_OverTemp_LightSts 0;
BA_ "ASIL" SG_ 1295 BMS_ThermalRunawayDis 3;
BA_ "GenSigSendType" SG_ 1295 BMS_ThermalRunawayDis 0;
BA_ "ASIL" SG_ 1295 BMS_TBOXIsolationFault 2;
BA_ "GenSigSendType" SG_ 1295 BMS_TBOXIsolationFault 0;
BA_ "GenSigSendType" SG_ 1295 BMS_PreWarmDis 0;
BA_ "GenSigSendType" SG_ 1296 CurrentTimeYear 0;
BA_ "GenSigStartValue" SG_ 1296 CurrentTimeMonth 1;
BA_ "GenSigSendType" SG_ 1296 CurrentTimeMonth 0;
BA_ "GenSigStartValue" SG_ 1296 CurrentTimeDay 1;
BA_ "GenSigSendType" SG_ 1296 CurrentTimeDay 0;
BA_ "GenSigSendType" SG_ 1296 CurrentTimeHour 0;
BA_ "GenSigSendType" SG_ 1296 CurrentTimeMinute 0;
BA_ "GenSigSendType" SG_ 1296 CurrentTimeSecond 0;
BA_ "GenSigInvalidValue" SG_ 1299 BMS_PackVoltageDis 65535;
BA_ "GenSigStartValue" SG_ 1299 BMS_PackVoltageDis 65535;
BA_ "GenSigSendType" SG_ 1299 BMS_PackVoltageDis 0;
BA_ "GenSigInvalidValue" SG_ 1299 BMS_PackCurrentDis 65535;
BA_ "GenSigStartValue" SG_ 1299 BMS_PackCurrentDis 65535;
BA_ "GenSigSendType" SG_ 1299 BMS_PackCurrentDis 0;
BA_ "GenSigSendType" SG_ 1310 DrvSecSeatEasyEntryExitFb_51Eh 0;
BA_ "GenSigSendType" SG_ 1310 PassSecSeatEasyEntryExitFb_51Eh 0;
BA_ "GenSigSendType" SG_ 1310 DrvSecSeatNeedMemory_51Eh 0;
BA_ "GenSigSendType" SG_ 1310 DrvSecMemoryFb_51Eh 0;
BA_ "GenSigSendType" SG_ 1310 DrvSecRecoverFb_51Eh 0;
BA_ "GenSigSendType" SG_ 1310 PassSecSeatNeedMemory_51Eh 0;
BA_ "GenSigSendType" SG_ 1310 PassSecMemoryFb_51Eh 0;
BA_ "GenSigSendType" SG_ 1310 PassSecRecoverFb_51Eh 0;
BA_ "GenSigSendType" SG_ 1310 DrvSecSeatLvlFb_51Eh 0;
BA_ "GenSigSendType" SG_ 1310 DrvSecSeatBackAgFb_51Eh 0;
BA_ "GenSigSendType" SG_ 1310 DrvSecSeatLegSpprtFb_51Eh 0;
BA_ "GenSigSendType" SG_ 1310 DrvSecSeatLegRestAngleFb_51Eh 0;
BA_ "GenSigSendType" SG_ 1310 PassSecSeatLvlFb_51Eh 0;
BA_ "GenSigSendType" SG_ 1310 PassSecSeatBackAgFb_51Eh 0;
BA_ "GenSigSendType" SG_ 1310 PassSecSeatLegSpprtFb_51Eh 0;
BA_ "GenSigSendType" SG_ 1310 PassSecSeatLegRestAngleFb_51Eh 0;
BA_ "GenSigSendType" SG_ 1310 DrvTrdSeatBackAgFb_51Eh 0;
BA_ "GenSigSendType" SG_ 1310 PassTrdSeatBackAgFb_51Eh 0;
BA_ "GenSigSendType" SG_ 1310 DrvTrdSeatFrontFlipFb_51Eh 0;
BA_ "GenSigSendType" SG_ 1310 PassTrdSeatFrontFlipFb_51Eh 0;
BA_ "GenSigSendType" SG_ 1310 PassSecSeatExpSwCmd_51Eh 0;
BA_ "GenSigSendType" SG_ 1310 PassTrdSeatSwCmd_51Eh 0;
BA_ "GenSigSendType" SG_ 1310 BBCM_RLSeatSwCmd3rd 0;
BA_ "GenSigSendType" SG_ 1310 BBCM_RLSeatExpSwCmd2rd 0;
BA_ "GenSigSendType" SG_ 1310 BBCM_RLSeatExpSwSt2rd 0;
BA_ "GenSigSendType" SG_ 1310 PassSecSeatExpSwSt_51Eh 0;
BA_ "GenSigSendType" SG_ 1310 BBCM_RRSeatZeroFb2nd 0;
BA_ "GenSigSendType" SG_ 1310 BBCM_RLSeatZeroFb2nd 0;
BA_ "GenSigSendType" SG_ 1310 BBCM_RLSeatExpRstStsFb 0;
BA_ "GenSigSendType" SG_ 1310 PassSecSeatMovFailCause_51Eh 0;
BA_ "GenSigSendType" SG_ 1310 DrvSecSeatMovFailCause_51Eh 0;
BA_ "GenSigSendType" SG_ 1310 PassTrdSeatMovFailCause_51Eh 0;
BA_ "GenSigSendType" SG_ 1310 DrvTrdSeatMovFailCause_51Eh 0;
BA_ "GenSigSendType" SG_ 1312 ICC_TotalFaultNum 0;
BA_ "GenSigSendType" SG_ 1312 ICC_FrameIndex 0;
BA_ "GenSigSendType" SG_ 1312 ICC_SupplierNum 0;
BA_ "GenSigSendType" SG_ 1312 ICC_FaultNum1 0;
BA_ "GenSigSendType" SG_ 1312 ICC_FaultNum2 0;
BA_ "GenSigSendType" SG_ 1312 ICC_FaultNum3 0;
BA_ "GenSigSendType" SG_ 1312 ICC_FaultNum4 0;
BA_ "GenSigSendType" SG_ 1312 ICC_FaultNum5 0;
BA_ "GenSigSendType" SG_ 1312 ICC_FaultNum6 0;
BA_ "GenSigSendType" SG_ 1312 ICC_FaultNum7 0;
BA_ "GenSigSendType" SG_ 1312 ICC_FaultNum8 0;
BA_ "GenSigSendType" SG_ 1312 ICC_FaultNum9 0;
BA_ "GenSigSendType" SG_ 1312 ICC_FaultNum10 0;
BA_ "GenSigSendType" SG_ 1312 ICC_FaultNum11 0;
BA_ "GenSigSendType" SG_ 1312 ICC_FaultNum12 0;
BA_ "GenSigSendType" SG_ 1312 ICC_FaultNum13 0;
BA_ "GenSigSendType" SG_ 1312 ICC_FaultNum14 0;
BA_ "GenSigSendType" SG_ 1312 ICC_FaultNum15 0;
BA_ "GenSigSendType" SG_ 1312 ICC_FaultNum16 0;
BA_ "GenSigSendType" SG_ 1312 ICC_FaultNum17 0;
BA_ "GenSigSendType" SG_ 1312 ICC_FaultNum18 0;
BA_ "GenSigSendType" SG_ 1312 ICC_FaultNum19 0;
BA_ "GenSigSendType" SG_ 1312 ICC_FaultNum20 0;
BA_ "GenSigSendType" SG_ 1314 HCU_V2lDisChgBck 0;
BA_ "GenSigSendType" SG_ 1314 HCU_DisChgMemFed 0;
BA_ "GenSigSendType" SG_ 1314 HCU_V2VDisChgBck 0;
BA_ "GenSigSendType" SG_ 1314 HCU_V2l_IntlDisChgBck 0;
BA_ "GenSigSendType" SG_ 1314 HCU_FuelDetnOpDefeated 0;
BA_ "GenSigInvalidValue" SG_ 1314 HCU_FuelDetnModSwtFed 3;
BA_ "GenSigSendType" SG_ 1314 HCU_FuelDetnModSwtFed 0;
BA_ "GenSigInvalidValue" SG_ 1314 HCU_FuelDetnStateFed 3;
BA_ "GenSigSendType" SG_ 1314 HCU_FuelDetnStateFed 0;
BA_ "GenSigInvalidValue" SG_ 1314 HCU_HVDownRepairModeFed 3;
BA_ "GenSigSendType" SG_ 1314 HCU_HVDownRepairModeFed 0;
BA_ "GenSigSendType" SG_ 1314 HCU_SumFuCns 0;
BA_ "GenSigInvalidValue" SG_ 1314 HCU_TrailerMode 3;
BA_ "GenSigSendType" SG_ 1314 HCU_TrailerMode 0;
BA_ "GenSigSendType" SG_ 1314 HCU_TABSwtFed_522h 0;
BA_ "GenSigSendType" SG_ 1314 HCU_KeyDriveModememory 0;
BA_ "GenSigSendType" SG_ 1314 HCU_DrivePowerDispSetFed 0;
BA_ "GenSigInvalidValue" SG_ 1314 HCU_EXPERTNormFed 3;
BA_ "GenSigSendType" SG_ 1314 HCU_EXPERTNormFed 0;
BA_ "GenSigSendType" SG_ 1314 HCU_4LModeFed 0;
BA_ "GenSigInvalidValue" SG_ 1314 HCU_EXPERTEcoFed 3;
BA_ "GenSigSendType" SG_ 1314 HCU_EXPERTEcoFed 0;
BA_ "GenSigSendType" SG_ 1314 HCU_SingleRegnRmn 0;
BA_ "GenSigSendType" SG_ 1314 HCU_DRIFTModeSts 0;
BA_ "GenSigInvalidValue" SG_ 1314 HCU_EXPERTAWDFed 3;
BA_ "GenSigSendType" SG_ 1314 HCU_EXPERTAWDFed 0;
BA_ "GenSigInvalidValue" SG_ 1314 HCU_EXPERTRWDFed 3;
BA_ "GenSigSendType" SG_ 1314 HCU_EXPERTRWDFed 0;
BA_ "GenSigInvalidValue" SG_ 1314 HCU_CrossaxisFed 3;
BA_ "GenSigSendType" SG_ 1314 HCU_CrossaxisFed 0;
BA_ "GenSigInvalidValue" SG_ 1314 HCU_EXPERTSportFed 3;
BA_ "GenSigSendType" SG_ 1314 HCU_EXPERTSportFed 0;
BA_ "GenSigSendType" SG_ 1314 HCU_StopChrgnModeFed 0;
BA_ "GenSigInvalidValue" SG_ 1314 HCU_StopChrgnFed 3;
BA_ "GenSigSendType" SG_ 1314 HCU_StopChrgnFed 0;
BA_ "GenSigInvalidValue" SG_ 1314 HCU_CLIMBFed 3;
BA_ "GenSigSendType" SG_ 1314 HCU_CLIMBFed 0;
BA_ "GenSigInvalidValue" SG_ 1314 HCU_EXPERTAutoFed 3;
BA_ "GenSigSendType" SG_ 1314 HCU_EXPERTAutoFed 0;
BA_ "GenSigSendType" SG_ 1314 HCU_HEV_FunctionLimit 0;
BA_ "GenSigSendType" SG_ 1314 HCU_ParkingChargeReminder 0;
BA_ "GenSigSendType" SG_ 1314 HCU_PowerCut 0;
BA_ "GenSigSendType" SG_ 1314 HCU_IMMOReleaseSignal 0;
BA_ "GenSigSendType" SG_ 1314 HCU_LVPowSupSYSAbn_lit 0;
BA_ "GenSigSendType" SG_ 1314 HCU_ChrgnFctMemSt 0;
BA_ "GenSigSendType" SG_ 1314 HCU_PowerModeChangeInhibit 0;
BA_ "GenSigSendType" SG_ 1314 HCU_DisconnectChagWarn 0;
BA_ "GenSigSendType" SG_ 1314 HCU_EngineRunClmReq 0;
BA_ "GenSigSendType" SG_ 1314 HCU_VehicleSpeedMax_Limit 0;
BA_ "GenSigSendType" SG_ 1314 HCU_AccleAbility_Limit 0;
BA_ "GenSigSendType" SG_ 1314 HCU_DriveInhibit_GearP 0;
BA_ "GenSigSendType" SG_ 1314 HCU_SetModeNotChange 0;
BA_ "GenSigSendType" SG_ 1314 HCU_UTURNSnowFed 0;
BA_ "GenSigSendType" SG_ 1314 HCU_PowerLevel 0;
BA_ "GenSigSendType" SG_ 1314 HCU_TowingModeEna 0;
BA_ "GenSigSendType" SG_ 1314 HCU_LeaveVehicleWarning 0;
BA_ "GenSigSendType" SG_ 1314 HCU_DedicatedModeInhibit 0;
BA_ "GenSigSendType" SG_ 1314 HCU_DisChargeStopFault 0;
BA_ "GenSigSendType" SG_ 1314 HCU_RearEDLSts 0;
BA_ "GenSigSendType" SG_ 1314 HCU_FrntEDLSts 0;
BA_ "GenSigSendType" SG_ 1314 HCU_CruiseLimitSpeedValue 0;
BA_ "GenSigSendType" SG_ 1314 HCU_DriveMode_JT 0;
BA_ "GenSigSendType" SG_ 1314 HCU_SocManageFed 0;
BA_ "GenSigSendType" SG_ 1314 HCU_SinglePedalMemFed 0;
BA_ "GenSigSendType" SG_ 1314 HCU_CCOSwtFed 0;
BA_ "GenSigStartValue" SG_ 1314 HCU_Pwr 2000;
BA_ "GenSigSendType" SG_ 1314 HCU_Pwr 0;
BA_ "GenSigSendType" SG_ 1314 HCU_DrvGearShiftFailureIndcn 0;
BA_ "GenSigSendType" SG_ 1314 HCU_UTURNSandFed 0;
BA_ "GenSigSendType" SG_ 1314 HCU_CruiseControlStatus 0;
BA_ "GenSigSendType" SG_ 1314 HCU_EXPERTEESPSet 0;
BA_ "GenSigSendType" SG_ 1314 HCU_EgyRegenLevel 0;
BA_ "GenSigSendType" SG_ 1314 HCU_EngyFlowToDisp 0;
BA_ "GenSigSendType" SG_ 1314 HCU_UTURNGrassFed 0;
BA_ "GenSigSendType" SG_ 1314 HCU_UTURNMudFed 0;
BA_ "GenSigSendType" SG_ 1314 HCU_LTCDispFed 0;
BA_ "GenSigSendType" SG_ 1314 HCU_iTAS_Warn 0;
BA_ "GenSigSendType" SG_ 1314 HCU_iCCO_Warn 0;
BA_ "GenSigSendType" SG_ 1314 HCU_DriveModeChangeFail 0;
BA_ "GenSigSendType" SG_ 1314 HCU_25_Crossaxis_Warn 0;
BA_ "GenSigSendType" SG_ 1314 HCU_25_EDLFed 0;
BA_ "GenSigSendType" SG_ 1314 HCU_DraggingModeRemind 0;
BA_ "GenSigSendType" SG_ 1314 HCU_iTASSceneReq 0;
BA_ "GenSigSendType" SG_ 1314 HCU_25_iTAS_SlopWarn 0;
BA_ "GenSigSendType" SG_ 1314 HCU_ExterTempLowHint 0;
BA_ "GenSigSendType" SG_ 1314 HCU_iTAS_Active 0;
BA_ "GenSigSendType" SG_ 1314 HCU_25_VehSpdOffroadRmn 0;
BA_ "GenSigSendType" SG_ 1314 HCU_DrivingModReq 0;
BA_ "GenSigSendType" SG_ 1314 HCU_25_iDRIFT_Warn 0;
BA_ "GenSigSendType" SG_ 1314 HCU_25_SetVehSpdOffroad 0;
BA_ "GenSigSendType" SG_ 1314 HCU_25_LaunchMod_Warn 0;
BA_ "GenSigSendType" SG_ 1314 HCU_25_TAB_Warn 0;
BA_ "GenSigSendType" SG_ 1314 HCU_25_CCO_TextDisp 0;
BA_ "GenSigSendType" SG_ 1314 HCU_25_DCM_Warn 0;
BA_ "GenSigSendType" SG_ 1314 HCU_25_CCMFed 0;
BA_ "GenSigInvalidValue" SG_ 1314 HCU_SumElecCns 4095;
BA_ "GenSigSendType" SG_ 1314 HCU_SumElecCns 0;
BA_ "GenSigSendType" SG_ 1314 HCU_CrossBorderSts 0;
BA_ "GenSigSendType" SG_ 1314 HCU_DischgSetSOCFed 0;
BA_ "GenSigSendType" SG_ 1314 HCU_facCleverDrvAct_522h 0;
BA_ "GenSigSendType" SG_ 1314 HCU_stCleverDrvAct_522h 0;
BA_ "GenSigSendType" SG_ 1314 HCU_stCleverRgnAct_522h 0;
BA_ "GenSigSendType" SG_ 1314 HCU_stCleverMainAct_522h 0;
BA_ "GenSigSendType" SG_ 1314 EnergySavingModeSts_522h 0;
BA_ "GenSigSendType" SG_ 1314 HCU_facCleverDrvActRstFed_522h 0;
BA_ "GenSigSendType" SG_ 1314 HCU_SailramainingT_Indc_522h 0;
BA_ "GenSigSendType" SG_ 1314 HCU_ATCM_Operation_REQ_522h 0;
BA_ "GenSigSendType" SG_ 1314 HCU_ModeSwFailureIndc_522h 0;
BA_ "GenSigSendType" SG_ 1314 HCU_Sailmode_522h 0;
BA_ "GenSigSendType" SG_ 1314 HCU_CarSickRelfModeFb 0;
BA_ "GenSigSendType" SG_ 1314 HCU_DeepSnowSts_522h 0;
BA_ "GenSigSendType" SG_ 1314 DriveModeChangeFailReason_522h 0;
BA_ "GenSigSendType" SG_ 1314 HCU_CarSickRelfModeDisReason 0;
BA_ "GenSigSendType" SG_ 1314 HCU_DCMSwtFed 0;
BA_ "GenSigInvalidValue" SG_ 1316 LHFTireTemperature 255;
BA_ "GenSigSendType" SG_ 1316 LHFTireTemperature 0;
BA_ "GenSigInvalidValue" SG_ 1316 RHFTireTemperature 255;
BA_ "GenSigSendType" SG_ 1316 RHFTireTemperature 0;
BA_ "GenSigInvalidValue" SG_ 1316 LHRTireTemperature 255;
BA_ "GenSigSendType" SG_ 1316 LHRTireTemperature 0;
BA_ "GenSigInvalidValue" SG_ 1316 LHFTirePressure 255;
BA_ "GenSigSendType" SG_ 1316 LHFTirePressure 0;
BA_ "GenSigInvalidValue" SG_ 1316 RHFTirePressure 255;
BA_ "GenSigSendType" SG_ 1316 RHFTirePressure 0;
BA_ "GenSigInvalidValue" SG_ 1316 LHRTirePressure 255;
BA_ "GenSigSendType" SG_ 1316 LHRTirePressure 0;
BA_ "GenSigInvalidValue" SG_ 1316 RHRTirePressure 255;
BA_ "GenSigSendType" SG_ 1316 RHRTirePressure 0;
BA_ "GenSigInvalidValue" SG_ 1316 RHRTireTemperature 255;
BA_ "GenSigSendType" SG_ 1316 RHRTireTemperature 0;
BA_ "GenSigSendType" SG_ 1318 ICC_SET_TDL_Rhythm_Switch 2;
BA_ "GenSigSendType" SG_ 1318 ICC_SET_TDL_Switch 2;
BA_ "GenSigSendType" SG_ 1318 ICC_SET_TDL_ColourModeAdj 2;
BA_ "GenSigSendType" SG_ 1318 ICC_TDL_RhythmReq 2;
BA_ "GenSigSendType" SG_ 1318 ICC_VoiceWake 2;
BA_ "GenSigSendType" SG_ 1318 ICC_TDLAssociatedDriverModeSw 2;
BA_ "GenSigSendType" SG_ 1318 ICC_SET_ApiluminanceAdj 2;
BA_ "GenSigStartValue" SG_ 1318 ICC_SET_MusicLoudness_120HZ 15;
BA_ "GenSigSendType" SG_ 1318 ICC_SET_MusicLoudness_120HZ 0;
BA_ "GenSigStartValue" SG_ 1318 ICC_SET_MusicLoudness_250HZ 15;
BA_ "GenSigSendType" SG_ 1318 ICC_SET_MusicLoudness_250HZ 0;
BA_ "GenSigStartValue" SG_ 1318 ICC_SET_MusicLoudness_500HZ 15;
BA_ "GenSigSendType" SG_ 1318 ICC_SET_MusicLoudness_500HZ 0;
BA_ "GenSigStartValue" SG_ 1318 ICC_SET_MusicLoudness_1000HZ 15;
BA_ "GenSigSendType" SG_ 1318 ICC_SET_MusicLoudness_1000HZ 0;
BA_ "GenSigStartValue" SG_ 1318 ICC_SET_MusicLoudness_1500HZ 15;
BA_ "GenSigSendType" SG_ 1318 ICC_SET_MusicLoudness_1500HZ 0;
BA_ "GenSigStartValue" SG_ 1318 ICC_SET_MusicLoudness_2000HZ 15;
BA_ "GenSigSendType" SG_ 1318 ICC_SET_MusicLoudness_2000HZ 0;
BA_ "GenSigStartValue" SG_ 1318 ICC_SET_MusicLoudness_6000HZ 15;
BA_ "GenSigSendType" SG_ 1318 ICC_SET_MusicLoudness_6000HZ 0;
BA_ "GenSigInvalidValue" SG_ 1318 ICC_SET_256ColourAdj 511;
BA_ "GenSigStartValue" SG_ 1318 ICC_SET_256ColourAdj 511;
BA_ "GenSigSendType" SG_ 1318 ICC_SET_256ColourAdj 2;
BA_ "GenSigSendType" SG_ 1318 ICC_TDL_FlowLightSw 2;
BA_ "GenSigSendType" SG_ 1318 ICC_TDL_FlowLightModeAdj 2;
BA_ "GenSigSendType" SG_ 1320 ICC_Chb_Req 2;
BA_ "GenSigSendType" SG_ 1320 ICC_ChbMem_Req 2;
BA_ "GenSigSendType" SG_ 1320 ICC_ChbDelay_Req 2;
BA_ "GenSigSendType" SG_ 1320 ICC_ChbSterilization_Req 2;
BA_ "GenSigSendType" SG_ 1320 ICC_ChbItemsLeft_Req 2;
BA_ "GenSigSendType" SG_ 1320 ICC_ParkingRadarSwSet 2;
BA_ "GenSigInvalidValue" SG_ 1320 ICC_ChbTimeset_Req 31;
BA_ "GenSigSendType" SG_ 1320 ICC_ChbTimeset_Req 2;
BA_ "GenSigSendType" SG_ 1320 ICC_ChbCoolset_Req 2;
BA_ "GenSigSendType" SG_ 1320 ICC_ChbCoolorheat_Req 2;
BA_ "GenSigSendType" SG_ 1320 ICC_ChbHeatset_Req 2;
BA_ "GenSigSendType" SG_ 1322 STAT_AMPAlarm 1;
BA_ "GenSigSendType" SG_ 1324 TirePositionWarning_LHFTire 0;
BA_ "GenSigSendType" SG_ 1324 TirePositionWarning_RHFTire 0;
BA_ "GenSigSendType" SG_ 1324 TirePositionWarning_LHRTire 0;
BA_ "GenSigSendType" SG_ 1324 TirePositionWarning_RHRTire 0;
BA_ "ASIL" SG_ 1324 TirePressureWarningLampSts 2;
BA_ "GenSigSendType" SG_ 1324 TirePressureWarningLampSts 0;
BA_ "ASIL" SG_ 1324 TirePressureSystemFailSts 2;
BA_ "GenSigSendType" SG_ 1324 TirePressureSystemFailSts 0;
BA_ "GenSigSendType" SG_ 1326 ICC_DWDOnOff_Req 2;
BA_ "GenSigSendType" SG_ 1326 ICC_ContainerLightSet 2;
BA_ "GenSigSendType" SG_ 1328 RADAR_1_RadarDetectSts 0;
BA_ "GenSigSendType" SG_ 1328 RADAR_1_RadarWorkSts 0;
BA_ "GenSigSendType" SG_ 1328 RADAR_1_Resd1 0;
BA_ "GenSigStartValue" SG_ 1328 RADAR_1_RHMRRadarSensorDistance 62;
BA_ "GenSigSendType" SG_ 1328 RADAR_1_RHMRRadarSensorDistance 0;
BA_ "GenSigStartValue" SG_ 1328 RADAR_1_LHRRadarSensorDistance 62;
BA_ "GenSigSendType" SG_ 1328 RADAR_1_LHRRadarSensorDistance 0;
BA_ "GenSigStartValue" SG_ 1328 RADAR_1_LHMRRadarSensorDistance 62;
BA_ "GenSigSendType" SG_ 1328 RADAR_1_LHMRRadarSensorDistance 0;
BA_ "GenSigStartValue" SG_ 1328 RADAR_1_RHRRadarSensorDistance 62;
BA_ "GenSigSendType" SG_ 1328 RADAR_1_RHRRadarSensorDistance 0;
BA_ "GenSigStartValue" SG_ 1328 RADAR_1_RHFRadarSensorDistance 30;
BA_ "GenSigSendType" SG_ 1328 RADAR_1_RHFRadarSensorDistance 0;
BA_ "GenSigStartValue" SG_ 1328 RADAR_1_LHFRadarSensorDistance 30;
BA_ "GenSigSendType" SG_ 1328 RADAR_1_LHFRadarSensorDistance 0;
BA_ "GenSigStartValue" SG_ 1328 RADAR_1_RHMFRadarSensorDistance 30;
BA_ "GenSigSendType" SG_ 1328 RADAR_1_RHMFRadarSensorDistance 0;
BA_ "GenSigSendType" SG_ 1328 RADAR_1_ParkingRadarSwSts 0;
BA_ "GenSigSendType" SG_ 1328 RADAR_1_AudibleBeepRate 0;
BA_ "GenSigStartValue" SG_ 1328 RADAR_1_LHMFRadarSensorDistance 30;
BA_ "GenSigSendType" SG_ 1328 RADAR_1_LHMFRadarSensorDistance 0;
BA_ "GenSigSendType" SG_ 1330 DWD_TextDisp 0;
BA_ "GenSigSendType" SG_ 1330 DWD_SoundIndcn 0;
BA_ "GenSigSendType" SG_ 1330 LSensorFailSts 0;
BA_ "GenSigSendType" SG_ 1330 RSensorFailSts 0;
BA_ "GenSigSendType" SG_ 1330 DWD_Distance 0;
BA_ "GenSigSendType" SG_ 1330 DWD_Switch 0;
BA_ "GenSigSendType" SG_ 1330 DWD_DistanceL 0;
BA_ "GenSigSendType" SG_ 1330 DWD_DistanceR 0;
BA_ "GenSigSendType" SG_ 1331 Set_AMPSoundEffectSupTreble 2;
BA_ "GenSigSendType" SG_ 1331 ICC_RLSeatEasyEntryExitSet 2;
BA_ "GenSigSendType" SG_ 1331 ICC_RRSeatEasyEntryExitSet 2;
BA_ "GenSigSendType" SG_ 1331 ICC_RLMemoryRecoveryCmd 2;
BA_ "GenSigSendType" SG_ 1331 ICC_RRMemoryRecoveryCmd 2;
BA_ "GenSigSendType" SG_ 1331 ICC_RLSitPosnlocation 2;
BA_ "GenSigSendType" SG_ 1331 ICC_RRSitPosnlocation 2;
BA_ "GenSigSendType" SG_ 1331 ICC_CMSMDisplaySwitch 2;
BA_ "GenSigSendType" SG_ 1331 ICC_CMSMDisplayAdjustmode 2;
BA_ "GenSigSendType" SG_ 1331 ICC_CMSMSetstandardSwitch 2;
BA_ "GenSigStartValue" SG_ 1331 ICC_LeftPedalControl 3;
BA_ "GenSigSendType" SG_ 1331 ICC_LeftPedalControl 2;
BA_ "GenSigStartValue" SG_ 1331 ICC_RightPedalControl 3;
BA_ "GenSigSendType" SG_ 1331 ICC_RightPedalControl 2;
BA_ "GenSigSendType" SG_ 1331 ICC_EPCEnable 2;
BA_ "GenSigSendType" SG_ 1331 ICC_AMPKTVvoiceVolumeSet 2;
BA_ "GenSigSendType" SG_ 1331 ICC_AMPA2BENCSoundReq 2;
BA_ "GenSigSendType" SG_ 1331 ICC_AMPENCVolumeSet 2;
BA_ "GenSigSendType" SG_ 1331 ICC_AMPA2BChimeSoundReq 2;
BA_ "GenSigSendType" SG_ 1331 ICC_AMPA2BKTVvoiceSoundReq 2;
BA_ "GenSigSendType" SG_ 1331 Set_AMPSoundFocus_2 2;
BA_ "GenSigSendType" SG_ 1331 ICC_MedStatusSet 2;
BA_ "GenSigSendType" SG_ 1331 Set_AMPLoudness 2;
BA_ "GenSigSendType" SG_ 1331 ICC_MedAreaSet 2;
BA_ "GenSigSendType" SG_ 1331 ICC_LeftElectricPedalsSet 2;
BA_ "GenSigSendType" SG_ 1331 ICC_RightElectricPedalsSet 2;
BA_ "GenSigSendType" SG_ 1331 ICC_NapAreaSet2 2;
BA_ "GenSigInvalidValue" SG_ 1331 ICC_DisplayAdjustrAngReq 255;
BA_ "GenSigSendType" SG_ 1331 ICC_DisplayAdjustrAngReq 2;
BA_ "GenSigSendType" SG_ 1331 Set_AMPExSoundmode 2;
BA_ "GenSigSendType" SG_ 1331 Set_AMPKeyVolume 2;
BA_ "GenSigSendType" SG_ 1331 ICC_CMSMTouchSts 2;
BA_ "GenSigSendType" SG_ 1331 Set_AMPA2BENCSound 2;
BA_ "GenSigSendType" SG_ 1333 ICC_SRFCmd 2;
BA_ "GenSigSendType" SG_ 1333 ICC_SRFPercentCmd 2;
BA_ "GenSigSendType" SG_ 1333 ICC_SunshadeCmd 2;
BA_ "GenSigSendType" SG_ 1333 ICC_SunshadePercentCmd 2;
BA_ "GenSigSendType" SG_ 1333 ICC_CSunshadeReq 2;
BA_ "GenSigSendType" SG_ 1333 ICC_CSunshadePercentReq 2;
BA_ "GenSigSendType" SG_ 1333 CSunshadeLearnedReq_535h 2;
BA_ "GenSigSendType" SG_ 1333 CSunshadePercentReq_535h 2;
BA_ "GenSigSendType" SG_ 1335 ICC_SET_EPS_SteerReturnRmdSts 2;
BA_ "GenSigSendType" SG_ 1335 ICC_SET_MFSShake 2;
BA_ "GenSigSendType" SG_ 1335 ICC_DMS_1_DistractionLevel 2;
BA_ "GenSigSendType" SG_ 1335 ICC_SET_EPS_AsociWithDrvModSts 2;
BA_ "GenSigSendType" SG_ 1335 ICC_OverLoadWarnShieldSet 2;
BA_ "GenSigSendType" SG_ 1335 ICC_BSWReq 2;
BA_ "GenSigSendType" SG_ 1335 ICC_horizontalReq 2;
BA_ "ASIL" SG_ 1335 ICC_RolloverSetCmd 1;
BA_ "GenSigSendType" SG_ 1335 ICC_RolloverSetCmd 2;
BA_ "GenSigSendType" SG_ 1335 ICC_TrekThroughReq_537h 2;
BA_ "GenSigSendType" SG_ 1335 ICC_InflateReq_537h 2;
BA_ "GenSigSendType" SG_ 1335 ICC_UndergroundModeReq_537h 2;
BA_ "GenSigSendType" SG_ 1335 ICC_SandABSSw_537h 2;
BA_ "GenSigSendType" SG_ 1335 ICC_SandABSCmd_537h 2;
BA_ "GenSigSendType" SG_ 1335 ICC_EPBAUTOCmd_537h 2;
BA_ "GenSigSendType" SG_ 1335 ICC_SpeParkSet_537h 2;
BA_ "GenSigSendType" SG_ 1337 ICC_SET_BT_ReduceWindSpeed 2;
BA_ "GenSigSendType" SG_ 1337 ICC_SET_IPM_FirstBlowing 2;
BA_ "GenSigSendType" SG_ 1337 ICC_SET_IPM_BlowerDelay 2;
BA_ "GenSigSendType" SG_ 1337 ICC_SET_CirculationInTunnels 2;
BA_ "GenSigSendType" SG_ 1337 ICC_UVCLuminanceReq 2;
BA_ "GenSigSendType" SG_ 1337 ICC_UVCControlReq 2;
BA_ "GenSigSendType" SG_ 1337 ICC_CrossCountryCoolingReq 2;
BA_ "GenSigSendType" SG_ 1337 ICC_KeepWarmReq 2;
BA_ "GenSigSendType" SG_ 1337 ICC_keepwarmSetTemperatureReq 2;
BA_ "GenSigSendType" SG_ 1337 ICC_ParkingAirConditioning 2;
BA_ "GenSigSendType" SG_ 1337 ICC_CoolantFill_Req 2;
BA_ "GenSigSendType" SG_ 1337 ICC_FraganceLightoffReq 2;
BA_ "GenSigSendType" SG_ 1337 ICC_FraganceMemoffReq 2;
BA_ "GenSigSendType" SG_ 1337 ICC_TimingLevel 2;
BA_ "GenSigSendType" SG_ 1337 ICC_CFSCycleLevel 2;
BA_ "GenSigSendType" SG_ 1337 ICC_AirPurgeReminderReq 2;
BA_ "GenSigSendType" SG_ 1337 ICC_TimedVentilationReq 2;
BA_ "GenSigSendType" SG_ 1337 ICC_BiochemicalFuncReq 2;
BA_ "GenSigStartValue" SG_ 1337 ICC_ModeAdjustDisplaySts 5;
BA_ "GenSigSendType" SG_ 1337 ICC_ModeAdjustDisplaySts 2;
BA_ "GenSigInvalidValue" SG_ 1337 ICC_PetModeSetTemperature_R_C 31;
BA_ "GenSigStartValue" SG_ 1337 ICC_PetModeSetTemperature_R_C 31;
BA_ "GenSigSendType" SG_ 1337 ICC_PetModeSetTemperature_R_C 2;
BA_ "GenSigInvalidValue" SG_ 1337 ICC_PetmodeSetTemperature_L_C 31;
BA_ "GenSigStartValue" SG_ 1337 ICC_PetmodeSetTemperature_L_C 31;
BA_ "GenSigSendType" SG_ 1337 ICC_PetmodeSetTemperature_L_C 2;
BA_ "GenSigSendType" SG_ 1337 ICC_PetModeSetCirculationSts 2;
BA_ "GenSigSendType" SG_ 1337 ICC_PetModeSetAutoKeySts 2;
BA_ "GenSigSendType" SG_ 1337 ICC_PetModeSetCLMOn 2;
BA_ "GenSigSendType" SG_ 1337 ICC_ISSFctCmd_539h 2;
BA_ "GenSigSendType" SG_ 1338 FMCU_ErrLvlDis 0;
BA_ "GenSigInvalidValue" SG_ 1338 FMCU_SpdAct_EDR 65535;
BA_ "GenSigStartValue" SG_ 1338 FMCU_SpdAct_EDR 32767;
BA_ "GenSigSendType" SG_ 1338 FMCU_SpdAct_EDR 0;
BA_ "GenSigInvalidValue" SG_ 1341 BMS_44_PackPowerRealTime 16383;
BA_ "GenSigStartValue" SG_ 1341 BMS_44_PackPowerRealTime 10240;
BA_ "GenSigSendType" SG_ 1341 BMS_44_PackPowerRealTime 0;
BA_ "GenSigSendType" SG_ 1345 DVR_1_DVRFailReasons 2;
BA_ "GenSigSendType" SG_ 1345 DVR_1_RecordSts 2;
BA_ "GenSigSendType" SG_ 1345 DVR_1_Sdcard_Sts 2;
BA_ "GenSigSendType" SG_ 1349 SBOX_MSD_Res 2;
BA_ "GenSigSendType" SG_ 1349 SBOX_Ecallphonenub_Res 2;
BA_ "GenSigSendType" SG_ 1351 SBOX_SetMsgTotal 1;
BA_ "GenSigSendType" SG_ 1351 SBOX_SetMSDTotal 1;
BA_ "GenSigSendType" SG_ 1351 SBOX_SetCallTimeThreshold 1;
BA_ "GenSigSendType" SG_ 1351 SBOX_SetTodayCallTimeThreshold 1;
BA_ "GenSigSendType" SG_ 1351 SBOX_SetCurretnCallTime 1;
BA_ "GenSigSendType" SG_ 1351 SBOX_SetCurretnMsgThreshold 1;
BA_ "GenSigSendType" SG_ 1351 SBOX_SetMsgTotalThreshold 1;
BA_ "GenSigSendType" SG_ 1351 SBOX_SetMsdThreshold 1;
BA_ "GenSigSendType" SG_ 1351 SBOX_SetCurrenMsdCnt 1;
BA_ "GenSigSendType" SG_ 1351 SBOX_SetCustomMsgThreshold 1;
BA_ "GenSigSendType" SG_ 1351 SBOX_SetCurrentCustomMsgCnt 1;
BA_ "GenSigSendType" SG_ 1353 SBOX_ICC_MACReq 1;
BA_ "GenSigSendType" SG_ 1353 SBOX_MAC_Req0 1;
BA_ "GenSigSendType" SG_ 1353 SBOX_MAC_Req1 1;
BA_ "GenSigSendType" SG_ 1353 SBOX_MAC_Req2 1;
BA_ "GenSigSendType" SG_ 1353 SBOX_MAC_Req3 1;
BA_ "GenSigSendType" SG_ 1353 SBOX_MAC_Req4 1;
BA_ "GenSigSendType" SG_ 1353 SBOX_MAC_Req5 1;
BA_ "GenSigSendType" SG_ 1354 ICC_SetMsgTotal 1;
BA_ "GenSigSendType" SG_ 1354 ICC_SetMSDTotal 1;
BA_ "GenSigSendType" SG_ 1354 ICC_SetCallTimeThreshold 1;
BA_ "GenSigSendType" SG_ 1354 ICC_SetTodayCallTimeThreshold 1;
BA_ "GenSigSendType" SG_ 1354 ICC_SetCurretnCallTime 1;
BA_ "GenSigSendType" SG_ 1354 ICC_SetCurretnMsgThreshold 1;
BA_ "GenSigSendType" SG_ 1354 ICC_SetMsgTotalThreshold 1;
BA_ "GenSigSendType" SG_ 1354 ICC_SetMsdThreshold 1;
BA_ "GenSigSendType" SG_ 1354 ICC_SetCurrenMsdCnt 1;
BA_ "GenSigSendType" SG_ 1354 ICC_SetCustomMsgThreshold 1;
BA_ "GenSigSendType" SG_ 1354 ICC_SetCurrentCustomMsgCnt 1;
BA_ "GenSigSendType" SG_ 1356 ICC_flag 1;
BA_ "GenSigSendType" SG_ 1356 ICC_ActiveTsp_Req 1;
BA_ "GenSigSendType" SG_ 1356 ICC_ActiveSim_Req 1;
BA_ "GenSigSendType" SG_ 1356 ICC_GetMac_req 1;
BA_ "GenSigSendType" SG_ 1356 ICC_GetIccid_Vin 1;
BA_ "GenSigSendType" SG_ 1356 ICC_Platform_Phonenub1 1;
BA_ "GenSigSendType" SG_ 1356 ICC_Platform_Phonenub2 1;
BA_ "GenSigSendType" SG_ 1356 ICC_Platform_Phonenub3 1;
BA_ "GenSigSendType" SG_ 1356 ICC_Platform_Phonenub4 1;
BA_ "GenSigSendType" SG_ 1356 ICC_Platform_Phonenub5 1;
BA_ "GenSigSendType" SG_ 1356 ICC_Platform_Phonenub6 1;
BA_ "GenSigSendType" SG_ 1356 ICC_Platform_Phonenub7 1;
BA_ "GenSigSendType" SG_ 1356 ICC_Platform_Phonenub8 1;
BA_ "GenSigSendType" SG_ 1356 ICC_Platform_Phonenub9 1;
BA_ "GenSigSendType" SG_ 1356 ICC_Platform_Phonenub10 1;
BA_ "GenSigSendType" SG_ 1356 ICC_Platform_Phonenub11 1;
BA_ "GenSigSendType" SG_ 1356 ICC_Platform_Phonenub12 1;
BA_ "GenSigSendType" SG_ 1356 ICC_Platform_Phonenub13 1;
BA_ "GenSigSendType" SG_ 1356 ICC_Platform_Phonenub14 1;
BA_ "GenSigSendType" SG_ 1356 ICC_Platform_Phonenub15 1;
BA_ "GenSigSendType" SG_ 1356 ICC_Platform_Phonenub16 1;
BA_ "GenSigSendType" SG_ 1356 ICC_Platform_Phonenub17 1;
BA_ "GenSigSendType" SG_ 1356 ICC_Platform_Phonenub18 1;
BA_ "GenSigSendType" SG_ 1356 ICC_Platform_Phonenub19 1;
BA_ "GenSigSendType" SG_ 1356 ICC_Platform_Phonenub20 1;
BA_ "GenSigSendType" SG_ 1356 ICC_Mac0 1;
BA_ "GenSigSendType" SG_ 1356 ICC_Mac1 1;
BA_ "GenSigSendType" SG_ 1356 ICC_Mac2 1;
BA_ "GenSigSendType" SG_ 1356 ICC_Mac3 1;
BA_ "GenSigSendType" SG_ 1356 ICC_Mac4 1;
BA_ "GenSigSendType" SG_ 1356 ICC_Mac5 1;
BA_ "GenSigSendType" SG_ 1356 ICC_GivePlatformNumber_Flag 1;
BA_ "GenSigSendType" SG_ 1356 ICC_Mac_Flag 1;
BA_ "GenSigSendType" SG_ 1358 SBOX_ActiveTsp_Res 1;
BA_ "GenSigSendType" SG_ 1358 SBOX_ActiveSim_Res 1;
BA_ "GenSigSendType" SG_ 1358 SBOX_GetPlatformNumberRes 1;
BA_ "GenSigSendType" SG_ 1358 SBOX_Mac_Res0 1;
BA_ "GenSigSendType" SG_ 1358 SBOX_Mac_Res1 1;
BA_ "GenSigSendType" SG_ 1358 SBOX_Mac_Res2 1;
BA_ "GenSigSendType" SG_ 1358 SBOX_Mac_Res3 1;
BA_ "GenSigSendType" SG_ 1358 SBOX_Mac_Res4 1;
BA_ "GenSigSendType" SG_ 1358 SBOX_Mac_Res5 1;
BA_ "GenSigSendType" SG_ 1358 SBOX_ICCId_Res0 1;
BA_ "GenSigSendType" SG_ 1358 SBOX_ICCId_Res1 1;
BA_ "GenSigSendType" SG_ 1358 SBOX_ICCId_Res2 1;
BA_ "GenSigSendType" SG_ 1358 SBOX_ICCId_Res3 1;
BA_ "GenSigSendType" SG_ 1358 SBOX_ICCId_Res4 1;
BA_ "GenSigSendType" SG_ 1358 SBOX_ICCId_Res5 1;
BA_ "GenSigSendType" SG_ 1358 SBOX_ICCId_Res6 1;
BA_ "GenSigSendType" SG_ 1358 SBOX_ICCId_Res7 1;
BA_ "GenSigSendType" SG_ 1358 SBOX_ICCId_Res8 1;
BA_ "GenSigSendType" SG_ 1358 SBOX_ICCId_Res9 1;
BA_ "GenSigSendType" SG_ 1358 SBOX_ICCId_Res10 1;
BA_ "GenSigSendType" SG_ 1358 SBOX_ICCId_Res11 1;
BA_ "GenSigSendType" SG_ 1358 SBOX_ICCId_Res12 1;
BA_ "GenSigSendType" SG_ 1358 SBOX_ICCId_Res13 1;
BA_ "GenSigSendType" SG_ 1358 SBOX_ICCId_Res14 1;
BA_ "GenSigSendType" SG_ 1358 SBOX_ICCId_Res15 1;
BA_ "GenSigSendType" SG_ 1358 SBOX_ICCId_Res16 1;
BA_ "GenSigSendType" SG_ 1358 SBOX_ICCId_Res17 1;
BA_ "GenSigSendType" SG_ 1358 SBOX_ICCId_Res18 1;
BA_ "GenSigSendType" SG_ 1358 SBOX_ICCId_Res19 1;
BA_ "GenSigSendType" SG_ 1358 SBOX_Vin0 1;
BA_ "GenSigSendType" SG_ 1358 SBOX_Vin1 1;
BA_ "GenSigSendType" SG_ 1358 SBOX_Vin2 1;
BA_ "GenSigSendType" SG_ 1358 SBOX_Vin3 1;
BA_ "GenSigSendType" SG_ 1358 SBOX_Vin4 1;
BA_ "GenSigSendType" SG_ 1358 SBOX_Vin5 1;
BA_ "GenSigSendType" SG_ 1358 SBOX_Vin6 1;
BA_ "GenSigSendType" SG_ 1358 SBOX_Vin7 1;
BA_ "GenSigSendType" SG_ 1358 SBOX_Vin8 1;
BA_ "GenSigSendType" SG_ 1358 SBOX_Vin9 1;
BA_ "GenSigSendType" SG_ 1358 SBOX_Vin10 1;
BA_ "GenSigSendType" SG_ 1358 SBOX_Vin11 1;
BA_ "GenSigSendType" SG_ 1358 SBOX_Vin12 1;
BA_ "GenSigSendType" SG_ 1358 SBOX_Vin13 1;
BA_ "GenSigSendType" SG_ 1358 SBOX_Vin14 1;
BA_ "GenSigSendType" SG_ 1358 SBOX_Vin15 1;
BA_ "GenSigSendType" SG_ 1358 SBOX_Vin16 1;
BA_ "GenSigSendType" SG_ 1360 ICC_LISD_DisplaySwitch 2;
BA_ "GenSigSendType" SG_ 1360 ICC_LISD_ParkingShowCMD 2;
BA_ "GenSigSendType" SG_ 1360 ICC_RISD_DisplaySwitch 2;
BA_ "GenSigSendType" SG_ 1360 ICC_RISD_ParkingShowCMD 2;
BA_ "GenSigSendType" SG_ 1360 ICC_LogoParkingReq 2;
BA_ "GenSigSendType" SG_ 1360 ICC_LogoChargingReq 2;
BA_ "GenSigSendType" SG_ 1360 ICC_DRLSw 2;
BA_ "GenSigSendType" SG_ 1360 ICC_LISD_ParkingShowMod 2;
BA_ "GenSigSendType" SG_ 1360 ICC_RISD_ParkingShowMod 2;
BA_ "GenSigSendType" SG_ 1360 ICC_LogoColorReq 2;
BA_ "GenSigSendType" SG_ 1360 ICC_MusicLampShowSW 2;
BA_ "GenSigSendType" SG_ 1360 ICC_PenetrationLampSetF 2;
BA_ "GenSigSendType" SG_ 1360 ICC_XDriveMode 0;
BA_ "GenSigSendType" SG_ 1360 ICC_DowWaringSw 2;
BA_ "GenSigSendType" SG_ 1360 ICC_CarSearhSetSwitchSts 2;
BA_ "GenSigSendType" SG_ 1360 ICC_TDL_NightBright_SW_550h 2;
BA_ "GenSigInvalidValue" SG_ 1361 EPC_LeftPedalSystem_Sts 15;
BA_ "GenSigSendType" SG_ 1361 EPC_LeftPedalSystem_Sts 0;
BA_ "GenSigInvalidValue" SG_ 1361 EPC_RightPedalSystem_Sts 15;
BA_ "GenSigSendType" SG_ 1361 EPC_RightPedalSystem_Sts 0;
BA_ "GenSigSendType" SG_ 1361 EPC_LeftPedalTimeTravel 0;
BA_ "GenSigSendType" SG_ 1361 EPC_RightPedalTimeTravel 0;
BA_ "GenSigSendType" SG_ 1361 EPC_RightPedalRealTime_Sts 0;
BA_ "GenSigSendType" SG_ 1361 EPC_LeftPedalBreakIce_Sts 0;
BA_ "GenSigSendType" SG_ 1361 EPC_LeftPedalRealTime_Sts 0;
BA_ "GenSigStartValue" SG_ 1361 EPC_RightPedalCmdStatus 3;
BA_ "GenSigSendType" SG_ 1361 EPC_RightPedalCmdStatus 0;
BA_ "GenSigStartValue" SG_ 1361 EPC_LeftPedalCmdStatus 3;
BA_ "GenSigSendType" SG_ 1361 EPC_LeftPedalCmdStatus 0;
BA_ "GenSigInvalidValue" SG_ 1361 EPC_Enable_CmdStatus 3;
BA_ "GenSigSendType" SG_ 1361 EPC_Enable_CmdStatus 0;
BA_ "GenSigSendType" SG_ 1361 EPC_RightPedalBreakIce_Sts 0;
BA_ "GenSigSendType" SG_ 1361 EPC_RightPedal3D_Sts 0;
BA_ "GenSigSendType" SG_ 1361 EPC_LeftPedal3D_Sts 0;
VAL_ 1265 ICC_PwrOff 0 "No active" 1 "Active" ;
VAL_ 1265 ICC_EtmEgySave 0 "OFF" 1 "ON" ;
VAL_ 1265 ICC_HoodSW 0 "Not Active" 1 "ON" 2 "Reserved" 3 "Reserved" ;
VAL_ 1265 ICC_GloveboxSW 0 "Not Active" 1 "ON" 2 "Reserved" 3 "Reserved" ;
VAL_ 1265 ICC_ChrgPortCover_Switch 0 "Not Active" 1 "ON" 2 "OFF" 3 "Reserved" ;
VAL_ 1265 ICC_ReWinDefrstSwt 0 "Not Active" 1 "ON" 2 "OFF" 3 "Reserved" ;
VAL_ 1265 ICC_RearMirrorFoldCmd 0 "Not Active" 1 "Fold" 2 "Unfold" 3 "Reserved" ;
VAL_ 1265 ICC_CenterLockSwt 0 "Not Active" 1 "UNLOCK" 2 "LOCK" 3 "Reserved" ;
VAL_ 1265 ICC_ReverseExtMirrorSts 0 "Not active" 1 "OFF" 2 "Only right side" 3 "Only left side" 4 "Both sides" 5 "Not Used" 6 "Not Used" 7 "Not Used" ;
VAL_ 1265 ICC_LightMainSwitchSts 0 "Not active" 1 "Off" 2 "Auto" 3 "PositionLampSwitch" 4 "LowBeamSwitch" 5 "Reserved" 6 "Reserved" 7 "Reserved" ;
VAL_ 1265 ICC_AutoFoldSts 0 "Not active" 1 "Autofold mode" 2 "Not autofold mode" 3 "Not used" ;
VAL_ 1265 ICC_HeadlampHeightSts 0 "Not active" 1 "Level 0" 2 "Level 1" 3 "Level 2" 4 "Level 3" 5 "Not Used" 6 "Not Used" 7 "Not Used" ;
VAL_ 1265 ICC_WiprSnvty 0 "Not Active" 1 "Level1" 2 "Level2" 3 "Level3" 4 "Level4" 5 "Reserved" 6 "Reserved" ;
VAL_ 1265 ICC_WindowCmd 0 "Not active" 1 "DrvWindow open" 2 "DrvWindow close" 3 "PassWindow open" 4 "PassWindow close" 5 "DrvRearWindow open" 6 "DrvRearWindow close" 7 "PassRearWindow open" 8 "PassRearWindow close" 9 "Front Windows open" 10 "Front Windows close" 11 "Rear Windows open" 12 "Rear Windows close" 13 "All Windows open" 14 "All  Windows close" 15 "All  Windows comfort" 16 "Not used" 17 "Not used" 18 "Not used" 19 "Not used" 20 "Not used" 21 "Not used" 22 "Not used" 23 "Not used" 24 "Not used" 25 "Not used" 26 "Not used" 27 "Not used" 28 "Not used" 29 "Not used" 30 "Not used" 31 "Not used" ;
VAL_ 1265 ICC_LowBeamDelayOff 0 "Not Active" 1 "0s" 2 "10s" 3 "20s" 4 "30s" 5 "60s" 6 "Not Used" 7 "Not Used" ;
VAL_ 1265 ICC_FGHeatSts 0 "Not Active" 1 "ON" 2 "OFF" 3 "Reserved" ;
VAL_ 1265 ICC_AutolockSts 0 "Not active" 1 "Autolock mode" 2 "Not autolock mode" 3 "Not Used" ;
VAL_ 1265 ICC_WiperID 0 "Not Active" 1 "Front Wiper" 2 "Rear Wiper" 3 "Both Wiper" ;
VAL_ 1265 ICC_MaintenanceMode 0 "Not Active" 1 "Exit" 2 "Entrance" 3 "Reserved" ;
VAL_ 1265 ICC_lockSetSwitchSts 0 "Not Active" 1 "OFF" 2 "Only Lighting" 3 "Sound and Lighting" ;
VAL_ 1265 ICC_ChildLockSW 0 "Not Active" 1 "Window" 2 "ChildLock_DrvRear" 3 "ChildLock_PassRear" ;
VAL_ 1265 ICC_ParkUnlockEnable 0 "Not Active" 1 "Disable" 2 "Enable" 3 "Reserved" ;
VAL_ 1265 ICC_BLEOpenDriverDoorEnable 0 "No Request" 1 "Enable" 2 "Disable" 3 "Reserved" ;
VAL_ 1265 ICC_WinInhbSwt 0 "Not Active" 1 "Inhibit" 2 "Permit" 3 "Reserved" ;
VAL_ 1265 ICC_SteerWhlHeatgSwt 0 "Not Active" 1 "Level1" 2 "Level2" 3 "Level3" 4 "OFF" ;
VAL_ 1265 ICC_AutoHeatingset 0 "Not Active" 1 "ON" 2 "OFF" 3 "Reserved" ;
VAL_ 1265 ICC_FrontFogSw 0 "Not Active" 1 "ON" 2 "OFF" 3 "Reserved" ;
VAL_ 1265 ICC_RearFogSw 0 "Not Active" 1 "ON" 2 "OFF" 3 "Reserved" ;
VAL_ 1265 ICC_DoorControlSW 0 "Not Active" 1 "ON" 2 "OFF" 3 "Reserved" ;
VAL_ 1265 ICC_LockCarWinCloseSw 0 "Not Active" 1 "ON" 2 "OFF" 3 "Reserved" ;
VAL_ 1265 ICC_NapStatusSet 0 "Not Active" 1 "ON" 2 "OFF" 3 "Not Used" ;
VAL_ 1265 ICC_NapAreaSet 0 "Not Active" 1 "Front Left" 2 "Front Right" 3 "Front Left and Right" ;
VAL_ 1265 ICC_EasyEntryExitSet 0 "Not Active" 1 "ON" 2 "OFF" 3 "Not Used" ;
VAL_ 1265 ICC_RainCarWinCloseSw 0 "Not Active" 1 "ON" 2 "OFF" 3 "Reserved" ;
VAL_ 1265 ICC_NapSetTemperature 31 "Not active" ;
VAL_ 1265 ICC_NapCFSStatusSet 0 "Not Active" 1 "On" 2 "Off" 3 "Not Used" ;
VAL_ 1265 ICC_HazardLightReq 0 "Not Active" 1 "ON" 2 "OFF" 3 "Not Used" ;
VAL_ 1265 ICC_SpoilerCtrlCmd 0 "Not Active" 1 "Auto" 2 "Open Level1" 3 "Open Level2" 4 "Close" 5 "Reserved" 6 "Reserved" 7 "Reserved" ;
VAL_ 1265 ICC_SpoilerWelcomeFunSet 0 "Not Active" 1 "ON" 2 "OFF" 3 "Reserved" ;
VAL_ 1265 ICC_CinemaStatus 0 "Not Active" 1 "ON" 2 "OFF" 3 "Not Used" ;
VAL_ 1265 ICC_MusicStatus 0 "Not Active" 1 "ON" 2 "OFF" 3 "Not Used" ;
VAL_ 1267 RRCR_1_SysSt 0 "Off" 1 "On" 2 "Temporary Error" 3 "System Error" ;
VAL_ 1267 RRCR_1_BlkSts 0 "Not Blockage" 1 "Blockage" ;
VAL_ 1267 RRCR_1_BSDWarn 0 "No Warning" 1 "Standard Warning" 2 "Critical Warning" 3 "Not Used" ;
VAL_ 1267 RRCR_1_DOWWarn 0 "No Warning" 1 "Level1 Warning" 2 "Level2 Warning" 3 "Not Used" ;
VAL_ 1267 RRCR_1_DowLock 0 "No Warning" 1 "Dow lock" 2 "Dow unlock" 3 "Not Used" ;
VAL_ 1267 RRCR_1_ELK_Collision_flag 0 "No critical situation of collision" 1 "Critical situation of collision" ;
VAL_ 1267 RRCR_1_ELK_CollisionFlagValid 0 "Not valid" 1 "Valid" ;
VAL_ 1269 LISDShowCMDSts 0 "OFF" 1 "ON" ;
VAL_ 1269 LISDShowModeSts 0 "Default value" 1 "BatteryCharging" 2 "Brand" 3 "TiresPressures" 4 "Weather" 5 "Greetings" 6 "Package" 7 "Panda" 8 "PredestrianCrossing" 9 "PingPong" 10 "Kite" 11 "Coffee" 12 "Reserved" 13 "Reserved" 14 "Reserved" 15 "Reserved" ;
VAL_ 1269 LISDTransmitStatus 0 "Default value" 1 "Success" 2 "Fail" 3 "Idle" ;
VAL_ 1269 LISDDisplayStatus 0 "Not Active" 1 "ON" 2 "OFF" 3 "Reserved" ;
VAL_ 1269 LISD_ParkingShowModSts 0 "Default value" 1 "Mode1" 2 "Mode2" 3 "Mode3" 4 "Mode4" 5 "Reserved" 6 "Reserved" 7 "Reserved" 8 "Reserved" 9 "Reserved" 10 "Reserved" 11 "Reserved" 12 "Reserved" 13 "Reserved" 14 "Reserved" 15 "Reserved" ;
VAL_ 1269 LISD_ParkingShowCMDSts 0 "Not Active" 1 "ON" 2 "OFF" 3 "Reserved" ;
VAL_ 1271 RRCR_2_RCWWarn 0 "No Warning" 1 "Level1 Warning" 2 "Level2 Warning" 3 "Not Used" ;
VAL_ 1271 RRCR_2_RCTAWarn 0 "No Warning" 1 "Warning" ;
VAL_ 1271 RRCR_2_BSDLCWONOFFSts 0 "Not active" 1 "OFF" 2 "ON" 3 "Reserved" ;
VAL_ 1271 RRCR_2_DOWONOFFSts 0 "Not active" 1 "OFF" 2 "ON" 3 "Reserved" ;
VAL_ 1271 RRCR_2_RCWONOFFSts 0 "Not active" 1 "OFF" 2 "ON" 3 "Reserved" ;
VAL_ 1271 RRCR_2_RCTARCTBONOFFSts 0 "OFF" 1 "warning" 2 "Reserved" 3 "Reserved" ;
VAL_ 1273 FaceID 0 "Not active" 1 "ID1" 2 "ID2" 3 "ID3" 4 "ID4" 5 "ID5" 6 "Exit" 7 "Not Used" ;
VAL_ 1273 DrvSeatExtMirPosRecallID_4F9h 0 "Not active" 1 "seat_ExtMirror_Pos1_Recall_ID1" 2 "seat_ExtMirror_Pos2_Recall_ID1" 3 "seat_ExtMirror_Pos3_Recall_ID1" 4 "seat_ExtMirror_Pos1_Recall_ID2" 5 "seat_ExtMirror_Pos2_Recall_ID2" 6 "seat_ExtMirror_Pos3_Recall_ID2" 7 "seat_ExtMirror_Pos1_Recall_ID3" 8 "seat_ExtMirror_Pos2_Recall_ID3" 9 "seat_ExtMirror_Pos3_Recall_ID3" 10 "seat_ExtMirror_Pos1_Recall_ID4" 11 "seat_ExtMirror_Pos2_Recall_ID4" 12 "seat_ExtMirror_Pos3_Recall_ID4" 13 "seat_ExtMirror_Pos1_Recall_ID5" 14 "seat_ExtMirror_Pos2_Recall_ID5" 15 "seat_ExtMirror_Pos3_Recall_ID5" 17 "seat_ExtMirror_Pos1_Recall_NOID" 18 "seat_ExtMirror_Pos2_Recall_NOID" 19 "seat_ExtMirror_Pos3_Recall_NOID" ;
VAL_ 1273 DrvSeatExtMirPosStoreReqID_4F9h 0 "Not active" 1 "seat_ExtMirror_Pos1_StoreReq_ID1" 2 "seat_ExtMirror_Pos2_StoreReq_ID1" 3 "seat_ExtMirror_Pos3_StoreReq_ID1" 4 "seat_ExtMirror_Pos1_StoreReq_ID2" 5 "seat_ExtMirror_Pos2_StoreReq_ID2" 6 "seat_ExtMirror_Pos3_StoreReq_ID2" 7 "seat_ExtMirror_Pos1_StoreReq_ID3" 8 "seat_ExtMirror_Pos2_StoreReq_ID3" 9 "seat_ExtMirror_Pos3_StoreReq_ID3" 10 "seat_ExtMirror_Pos1_StoreReq_ID4" 11 "seat_ExtMirror_Pos2_StoreReq_ID4" 12 "seat_ExtMirror_Pos3_StoreReq_ID4" 13 "seat_ExtMirror_Pos1_StoreReq_ID5" 14 "seat_ExtMirror_Pos2_StoreReq_ID5" 15 "seat_ExtMirror_Pos3_StoreReq_ID5" 17 "seat_ExtMirror_Pos1_StoreReq_NOID" 18 "seat_ExtMirror_Pos2_StoreReq_NOID" 19 "seat_ExtMirror_Pos3_StoreReq_NOID" ;
VAL_ 1276 PassSeatHeiAdjmt_Target 0 "Not active" 1 "0" 2 "10%" 3 "20%" 4 "30%" 5 "40%" 6 "50%" 7 "60%" 8 "70%" 9 "80%" 10 "90%" 11 "100%" ;
VAL_ 1276 SeatBackAndFwdAdjmt_Target 0 "Not active" 1 "0" 2 "10%" 3 "20%" 4 "30%" 5 "40%" 6 "50%" 7 "60%" 8 "70%" 9 "80%" 10 "90%" 11 "100%" ;
VAL_ 1276 SeatBackAgAdjmt_Target 0 "Not active" 1 "0" 2 "5%" 3 "10%" 4 "15%" 5 "20%" 6 "25%" 7 "30%" 8 "35%" 9 "40%" 10 "45%" 11 "50%" 12 "55%" 13 "60%" 14 "65%" 15 "70%" 16 "75%" 17 "80%" 18 "85%" 19 "90%" 20 "95%" 21 "100%" ;
VAL_ 1276 Set_ProfileID 0 "Not active" 1 "ID1" 2 "ID2" 3 "ID3" 4 "ID4" 5 "ID5" 6 "ID6" 7 "Ignore" ;
VAL_ 1276 SeatCushAgAdjmt_Target 0 "Not active" 1 "0" 2 "10%" 3 "20%" 4 "30%" 5 "40%" 6 "50%" 7 "60%" 8 "70%" 9 "80%" 10 "90%" 11 "100%" ;
VAL_ 1276 LgRstFwdAndBckAdjmt_Target 0 "Not active" 1 "0" 2 "10%" 3 "20%" 4 "30%" 5 "40%" 6 "50%" 7 "60%" 8 "70%" 9 "80%" 10 "90%" 11 "100%" ;
VAL_ 1276 FootRestAdjmt_Target 0 "Not active" 1 "0" 2 "10%" 3 "20%" 4 "30%" 5 "40%" 6 "50%" 7 "60%" 8 "70%" 9 "80%" 10 "90%" 11 "100%" ;
VAL_ 1276 REQ_SeatPosRecall 0 "No action" 1 "Recall seat_mode_1 of ID1" 2 "Recall seat_mode_2 of ID1" 3 "Recall seat_mode_3 of ID1" 4 "Recall seat_mode_1 of ID2" 5 "Recall seat_mode_2 of ID2" 6 "Recall seat_mode_3 of ID2" 7 "Recall seat_mode_1 of ID3" 8 "Recall seat_mode_2 of ID3" 9 "Recall seat_mode_3 of ID3" 10 "Recall seat_mode_1 of ID4" 11 "Recall seat_mode_2 of ID4" 12 "Recall seat_mode_3 of ID4" 13 "Recall seat_mode_1 of ID5" 14 "Recall seat_mode_2 of ID5" 15 "Recall seat_mode_3 of ID5" ;
VAL_ 1276 REQ_SeatPosStore 0 "No action" 1 "Store seat_mode_1 of ID1" 2 "Store seat_mode_2 of ID1" 3 "Store seat_mode_3 of ID1" 4 "Store seat_mode_1 of ID2" 5 "Store seat_mode_2 of ID2" 6 "Store seat_mode_3 of ID2" 7 "Store seat_mode_1 of ID3" 8 "Store seat_mode_2 of ID3" 9 "Store seat_mode_3 of ID3" 10 "Store seat_mode_1 of ID4" 11 "Store seat_mode_2 of ID4" 12 "Store seat_mode_3 of ID4" 13 "Store seat_mode_1 of ID5" 14 "Store seat_mode_2 of ID5" 15 "Store seat_mode_3 of ID5" ;
VAL_ 1276 Set_ToDefault 0 "No action" 1 "Set_Vehicle_to_default" 2 "Set_Personalization_to_default" 3 "Set_Telematics_to_default" 4 "Set_System_to_default" 5 "Set_All_to_default" 6 "Reserved" 7 "Ignore" ;
VAL_ 1276 Set_EasyEntryEnable 0 "No action" 1 "Enable" 2 "Disable" 3 "Ignore" ;
VAL_ 1276 REQ_SeatHeatPass 0 "Not Pressed" 1 "Seat heating level 1" 2 "Seat heating level 2" 3 "Seat heating level 3" ;
VAL_ 1276 REQ_SeatVentPass 0 "Not Pressed" 1 "Seat venting level 1" 2 "Seat venting level 2" 3 "Seat venting level 3" ;
VAL_ 1276 PassSeatMsgStr_LvlCmd 0 "NotActive" 1 "OFF" 2 "Low" 3 "Middle" 4 "High" ;
VAL_ 1276 PassSeatMsg_ModeCmd 0 "NotActive" 1 "PulseMode" 2 "WaveMode" 3 "CatPawMode" 4 "SigleRowMode" 5 "CrossMode" 6 "ButterflyMode" 7 "WaistMode" 8 "SnakeMode" 9 "Special 1" 10 "Special 2" 11 "Special 3" 12 "Special 4" ;
VAL_ 1279 ICC_SentinelModeSts 0 "invalid" 1 "OFF" 2 "ON" 3 "Reserved" ;
VAL_ 1279 Weather_Type 0 "Reserved" 1 "Sunny" 2 "Cloudy" 3 "Overcast" 4 "Shower" 5 "Thundershower" 6 "Thundershower with hail" 7 "Sleet" 8 "Light rain" 9 "Moderate rain" 10 "Heavy rain" 11 "Storm" 12 "Reserved(Heavy storm)" 13 "Reserved(Severe storm)" 14 "Reserved(Snow flurry)" 15 "Light snow" 16 "Moderate snow" 17 "Heavy snow" 18 "Snowstorm" 19 "Foggy" 20 "Reserved(Ice rain)" 21 "Duststorm" 22 "Reserved(Light to moderate rain)" 23 "Reserved(Moderate to heavy rain)" 24 "Reserved(Heavy rain to storm)" 25 "Reserved(Storm to heavy storm)" 26 "Reserved(Heavy to severe storm)" 27 "Reserved(Light to moderate snow)" 28 "Reserved(Moderate to heavy snow)" 29 "Reserve(Heavy snow to snowstorm)" 30 "Dust" 31 "Sand" 32 "Reserved(Sandstorm)" 33 "Haze" 34 "Reserved" 35 "Reserved" 36 "Reserved" 37 "Reserved" 38 "Reserved" 39 "Reserved" 40 "Reserved" 41 "Reserved" 42 "Reserved" 43 "Reserved" 44 "Reserved" 45 "Reserved" 46 "Reserved" 47 "Reserved" 48 "Reserved" 49 "Reserved" 50 "Reserved" 51 "Reserved" 52 "Reserved" 53 "Reserved" 54 "Reserved" 55 "Reserved" 56 "Reserved" 57 "Reserved" 58 "Reserved" 59 "Reserved" 60 "Reserved" 61 "Reserved" 62 "Reserved" 63 "Reserved" ;
VAL_ 1279 ICC_CameraErrorCode 0 "NoError" 1 "ErrorCode1" 2 "ErrorCode2" 3 "ErrorCode3" ;
VAL_ 1279 ICC_SentinelRequest 0 "Not Active" 1 "EnterSentinelRequest" 2 "ExitSentinelRequest" 3 "OFF" ;
VAL_ 1279 ICC_StartDeInitCameraStream 0 "Not Active" 1 "ICC_StartDeInitCameraStream" 2 "Reserved" 3 "Reserved" ;
VAL_ 1279 ICC_CameraRecoveryRequest 0 "Not Active" 1 "ICC_StartRecovery" 2 "Reserved" 3 "Reserved" ;
VAL_ 1279 ICC_CleanMode_4FFh 0 "Not Active" 1 "OFF" 2 "ON" ;
VAL_ 1289 ICC_ToggleUnits 0 "Not Active" 1 "Imperial" 2 "Metric" ;
VAL_ 1289 ICC_TireTemperatureDisplayUnit 0 "Not Active" 1 "°C" 2 "F" 3 "Reserved" ;
VAL_ 1289 ICC_TirePressureDisplayUnit 0 "Not Active" 1 "kPa" 2 "bar" 3 "psi" ;
VAL_ 1289 ICC_GPSSwitchSet 0 "Not Active" 1 "On" 2 "Off" 3 "Not Used" ;
VAL_ 1289 ICC_BtConFlag 0 "invalid" 1 "bluetooth not found" 2 "PIN error" 3 "other anomalies" 4 "bluetooth connection successful" ;
VAL_ 1289 ICC_LanguageSet_509h 0 "Not Active" 1 "Chinese" 2 "English" 3 "Russian" 4 "Arabic" 5 "Portuguese" 6 "Farsi" 7 "Spanish" 8 "Italian" 9 "Turkish" 10 "Ukrainian" 11 "Thai" 12 "Indonesian" 13 "German" 14 "French" 15 "Dutch" 16 "Norwegian" 17 "Swedish" 18 "Hebrew" 19 "Polish" 20 "Hun" 21 "Belgium" 22 "Czech" 23 "Greek" 24 "Uzbek" 25 "Kazakh" 26 "Danish" 27 "Romanian" 28 "Reserved" 29 "Reserved" 30 "Reserved" 31 "Reserved" 32 "Reserved" 33 "Slovak" 34 "Finnish" 35 "Croatian" 36 "Slovenian" 37 "Malaysian" 38 "Austrian" 39 "Vietnamese" 40 "Azerbaijani" 41 "Amerian" 42 "Catalan" 43 "Bulgarian" 44 "Lithuanian" 45 "Latvian" 46 "Estonian" ;
VAL_ 1289 ICC_Day_Displaysts_509h 0 "Not Active" 1 "Active" ;
VAL_ 1290 BMS_HvBattCellOverU 0 "Normal" 1 "Fault Level 1" 2 "Fault Level 2" 3 "Fault Level 3" 4 "Fault Level 4" ;
VAL_ 1290 BMS_HvBattCellUnderU 0 "Normal" 1 "Fault Level 1" 2 "Fault Level 2" 3 "Fault Level 3" 4 "Fault Level 4" ;
VAL_ 1290 BMS_HvBattUnderU 0 "Normal" 1 "Fault Level 1" 2 "Fault Level 2" ;
VAL_ 1290 BMS_HvBattDischargeOverCurrent 0 "Normal" 1 "Fault Level 1" 2 "Fault Level 2" 3 "Fault Level 3" 4 "Fault Level 4" ;
VAL_ 1290 BMS_HvBattChargeOverCurrent 0 "Normal" 1 "Fault Level 1" 2 "Fault Level 2" 3 "Fault Level 3" 4 "Fault Level 4" ;
VAL_ 1290 BMS_HvBattOverU 0 "Normal" 1 "Fault Level 1" 2 "Fault Level 2" ;
VAL_ 1290 BMS_HvBattMismatching 0 "Normal State" 1 "Battery Pack Mismatch Failure" ;
VAL_ 1290 BMS_HvBattSocJump 0 "Normal," 1 "SOC jump warning" ;
VAL_ 1290 BMS_HvBattCellUUnif 0 "Normal" 1 "Failure" ;
VAL_ 1290 BMS_HvBattLowSoc 0 "Normal" 1 "Failure" ;
VAL_ 1290 BMS_HvBattOverSoc 0 "Normal" 1 "Failure" ;
VAL_ 1290 BMS_HvBattTempUniformity 0 "Normal" 1 "Failure" ;
VAL_ 1290 BMS_BattInterCANErr 0 "Normal" 1 "Failure" ;
VAL_ 1290 BMS_HvBattOverCharging 0 "Normal" 1 "Failure" ;
VAL_ 1290 BMS_HvBattOverTemperature 0 "Normal" 1 "Fault Level 1" 2 "Fault Level 2" 3 "Fault Level 3" 4 "Fault Level 4" ;
VAL_ 1291 BMS_TBOXHvBattMaxT 254 "Abnormal" 255 "Invalid" ;
VAL_ 1291 BMS_TBOXHvBattMinT 254 "Abnormal" 255 "Invalid" ;
VAL_ 1291 BMS_SOCLight 127 "Invalid" ;
VAL_ 1292 CHB_AppDelay_Sts 0 "NotActive" 1 "ChbDelay_ON" 2 "ChbDelay_OFF" 3 "reserved" ;
VAL_ 1292 CHB_AppMem_Sts 0 "NotActive" 1 "ChbMem_ON" 2 "ChbMem_OFF" 3 "reserved" ;
VAL_ 1292 CHB_App_Sts 0 "NotActive" 1 "Chb_ON" 2 "Chb_OFF" 3 "reserved" ;
VAL_ 1292 CHB_AppCoolorheat_Sts 0 "NotActive" 1 "ChbCool_on" 2 "ChbHeat_on" 3 "Close" 4 "ColdDrinkMode" 5 "IceCreamMode" 6 "WarmMilkMode" 7 "WarmDrinkMode" ;
VAL_ 1292 CHB_AppCoolset_Sts 0 "Not_Active" 1 "ChbCoolset_-6" 2 "ChbCoolset_-5" 3 "ChbCoolset_-4" 4 "ChbCoolset_-3" 5 "ChbCoolset_-2" 6 "ChbCoolset_-1" 7 "ChbCoolset_0" 8 "ChbCoolset_1" 9 "ChbCoolset_2" 10 "ChbCoolset_3" 11 "ChbCoolset_4" 12 "ChbCoolset_5" 13 "ChbCoolset_6" 14 "ChbCoolset_-18" 15 "ChbCoolset_-17" 16 "ChbCoolset_-16" 17 "ChbCoolset_-15" 18 "ChbCoolset_-14" 19 "ChbCoolset_-13" 20 "ChbCoolset_-12" 21 "ChbCoolset_-11" 22 "ChbCoolset_-10" 23 "ChbCoolset_-9" 24 "ChbCoolset_-8" 25 "ChbCoolset_-7" 26 "Reserved" 27 "Reserved" 28 "Reserved" 29 "Reserved" 30 "Reserved" 31 "Reserved" ;
VAL_ 1292 CHB_AppHeatset_Sts 0 "Not_Active" 1 "ChbHeatset_35" 2 "ChbHeatset_36" 3 "ChbHeatset_37" 4 "ChbHeatset_38" 5 "ChbHeatset_39" 6 "ChbHeatset_40" 7 "ChbHeatset_41" 8 "ChbHeatset_42" 9 "ChbHeatset_43" 10 "ChbHeatset_44" 11 "ChbHeatset_45" 12 "ChbHeatset_46" 13 "ChbHeatset_47" 14 "ChbHeatset_48" 15 "ChbHeatset_49" 16 "ChbHeatset_50" ;
VAL_ 1292 CHB_AppItemsLeft_Sts 0 "NotActive" 1 "ChbItemsLeft_ON" 2 "ChbItemsLeft_OFF" 3 "reserved" ;
VAL_ 1292 CHB_AppSterilization_Sts 0 "NotActive" 1 "Chbsterilize_ON" 2 "Chbsterilize_OFF" 3 "Chbsterilize_Stop" ;
VAL_ 1292 CHB_AppChbDoor_Sts 0 "NotActive" 1 "ChbDoor_ON" 2 "ChbDoor_OFF" 3 "reserved" ;
VAL_ 1292 CHB_AppItemsLeftset_Sts 0 "NotActive" 1 "CHB_ItemsLeftset_ON" 2 "CHB_ItemsLeftset_OFF" 3 "Reserved" ;
VAL_ 1295 BMS_BattFaultLampSts 0 "Lamp OFF" 1 "Lamp ON" ;
VAL_ 1295 BMS_OverTemp_LightSts 0 "Lamp OFF" 1 "Lamp ON" ;
VAL_ 1295 BMS_ThermalRunawayDis 0 "no thermalrunaway" 1 "thermalrunaway occur" ;
VAL_ 1295 BMS_TBOXIsolationFault 0 "no fault" 1 "Fault L1" 2 "Fault L2" 3 "Fault L3" ;
VAL_ 1295 BMS_PreWarmDis 0 "none" 1 "preheat state" 2 "keepwarm state" ;
VAL_ 1299 BMS_PackVoltageDis 65534 "Abnormal" 65535 "Invalid" ;
VAL_ 1299 BMS_PackCurrentDis 65534 "Abnormal" 65535 "Invalid" ;
VAL_ 1310 DrvSecSeatEasyEntryExitFb_51Eh 0 "Not Active" 1 "ON" 2 "OFF" 3 "Not Used" ;
VAL_ 1310 PassSecSeatEasyEntryExitFb_51Eh 0 "Not Active" 1 "ON" 2 "OFF" 3 "Not Used" ;
VAL_ 1310 DrvSecSeatNeedMemory_51Eh 0 "No Request" 1 "Request" 2 "Reserved" 3 "Reserved" ;
VAL_ 1310 DrvSecMemoryFb_51Eh 0 "Not Active" 1 "Success" 2 "Fail" 3 "Ongoing" ;
VAL_ 1310 DrvSecRecoverFb_51Eh 0 "Not Active" 1 "Success" 2 "Fail" 3 "Ongoing" ;
VAL_ 1310 PassSecSeatNeedMemory_51Eh 0 "No Request" 1 "Request" 2 "Reserved" 3 "Reserved" ;
VAL_ 1310 PassSecMemoryFb_51Eh 0 "Not Active" 1 "Success" 2 "Fail" 3 "Ongoing" ;
VAL_ 1310 PassSecRecoverFb_51Eh 0 "Not Active" 1 "Success" 2 "Fail" 3 "Ongoing" ;
VAL_ 1310 PassSecSeatExpSwCmd_51Eh 0 "Not active" 1 "Expansion" 2 "Reset" 3 "Reserve" ;
VAL_ 1310 PassTrdSeatSwCmd_51Eh 0 "Not active" 1 "Back Forwardwarde" 2 "Back Bacwardkwarde" 3 "Cush Forwardwarde" 4 "Cush Bacwardkwarde" ;
VAL_ 1310 BBCM_RLSeatSwCmd3rd 0 "Not active" 1 "Back Forwardwarde" 2 "Back Bacwardkwarde" 3 "Cush Forwardwarde" 4 "Cush Bacwardkwarde" ;
VAL_ 1310 BBCM_RLSeatExpSwCmd2rd 0 "Not Active" 1 "Entrence" 2 "Reset" 3 "Reserve" ;
VAL_ 1310 BBCM_RLSeatExpSwSt2rd 0 "Not Active" 1 "Entrence" 2 "Reset" 3 "Stop" ;
VAL_ 1310 PassSecSeatExpSwSt_51Eh 0 "Not active" 1 "Expansion" 2 "Reset" 3 "Stop" ;
VAL_ 1310 BBCM_RLSeatExpRstStsFb 0 "Not at Expansion position" 1 "Expansion Success" ;
VAL_ 1310 PassSecSeatMovFailCause_51Eh 0 "Not active" 1 "Antipinch event" 2 "Not Learned" 3 "Motor Circuit Failure" 4 "Second-row right seat manually interrupt" 5 "Three-row one-key switch interruption" 6 "Passenger seat occupied" 7 "Third-row right seat occupied" 8 "Third-row right seat unfolded state" 9 "Passenger seat abnormal" 10 "QueenSeat" 11 "Low Priority" 12 "No current configuration" ;
VAL_ 1310 DrvSecSeatMovFailCause_51Eh 0 "Not active" 1 "Antipinch event" 2 "Not Learned" 3 "Motor Circuit Failure" 4 "Second-row left seat manually interrupt" 5 "Low Priority" 6 "No current configuration" ;
VAL_ 1310 PassTrdSeatMovFailCause_51Eh 0 "Not active" 1 "Antipinch event" 2 "Not Learned" 3 "Motor Circuit Failure" 4 "Gear Not P" 5 "Third-row right seat occupied" 6 "Third-row right seat manually interrupt" 7 "Low Priority" 8 "Anti-addiction" 9 "Third-row right seat not fold" 10 "Third-row right seat return  to position" 11 "No current configuration" ;
VAL_ 1310 DrvTrdSeatMovFailCause_51Eh 0 "Not active" 1 "Antipinch event" 2 "Not Learned" 3 "Motor Circuit Failure" 4 "Gear Not P" 5 "Third-row left seat occupied" 6 "Third-row left seat manually interrupt" 7 "Low Priority" 8 "Anti-addiction" 9 "Third-row left seat not fold" 10 "Third-row left seat return  to position" 11 "No current configuration" ;
VAL_ 1314 HCU_V2lDisChgBck 0 "Not_Active" 1 "V2L_ON" 2 "OFF" ;
VAL_ 1314 HCU_DisChgMemFed 0 "Not_Active" 1 "Remember" 2 "No_Remember" 3 "Reserved" ;
VAL_ 1314 HCU_V2VDisChgBck 0 "Not_Active" 1 "V2V_ON" 2 "OFF" ;
VAL_ 1314 HCU_V2l_IntlDisChgBck 0 "Not_Active" 1 "V2L_ON" 2 "OFF" ;
VAL_ 1314 HCU_FuelDetnOpDefeated 0 "No_Prompt" 1 "Prompt" ;
VAL_ 1314 HCU_FuelDetnModSwtFed 0 "Not_Active" 1 "ON" 2 "OFF" 3 "Invalid" ;
VAL_ 1314 HCU_FuelDetnStateFed 0 "Not_Active" 1 "HighIdle" 2 "LowIdle" 3 "Invalid" ;
VAL_ 1314 HCU_HVDownRepairModeFed 0 "Not_Active" 1 "ON" 2 "OFF" 3 "Invalid" ;
VAL_ 1314 HCU_TrailerMode 0 "Not_Active" 1 "ON" 2 "OFF" 3 "Invalid" ;
VAL_ 1314 HCU_TABSwtFed_522h 0 "Not_Active" 1 "Active" 2 "Stand_by" 3 "Failed" ;
VAL_ 1314 HCU_KeyDriveModememory 0 "Not_Active" 1 "Remember" 2 "No_Remember" ;
VAL_ 1314 HCU_DrivePowerDispSetFed 0 "Not_Active" 1 "PercentDisp" 2 "kWDisp" ;
VAL_ 1314 HCU_EXPERTNormFed 0 "Not_Active" 1 "ON" 2 "OFF" 3 "Invalid" ;
VAL_ 1314 HCU_4LModeFed 0 "Not_Active" 1 "Active" ;
VAL_ 1314 HCU_EXPERTEcoFed 0 "Not_Active" 1 "ON" 2 "OFF" 3 "Invalid" ;
VAL_ 1314 HCU_SingleRegnRmn 0 "Not_Active" 1 "Active" ;
VAL_ 1314 HCU_DRIFTModeSts 0 "Not_Active" 1 "Entry_Mode" 2 "Master_mode" 3 "Expert_mode" ;
VAL_ 1314 HCU_EXPERTAWDFed 0 "Not_Active" 1 "ON" 2 "OFF" 3 "Invalid" ;
VAL_ 1314 HCU_EXPERTRWDFed 0 "Not_Active" 1 "ON" 2 "OFF" 3 "Invalid" ;
VAL_ 1314 HCU_CrossaxisFed 0 "Not_Active" 1 "Active" 2 "Stand_by" 3 "Failed" ;
VAL_ 1314 HCU_EXPERTSportFed 0 "Not_Active" 1 "ON" 2 "OFF" 3 "Invalid" ;
VAL_ 1314 HCU_StopChrgnModeFed 0 "Not_Active" 1 "Silence" 2 "Quick" ;
VAL_ 1314 HCU_StopChrgnFed 0 "Not_Active" 1 "ON" 2 "OFF" 3 "Invalid" ;
VAL_ 1314 HCU_CLIMBFed 0 "Not_Active" 1 "ON" 2 "OFF" 3 "Invalid" ;
VAL_ 1314 HCU_EXPERTAutoFed 0 "Not_Active" 1 "ON" 2 "OFF" 3 "Invalid" ;
VAL_ 1314 HCU_HEV_FunctionLimit 0 "Not_Active" 1 "Active" ;
VAL_ 1314 HCU_ParkingChargeReminder 0 "Not_Active" 1 "Active" ;
VAL_ 1314 HCU_PowerCut 0 "Not_Active" 1 "Active" ;
VAL_ 1314 HCU_IMMOReleaseSignal 0 "Not_Active" 1 "Active" ;
VAL_ 1314 HCU_LVPowSupSYSAbn_lit 0 "Not_Active" 1 "Active" ;
VAL_ 1314 HCU_ChrgnFctMemSt 0 "Not_Active" 1 "Remember" 2 "No_Remember" 3 "Reserved" ;
VAL_ 1314 HCU_PowerModeChangeInhibit 0 "Not_Active" 1 "Active" ;
VAL_ 1314 HCU_DisconnectChagWarn 0 "Not_Active" 1 "Active" ;
VAL_ 1314 HCU_EngineRunClmReq 0 "Not_Active" 1 "Active" ;
VAL_ 1314 HCU_VehicleSpeedMax_Limit 0 "Not_Active" 1 "Active" ;
VAL_ 1314 HCU_AccleAbility_Limit 0 "Not_Active" 1 "Active" ;
VAL_ 1314 HCU_DriveInhibit_GearP 0 "Not_Active" 1 "Active" ;
VAL_ 1314 HCU_SetModeNotChange 0 "Not_Active" 1 "Active" ;
VAL_ 1314 HCU_UTURNSnowFed 0 "Not_Active" 1 "Active" ;
VAL_ 1314 HCU_PowerLevel 0 "Init" 1 "Level_1" 2 "Level_2" 3 "Level_3" 4 "Level_4" ;
VAL_ 1314 HCU_TowingModeEna 0 "No Prompt" 1 "Prompt" ;
VAL_ 1314 HCU_LeaveVehicleWarning 0 "Not_Active" 1 "Active" ;
VAL_ 1314 HCU_DedicatedModeInhibit 0 "Not_Active" 1 "Active" ;
VAL_ 1314 HCU_DisChargeStopFault 0 "Init" 1 "LowSOC" 2 "LowFuel" ;
VAL_ 1314 HCU_RearEDLSts 0 "No Lock" 1 "UNLock" 2 "Lock" 3 "Warning" 4 "UnAvailable" 5 "Stuck_Open" 6 "Stuck_Close" 7 "Reserved" 8 "Reserved" 9 "Reserved" ;
VAL_ 1314 HCU_FrntEDLSts 0 "No Lock" 1 "UNLock" 2 "Lock" 3 "Warning" 4 "UnAvailable" 5 "Stuck Open" 6 "Stuck Close" 7 "Rear4LReq" 8 "RearReq" 9 "4LReq" ;
VAL_ 1314 HCU_DriveMode_JT 0 "ECO" 1 "NORMAL" 2 "SPORT" 3 "SNOW" 4 "MUD" 5 "OffRoad" 6 "SAND" 7 "ROCK" 8 "EXPERT" 9 "X" 10 "WADE" 11 "UTURN" 12 "DRIFT" 13 "TOW" 14 "OffroadRace" 15 "CarSickRelfMode" 16 "CleverEngy" 17 "DCM" ;
VAL_ 1314 HCU_SocManageFed 0 "Default" 1 "Pure_electricity_priority_mode" 2 "Fuel_priority_mode" 3 "SOC_hold_mode" 4 "SAVE" 5 "Charge" ;
VAL_ 1314 HCU_SinglePedalMemFed 0 "ON" 1 "OFF" ;
VAL_ 1314 HCU_CCOSwtFed 0 "Not_Active" 1 "Active" 2 "Stand_by" 3 "Failed" ;
VAL_ 1314 HCU_DrvGearShiftFailureIndcn 0 "No_Command" 1 "brake_pedal_applied" 2 "Over_Speed" 3 "Charge_Gun_Connect" 4 "EPB_Can_Not_Lock" 5 "EPB_Can_Not_Release" 6 "Invalid_shift" 7 "Shift_fault" 8 "BrkPedl_to_start" 9 "OpenDoor_Shift" ;
VAL_ 1314 HCU_UTURNSandFed 0 "OFF" 1 "ON" ;
VAL_ 1314 HCU_CruiseControlStatus 0 "Not_Active" 1 "Active" 2 "Stand_by" 3 "Fault" ;
VAL_ 1314 HCU_EXPERTEESPSet 0 "ALLON" 1 "TCS_VDC_OFF" 2 "ALLOFF" 3 "Reserved" ;
VAL_ 1314 HCU_EgyRegenLevel 0 "Off" 1 "Low" 2 "High" 3 "middle" 4 "SinglePedl" ;
VAL_ 1314 HCU_EngyFlowToDisp 0 "Init" 1 "No_EngyFlow" 2 "Engine Idling" 3 "EV_FWD" 4 "EV_FWD_Regene" 5 "EV_RWD" 6 "EV_RWD_Regene" 7 "EV_4WD" 8 "EV_4WD_Regene" 9 "Series_FWD_BattChg" 10 "Series_FWD_BattDisChg" 11 "Series_FWD_BattNoCurr" 12 "Series_FWD_Regene" 13 "Series_RWD_BattChg" 14 "Series_RWD_BattDisChg" 15 "Series_RWD_BattNoCurr" 16 "Series_RWD_Regene" 17 "Series_4WD_BattChg" 18 "Series_4WD_BattDisChg" 19 "Series_4WD_BattNoCurr" 20 "Series_4WD_Regene" 21 "Parallel_FWD_BattChg" 22 "Parallel_FWD_BattDisChg" 23 "Parallel_FWD_BattNoCurr" 24 "Parallel_FWD_Regene" 25 "Parallel_4WD_BattChg" 26 "Parallel_4WD_BattDisChg" 27 "Parallel_4WD_BattNoCurr" 28 "Parallel_4WD_Regene" 29 "StopCharging_BatChg" 30 "StopCharging_BatDChg" 31 "StopCharging_BatNoCurr" ;
VAL_ 1314 HCU_UTURNGrassFed 0 "OFF" 1 "ON" ;
VAL_ 1314 HCU_UTURNMudFed 0 "OFF" 1 "ON" ;
VAL_ 1314 HCU_LTCDispFed 0 "Not Active" 1 "WLTC" 2 "CLTC" ;
VAL_ 1314 HCU_iTAS_Warn 0 "No_Warn" 1 "ELD Unable to lock" 2 "Please_Release_EPB" 3 "Please_slow_down" 4 "Disc temperature too high" 5 "vehicle is stuck" 6 "iTAS active max time" 7 "Please Open in D" ;
VAL_ 1314 HCU_iCCO_Warn 0 "No_Warn" 1 "Please_Release_EPB" 2 "Please_slow_down" 3 "Please_Close_ Door and Belt" 4 "Please_Open in D or N" 5 "Please_Close_APA/ACC/CC" 6 "Please_Exit_HDC/AVH" 7 "Please_Switch to Snow/Mud/Sand/Rock" 8 "Please Depress the brake pedal" 9 "iCCO Exited" 10 "Reserved" 11 "Reserved" 12 "Reserved" 13 "Reserved" 14 "Reserved" 15 "Reserved" ;
VAL_ 1314 HCU_DriveModeChangeFail 0 "NOT FAIL" 1 "FAIL" ;
VAL_ 1314 HCU_25_Crossaxis_Warn 0 "No_Warn" 1 "Please_Release_EPB" 2 "Crossaxis Exited" 3 "Please_Open in D" 4 "Please_Close_ Door and Belt" 5 "Please Depress the brake pedal" 6 "Not Adjust Suspension Height" 7 "Reserved" ;
VAL_ 1314 HCU_25_EDLFed 0 "Not_Active" 1 "Forward" 2 "Backward" 3 "Reserved" ;
VAL_ 1314 HCU_DraggingModeRemind 0 "Not_Active" 1 "Enter" 2 "Working" 3 "Exit" 4 "Reserved" 5 "Reserved" 6 "Reserved" 7 "Reserved" ;
VAL_ 1314 HCU_iTASSceneReq 0 "Not Active" 1 "Snow" 2 "Mud" 3 "Sand" 4 "Grass" 5 "Exit" ;
VAL_ 1314 HCU_25_iTAS_SlopWarn 0 "No_Warn" 1 "Active" 2 "Reserved" 3 "Reserved" ;
VAL_ 1314 HCU_ExterTempLowHint 0 "Init" 1 "Temp to HEV" 2 "Temp to EngRun" 3 "reserved" ;
VAL_ 1314 HCU_iTAS_Active 0 "Not_Active" 1 "Standby" 2 "Active" 3 "Filed" ;
VAL_ 1314 HCU_25_VehSpdOffroadRmn 0 "Not Acitve" 1 "Acitve" ;
VAL_ 1314 HCU_DrivingModReq 0 "Normal" 1 "Snow" 2 "Mud" 3 "Sand" 4 "Rock" 5 "Wade" 6 "Expert" 7 "UTURN" 8 "DRIFT" 9 "OffroadRace" 10 "Reserved" 11 "Reserved" 12 "Reserved" 13 "Reserved" 14 "Reserved" 15 "Reserved" 16 "Reserved" 17 "Reserved" 18 "Reserved" 19 "Reserved" 20 "Reserved" 21 "Reserved" 22 "Reserved" 23 "Reserved" 24 "Reserved" 25 "Reserved" 26 "Reserved" 27 "Reserved" 28 "Reserved" 29 "Reserved" 30 "Reserved" 31 "Reserved" ;
VAL_ 1314 HCU_25_iDRIFT_Warn 0 "No_Warn" 1 "Please_Close_ Door and Belt" 2 "Please stop the vehicle" 3 "Error" 4 "Not Adjust Suspension Height" ;
VAL_ 1314 HCU_25_SetVehSpdOffroad 0 "No_Warn" 1 "Active" 2 "Reserved" 3 "Reserved" ;
VAL_ 1314 HCU_25_LaunchMod_Warn 0 "No_Warn" 1 "Active" 2 "Exit" 3 "Error" 4 "Reserved" 5 "Reserved" 6 "Reserved" 7 "Reserved" ;
VAL_ 1314 HCU_25_TAB_Warn 0 "No Warn" 1 "Please open CCO" 2 "Please Unlock EDL" 3 "Prohibit locking EDL" 4 "Reserved" ;
VAL_ 1314 HCU_25_CCO_TextDisp 0 "No_Warn" 1 "Please_Release_EPB" 2 "Please_Slow_Down" 3 "Please_Close_ Door and Belt" 4 "Please_Open in D" 5 "Please_Close_APA/ACC/CC" 6 "Please_Exit_HDC" 7 "Please_Switch to Mud/Sand/Rock" 8 "Reduce_Speed_Below 12kph" 9 "Please_Close_CCO" 10 "CC0 Exited" ;
VAL_ 1314 HCU_25_DCM_Warn 0 "No_Warn" 1 "Please_Release_EPB" 2 "Please_Close_ Door and Belt" 3 "Please_Open in D/R" 4 "Please_Close_APA/ACC/CC" 5 "Please_Exit_HDC" 6 "Please Depress the brake pedal" 7 "CCM Exited" 8 "Please enter or exit this mode when the vehicle is stationary" 9 "power limit" 10 "Please release the accelerator pedal" 11 "Please depress the brake pedal" 12 "Reserved" 13 "Reserved" 14 "Reserved" 15 "Reserved" ;
VAL_ 1314 HCU_25_CCMFed 0 "Not Active" 1 "On" 2 "Off" 3 "Reserved" ;
VAL_ 1314 HCU_CrossBorderSts 0 "Not Active" 1 "On" 2 "Off" 3 "Reserved" ;
VAL_ 1314 HCU_stCleverDrvAct_522h 0 "OFF" 1 "ON" 2 "Reserved" 3 "Invalid" ;
VAL_ 1314 HCU_stCleverRgnAct_522h 0 "OFF" 1 "ON" 2 "Reserved" 3 "Invalid" ;
VAL_ 1314 HCU_stCleverMainAct_522h 0 "OFF" 1 "ON" 2 "Reserved" 3 "Invalid" ;
VAL_ 1314 EnergySavingModeSts_522h 0 "Not Active" 1 "ON" 2 "OFF" 3 "Reserved" ;
VAL_ 1314 HCU_facCleverDrvActRstFed_522h 0 "Not Active" 1 "success" 2 "Fail" 3 "Reserved" ;
VAL_ 1314 HCU_ATCM_Operation_REQ_522h 0 "Not Active" 1 "Switch to sailfunc indiction" 2 "Switch to upbeach indiction" 3 "misoperation indiction”press sailfunc sw when conenmod “" 4 "misoperation indiction”press upbeach  sw when conenmod“" 5 "misoperation indiction”press upbeach sw when wadests“" 6 "reserved" 7 "reserved" ;
VAL_ 1314 HCU_ModeSwFailureIndc_522h 0 "Not Active" 1 "Entry navigation failed“Car door is not closed”" 2 "Entry navigation failed“Rearview mirror not deployed”" 3 "Entry navigation failed“Intake and exhaust waterproof valve malfunction”" 4 "Entry navigation failed“Speed too fast”" 5 "Entry navigation failed“Low battery”" 6 "Entry navigation failed“Air conditioning drain valve malfunction|Cooling fan malfunction”" ;
VAL_ 1314 HCU_Sailmode_522h 0 "Convenmod" 1 "SalWadeSts" 2 "DpWadeSts" 3 "SailingFunc" 4 "UpbeachSts" 5 "WaitfinspSts" 6 "EmerfloatingSts" 7 "Reserved" ;
VAL_ 1314 HCU_CarSickRelfModeFb 0 "NotActive" 1 "ON" 2 "OFF" ;
VAL_ 1314 HCU_DeepSnowSts_522h 0 "NOT ACTIVE" 1 "ON" 2 "OFF" ;
VAL_ 1314 DriveModeChangeFailReason_522h 0 "NOT FAIL" 1 "Fail" 2 "EngySavMod_Fail" 3 "Reserved" ;
VAL_ 1314 HCU_CarSickRelfModeDisReason 0 "No prompts" 1 "Please exit off-road mode" 2 "Please exit CCO mode" 3 "Please exit power saving mode" 4 "Please exit Towing Mode" 5 "Please exit TrailerMode" 6 "Please exit CCMode" 7 "Please exit ADS mode" ;
VAL_ 1314 HCU_DCMSwtFed 0 "not active" 1 "sand" 2 "snow" 3 "crawl" 4 "forest" 5 "Tug of war" 6 "Rescue" 7 "Reserved" ;
VAL_ 1318 ICC_SET_TDL_Rhythm_Switch 0 "Not_Active" 1 "ON" 2 "OFF" 3 "reserved" ;
VAL_ 1318 ICC_SET_TDL_Switch 0 "Not_Active" 1 "ON" 2 "OFF" 3 "reserved" ;
VAL_ 1318 ICC_SET_TDL_ColourModeAdj 0 "Not_Active" 1 "Monochrome" 2 "panchromatic" 3 "OFF" 4 "Reserved" 5 "Reserved" 6 "Reserved" 7 "Reserved" ;
VAL_ 1318 ICC_TDL_RhythmReq 0 "Not_Active" 1 "Mode1" 2 "Mode2" 3 "Mode3" 4 "Mode4" 5 "Mode5" 6 "Mode6" 7 "Reserved" ;
VAL_ 1318 ICC_VoiceWake 0 "Not_Active" 1 "ON" 2 "OFF" 3 "LHFawaken" 4 "LHRawaken" 5 "RHFawaken" 6 "RHRawaken" 7 "Reserved" ;
VAL_ 1318 ICC_TDLAssociatedDriverModeSw 0 "Not_Active" 1 "ON" 2 "OFF" 3 "reserved" ;
VAL_ 1318 ICC_SET_ApiluminanceAdj 0 "Not_Active" 1 "Level1" 2 "Level2" 3 "Level3" 4 "Level4" 5 "Level5" 6 "Level6" 7 "Level7" 8 "Level8" 9 "Reserved" 10 "Reserved" 11 "Reserved" 12 "Reserved" 13 "Reserved" 14 "Reserved" 15 "Reserved" ;
VAL_ 1318 ICC_SET_MusicLoudness_120HZ 0 "Not_Active" 1 "Level_1" 2 "Level_2" 3 "Level_3" 4 "Level_4" 5 "Level_5" 6 "Level_6" 7 "Level_7" 8 "Level_8" 9 "Level_9" 10 "Level_10" 11 "Level_11" 12 "Level_12" 13 "Level_13" 14 "Level_14" 15 "Level_15" ;
VAL_ 1318 ICC_SET_MusicLoudness_250HZ 0 "Not_Active" 1 "Level_1" 2 "Level_2" 3 "Level_3" 4 "Level_4" 5 "Level_5" 6 "Level_6" 7 "Level_7" 8 "Level_8" 9 "Level_9" 10 "Level_10" 11 "Level_11" 12 "Level_12" 13 "Level_13" 14 "Level_14" 15 "Level_15" ;
VAL_ 1318 ICC_SET_MusicLoudness_500HZ 0 "Not_Active" 1 "Level_1" 2 "Level_2" 3 "Level_3" 4 "Level_4" 5 "Level_5" 6 "Level_6" 7 "Level_7" 8 "Level_8" 9 "Level_9" 10 "Level_10" 11 "Level_11" 12 "Level_12" 13 "Level_13" 14 "Level_14" 15 "Level_15" ;
VAL_ 1318 ICC_SET_MusicLoudness_1000HZ 0 "Not_Active" 1 "Level_1" 2 "Level_2" 3 "Level_3" 4 "Level_4" 5 "Level_5" 6 "Level_6" 7 "Level_7" 8 "Level_8" 9 "Level_9" 10 "Level_10" 11 "Level_11" 12 "Level_12" 13 "Level_13" 14 "Level_14" 15 "Level_15" ;
VAL_ 1318 ICC_SET_MusicLoudness_1500HZ 0 "Not_Active" 1 "Level_1" 2 "Level_2" 3 "Level_3" 4 "Level_4" 5 "Level_5" 6 "Level_6" 7 "Level_7" 8 "Level_8" 9 "Level_9" 10 "Level_10" 11 "Level_11" 12 "Level_12" 13 "Level_13" 14 "Level_14" 15 "Level_15" ;
VAL_ 1318 ICC_SET_MusicLoudness_2000HZ 0 "Not_Active" 1 "Level_1" 2 "Level_2" 3 "Level_3" 4 "Level_4" 5 "Level_5" 6 "Level_6" 7 "Level_7" 8 "Level_8" 9 "Level_9" 10 "Level_10" 11 "Level_11" 12 "Level_12" 13 "Level_13" 14 "Level_14" 15 "Level_15" ;
VAL_ 1318 ICC_SET_MusicLoudness_6000HZ 0 "Not_Active" 1 "Level_1" 2 "Level_2" 3 "Level_3" 4 "Level_4" 5 "Level_5" 6 "Level_6" 7 "Level_7" 8 "Level_8" 9 "Level_9" 10 "Level_10" 11 "Level_11" 12 "Level_12" 13 "Level_13" 14 "Level_14" 15 "Level_15" ;
VAL_ 1318 ICC_TDL_FlowLightSw 0 "Not_Active" 1 "ON" 2 "OFF" 3 "reserved" ;
VAL_ 1318 ICC_TDL_FlowLightModeAdj 0 "Not Active" 1 "mode1" 2 "mode2" 3 "mode3" 4 "mode4" 5 "mode5" 6 "mode6" 7 "Reserved" ;
VAL_ 1320 ICC_Chb_Req 0 "Not_Active" 1 "Chb_ON" 2 "Chb_OFF" 3 "reserved" ;
VAL_ 1320 ICC_ChbMem_Req 0 "Not_Active" 1 "ChbMem_ON" 2 "ChbMem_OFF" 3 "reserved" ;
VAL_ 1320 ICC_ChbDelay_Req 0 "Not_Active" 1 "ChbDelay_ON" 2 "ChbDelay_OFF" 3 "reserved" ;
VAL_ 1320 ICC_ChbSterilization_Req 0 "Not_Active" 1 "Chbsterilize_ON" 2 "Chbsterilize_OFF" 3 "reserved" ;
VAL_ 1320 ICC_ChbItemsLeft_Req 0 "Not_Active" 1 "Chbhanddown_ON" 2 "Chbhanddown_OFF" 3 "reserved" ;
VAL_ 1320 ICC_ParkingRadarSwSet 0 "Not_active" 1 "ON" 2 "OFF" ;
VAL_ 1320 ICC_ChbCoolset_Req 0 "Not_Active" 1 "ChbCoolset_-6" 2 "ChbCoolset_-5" 3 "ChbCoolset_-4" 4 "ChbCoolset_-3" 5 "ChbCoolset_-2" 6 "ChbCoolset_-1" 7 "ChbCoolset_0" 8 "ChbCoolset_1" 9 "ChbCoolset_2" 10 "ChbCoolset_3" 11 "ChbCoolset_4" 12 "ChbCoolset_5" 13 "ChbCoolset_6" 14 "ChbCoolset_-18" 15 "ChbCoolset_-17" 16 "ChbCoolset_-16" 17 "ChbCoolset_-15" 18 "ChbCoolset_-14" 19 "ChbCoolset_-13" 20 "ChbCoolset_-12" 21 "ChbCoolset_-11" 22 "ChbCoolset_-10" 23 "ChbCoolset_-9" 24 "ChbCoolset_-8" 25 "ChbCoolset_-7" 26 "Reserved" 27 "Reserved" 28 "Reserved" 29 "Reserved" 30 "Reserved" 31 "Reserved" ;
VAL_ 1320 ICC_ChbCoolorheat_Req 0 "Not_Active" 1 "ChbCool_ON" 2 "ChbHeat_ON" 3 "Close" 4 "ColdDrinkMode" 5 "IceCreamMode" 6 "WarmMilkMode" 7 "WarmDrinkMode" ;
VAL_ 1320 ICC_ChbHeatset_Req 0 "Not_Active" 1 "ChbHeatset_35" 2 "ChbHeatset_36" 3 "ChbHeatset_37" 4 "ChbHeatset_38" 5 "ChbHeatset_39" 6 "ChbHeatset_40" 7 "ChbHeatset_41" 8 "ChbHeatset_42" 9 "ChbHeatset_43" 10 "ChbHeatset_44" 11 "ChbHeatset_45" 12 "ChbHeatset_46" 13 "ChbHeatset_47" 14 "ChbHeatset_48" 15 "ChbHeatset_49" 16 "ChbHeatset_50" ;
VAL_ 1322 STAT_AMPAlarm 0 "Not Active" 1 "Other CHIME" 2 "PDC_FL only" 3 "PDC_FR only" 4 "PDC_RL only" 5 "PDC_RR only" 6 "PDC_FL+FR" 7 "PDC_FL+RL" 8 "PDC_FL+RR" 9 "PDC_FR+RL" 10 "PDC_FR+RR" 11 "PDC_RL+RR" 12 "PDC_FL+FR+RL" 13 "PDC_FL+FR+RR" 14 "PDC_FL+RL+RR" 15 "PDC_FR+RL+RR" 16 "PDC_all" 17 "BSD_L only" 18 "BSD_R only" 19 "BSD_L+R" 20 "CHIME OFF" 21 "Reserved" 22 "Reserved" 23 "Reserved" 24 "Reserved" 25 "Reserved" 26 "Reserved" 27 "Reserved" 28 "Reserved" 29 "Reserved" 30 "Reserved" 31 "Reserved" 32 "Reserved" 33 "Reserved" 34 "Reserved" 35 "Reserved" 36 "Reserved" 37 "Reserved" 38 "Reserved" 39 "Reserved" 40 "Reserved" 41 "Reserved" 42 "Reserved" 43 "Reserved" 44 "Reserved" 45 "Reserved" 46 "Reserved" 47 "Reserved" 48 "Reserved" 49 "Reserved" 50 "Reserved" 51 "Reserved" 52 "Reserved" 53 "Reserved" 54 "Reserved" 55 "Reserved" 56 "Reserved" 57 "Reserved" 58 "Reserved" 59 "Reserved" 60 "Reserved" 61 "Reserved" 62 "Reserved" 63 "Reserved" ;
VAL_ 1324 TirePositionWarning_LHFTire 0 "Normal" 1 "Rapid_Air_Loss(Reserved)" 2 "Low_Pressure" 3 "Low Batter" 4 "High_Pressure(Reserved)" 5 "High_Temperature" 6 "Error_Mode" 7 "Not_used(Reserved)" ;
VAL_ 1324 TirePositionWarning_RHFTire 0 "Normal" 1 "Rapid_Air_Loss(Reserved)" 2 "Low_Pressure" 3 "Low Batter" 4 "High_Pressure(Reserved)" 5 "High_Temperature" 6 "Error_Mode" 7 "Not_used(Reserved)" ;
VAL_ 1324 TirePositionWarning_LHRTire 0 "Normal" 1 "Rapid_Air_Loss(Reserved)" 2 "Low_Pressure" 3 "Low Batter" 4 "High_Pressure(Reserved)" 5 "High_Temperature" 6 "Error_Mode" 7 "Not_used(Reserved)" ;
VAL_ 1324 TirePositionWarning_RHRTire 0 "Normal" 1 "Rapid_Air_Loss(Reserved)" 2 "Low_Pressure" 3 "Low Batter" 4 "High_Pressure(Reserved)" 5 "High_Temperature" 6 "Error_Mode" 7 "Not_used(Reserved)" ;
VAL_ 1324 TirePressureWarningLampSts 0 "Lamp_Off" 1 "Lamp_Flashing" 2 "Lamp_On" 3 "Not_used" ;
VAL_ 1324 TirePressureSystemFailSts 0 "Fail_Not_Present" 1 "Fail_Present" ;
VAL_ 1326 ICC_DWDOnOff_Req 0 "Not Active" 1 "ON" 2 "OFF" ;
VAL_ 1326 ICC_ContainerLightSet 0 "Not_Active" 1 "ON" 2 "OFF" 3 "reserved" ;
VAL_ 1328 RADAR_1_RadarDetectSts 0 "No_Detecting_Startup" 1 "Front_Radar_Detecting" 2 "Rear_Radar_Detecting" 3 "Not_Used" ;
VAL_ 1328 RADAR_1_RadarWorkSts 0 "Not_Active" 1 "Active" ;
VAL_ 1328 RADAR_1_RHMRRadarSensorDistance 32 "Not_Used" 33 "Not_Used" 34 "Not_Used" 35 "Not_Used" 36 "Not_Used" 37 "Not_Used" 38 "Not_Used" 39 "Not_Used" 40 "Not_Used" 41 "Not_Used" 42 "Not_Used" 43 "Not_Used" 44 "Not_Used" 45 "Not_Used" 46 "Not_Used" 47 "Not_Used" 48 "Not_Used" 49 "Not_Used" 50 "Not_Used" 51 "Not_Used" 52 "Not_Used" 53 "Not_Used" 54 "Not_Used" 55 "Not_Used" 56 "Not_Used" 57 "Not_Used" 58 "Not_Used" 59 "Not_Used" 60 "Not_Used" 61 "Not_Used" 62 "Startup" 63 "Sensor_Err" ;
VAL_ 1328 RADAR_1_LHRRadarSensorDistance 32 "Not_Used" 33 "Not_Used" 34 "Not_Used" 35 "Not_Used" 36 "Not_Used" 37 "Not_Used" 38 "Not_Used" 39 "Not_Used" 40 "Not_Used" 41 "Not_Used" 42 "Not_Used" 43 "Not_Used" 44 "Not_Used" 45 "Not_Used" 46 "Not_Used" 47 "Not_Used" 48 "Not_Used" 49 "Not_Used" 50 "Not_Used" 51 "Not_Used" 52 "Not_Used" 53 "Not_Used" 54 "Not_Used" 55 "Not_Used" 56 "Not_Used" 57 "Not_Used" 58 "Not_Used" 59 "Not_Used" 60 "Not_Used" 61 "Not_Used" 62 "Startup" 63 "Sensor_Err" ;
VAL_ 1328 RADAR_1_LHMRRadarSensorDistance 32 "Not_Used" 33 "Not_Used" 34 "Not_Used" 35 "Not_Used" 36 "Not_Used" 37 "Not_Used" 38 "Not_Used" 39 "Not_Used" 40 "Not_Used" 41 "Not_Used" 42 "Not_Used" 43 "Not_Used" 44 "Not_Used" 45 "Not_Used" 46 "Not_Used" 47 "Not_Used" 48 "Not_Used" 49 "Not_Used" 50 "Not_Used" 51 "Not_Used" 52 "Not_Used" 53 "Not_Used" 54 "Not_Used" 55 "Not_Used" 56 "Not_Used" 57 "Not_Used" 58 "Not_Used" 59 "Not_Used" 60 "Not_Used" 61 "Not_Used" 62 "Startup" 63 "Sensor_Err" ;
VAL_ 1328 RADAR_1_RHRRadarSensorDistance 32 "Not_Used" 33 "Not_Used" 34 "Not_Used" 35 "Not_Used" 36 "Not_Used" 37 "Not_Used" 38 "Not_Used" 39 "Not_Used" 40 "Not_Used" 41 "Not_Used" 42 "Not_Used" 43 "Not_Used" 44 "Not_Used" 45 "Not_Used" 46 "Not_Used" 47 "Not_Used" 48 "Not_Used" 49 "Not_Used" 50 "Not_Used" 51 "Not_Used" 52 "Not_Used" 53 "Not_Used" 54 "Not_Used" 55 "Not_Used" 56 "Not_Used" 57 "Not_Used" 58 "Not_Used" 59 "Not_Used" 60 "Not_Used" 61 "Not_Used" 62 "Startup" 63 "Sensor_Err" ;
VAL_ 1328 RADAR_1_RHFRadarSensorDistance 28 "Not_Used" 29 "Not_Used" 30 "Startup" 31 "Sensor_Err" ;
VAL_ 1328 RADAR_1_LHFRadarSensorDistance 28 "Not_Used" 29 "Not_Used" 30 "Startup" 31 "Sensor_Err" ;
VAL_ 1328 RADAR_1_RHMFRadarSensorDistance 28 "Not_Used" 29 "Not_Used" 30 "Startup" 31 "Sensor_Err" ;
VAL_ 1328 RADAR_1_ParkingRadarSwSts 0 "Off" 1 "On" ;
VAL_ 1328 RADAR_1_AudibleBeepRate 0 "Off" 1 "On" 2 "4Hz" 3 "2Hz" 4 "1Hz" 5 "Not_Used" 6 "Not_Used" 7 "Not_Used" ;
VAL_ 1328 RADAR_1_LHMFRadarSensorDistance 28 "Not_Used" 29 "Not_Used" 30 "Startup" 31 "Sensor_Err" ;
VAL_ 1330 DWD_TextDisp 0 "No Active" 1 "Speed exceed 10km/h" 2 "Speed exceed 5km/h" 3 "Controller pedal undeploy" 4 "Slope exceed 10°" 5 "Driving mode is snow、mud、sand" 6 "Keep low speed" 7 "Out rearview mirror undeploy" 8 "Doors are open" 9 "Trunk are open" 10 "System is fail" 11 "System is not available" 12 "Sys exit" ;
VAL_ 1330 DWD_SoundIndcn 0 "No warning" 1 "Long beep" 2 "3Hz" 3 "1.5Hz" ;
VAL_ 1330 LSensorFailSts 0 "Sensor normal" 1 "Sensor fault" ;
VAL_ 1330 RSensorFailSts 0 "Sensor normal" 1 "Sensor fault" ;
VAL_ 1330 DWD_Distance 0 "No object" 1 "Object in zone 1, 0~5cm" 2 "Object in zone 2, 6~10cm" 3 "Object in zone 3, 11~15cm" 4 "Object in zone 4, 16~20cm" 5 "Object in zone 5, 21~25cm" 6 "Object in zone 6, 26~30cm" 7 "Object in zone 7, 31~35cm" 8 "Object in zone 8, 36~40cm" 9 "Object in zone 9, 41~45cm" 10 "Object in zone 10, 46~50cm" 11 "Object in zone 11, 51~55cm" 12 "Object in zone 12, 56~60cm" 13 "Object in zone 13, 61~65cm" 14 "Object in zone 14, 66~70cm" 15 "Object in zone 15, 71~75cm" 16 "Object in zone 16, 76~80cm" 17 "Object in zone 17, 81~85cm" 18 "Object in zone 18, 86~90cm" 19 "Object in zone 19, 91~95cm" 20 "Object in zone 20, 96~100cm" 21 "Object in zone 21, 101~105cm" 22 "Object in zone 22, 105~110cm" 23 "Object in zone 23, 111~115cm" 24 "Object in zone 24, 116~120cm" 25 "Object in zone 25, 121~125cm" 26 "Object in zone 26, 126~130cm" 27 "Object in zone 27, 131~135cm" 28 "Object in zone 28, 136~140cm" 29 "Object in zone 29, 141~145cm" 30 "Object in zone 30, 146~150cm" ;
VAL_ 1330 DWD_Switch 0 "Not Active" 1 "ON" 2 "OFF" 3 "Reserved" ;
VAL_ 1330 DWD_DistanceL 0 "No object" 1 "Object in zone 1, 0~5cm" 2 "Object in zone 2, 6~10cm" 3 "Object in zone 3, 11~15cm" 4 "Object in zone 4, 16~20cm" 5 "Object in zone 5, 21~25cm" 6 "Object in zone 6, 26~30cm" 7 "Object in zone 7, 31~35cm" 8 "Object in zone 8, 36~40cm" 9 "Object in zone 9, 41~45cm" 10 "Object in zone 10, 46~50cm" 11 "Object in zone 11, 51~55cm" 12 "Object in zone 12, 56~60cm" 13 "Object in zone 13, 61~65cm" 14 "Object in zone 14, 66~70cm" 15 "Object in zone 15, 71~75cm" 16 "Object in zone 16, 76~80cm" 17 "Object in zone 17, 81~85cm" 18 "Object in zone 18, 86~90cm" 19 "Object in zone 19, 91~95cm" 20 "Object in zone 20, 96~100cm" 21 "Object in zone 21, 101~105cm" 22 "Object in zone 22, 105~110cm" 23 "Object in zone 23, 111~115cm" 24 "Object in zone 24, 116~120cm" 25 "Object in zone 25, 121~125cm" 26 "Object in zone 26, 126~130cm" 27 "Object in zone 27, 131~135cm" 28 "Object in zone 28, 136~140cm" 29 "Object in zone 29, 141~145cm" 30 "Object in zone 30, 146~150cm" ;
VAL_ 1330 DWD_DistanceR 0 "No object" 1 "Object in zone 1, 0~5cm" 2 "Object in zone 2, 6~10cm" 3 "Object in zone 3, 11~15cm" 4 "Object in zone 4, 16~20cm" 5 "Object in zone 5, 21~25cm" 6 "Object in zone 6, 26~30cm" 7 "Object in zone 7, 31~35cm" 8 "Object in zone 8, 36~40cm" 9 "Object in zone 9, 41~45cm" 10 "Object in zone 10, 46~50cm" 11 "Object in zone 11, 51~55cm" 12 "Object in zone 12, 56~60cm" 13 "Object in zone 13, 61~65cm" 14 "Object in zone 14, 66~70cm" 15 "Object in zone 15, 71~75cm" 16 "Object in zone 16, 76~80cm" 17 "Object in zone 17, 81~85cm" 18 "Object in zone 18, 86~90cm" 19 "Object in zone 19, 91~95cm" 20 "Object in zone 20, 96~100cm" 21 "Object in zone 21, 101~105cm" 22 "Object in zone 22, 105~110cm" 23 "Object in zone 23, 111~115cm" 24 "Object in zone 24, 116~120cm" 25 "Object in zone 25, 121~125cm" 26 "Object in zone 26, 126~130cm" 27 "Object in zone 27, 131~135cm" 28 "Object in zone 28, 136~140cm" 29 "Object in zone 29, 141~145cm" 30 "Object in zone 30, 146~150cm" ;
VAL_ 1331 ICC_RLSeatEasyEntryExitSet 0 "Not Active" 1 "ON" 2 "OFF" 3 "Not Used" ;
VAL_ 1331 ICC_RRSeatEasyEntryExitSet 0 "Not Active" 1 "ON" 2 "OFF" 3 "Not Used" ;
VAL_ 1331 ICC_RLMemoryRecoveryCmd 0 "Not Active" 1 "Save" 2 "Recover Manual" 3 "RecoverAuto" ;
VAL_ 1331 ICC_RRMemoryRecoveryCmd 0 "Not Active" 1 "Save" 2 "Recover Manual" 3 "RecoverAuto" ;
VAL_ 1331 ICC_RLSitPosnlocation 0 "Not Active" 1 "Location1" 2 "Location2" 3 "Location3" ;
VAL_ 1331 ICC_RRSitPosnlocation 0 "Not Active" 1 "Location1" 2 "Location2" 3 "Location3" ;
VAL_ 1331 ICC_CMSMDisplaySwitch 0 "Not active" 1 "ON" 2 "OFF" 3 "Reserved" ;
VAL_ 1331 ICC_CMSMDisplayAdjustmode 0 "Not active" 1 "NormalAngle" 2 "ViewAngle" 3 "Reserved" ;
VAL_ 1331 ICC_CMSMSetstandardSwitch 0 "Not active" 1 "ON" 2 "OFF" 3 "Reserved" ;
VAL_ 1331 ICC_LeftPedalControl 0 "Not active" 1 "Spread_LeftPedal" 2 "Retract_LeftPedal" 3 "Auto" ;
VAL_ 1331 ICC_RightPedalControl 0 "Not active" 1 "Spread_RightPedal" 2 "Retract_RightPedal" 3 "Auto" ;
VAL_ 1331 ICC_EPCEnable 0 "Not active" 1 "ON" 2 "OFF" 3 "Reserved" ;
VAL_ 1331 ICC_AMPKTVvoiceVolumeSet 0 "Not Active" 1 "0" 2 "1" 3 "2" 4 "3" 5 "4" 6 "5" 7 "6" 8 "7" 9 "8" 10 "9" 11 "10" 12 "11" 13 "12" 14 "13" 15 "14" 16 "15" 17 "16" 18 "17" 19 "18" 20 "19" 21 "20" 22 "21" 23 "22" 24 "23" 25 "24" 26 "25" 27 "26" 28 "27" 29 "28" 30 "29" 31 "30" 32 "31" 33 "Reserved" 34 "Reserved" 35 "Reserved" 36 "Reserved" 37 "Reserved" 38 "Reserved" 39 "Reserved" 40 "Reserved" 41 "Reserved" 42 "Reserved" 43 "Reserved" 44 "Reserved" 45 "Reserved" 46 "Reserved" 47 "Reserved" 48 "Reserved" 49 "Reserved" 50 "Reserved" 51 "Reserved" 52 "Reserved" 53 "Reserved" 54 "Reserved" 55 "Reserved" 56 "Reserved" 57 "Reserved" 58 "Reserved" 59 "Reserved" 60 "Reserved" 61 "Reserved" 62 "Reserved" 63 "Reserved" ;
VAL_ 1331 ICC_AMPA2BENCSoundReq 0 "Not Active" 1 "ON" 2 "OFF" 3 "Reserved" ;
VAL_ 1331 ICC_AMPENCVolumeSet 0 "Not Active" 1 "0" 2 "1" 3 "2" 4 "3" 5 "4" 6 "5" 7 "6" 8 "7" 9 "8" 10 "9" 11 "10" 12 "11" 13 "12" 14 "13" 15 "14" 16 "15" 17 "16" 18 "17" 19 "18" 20 "19" 21 "20" 22 "21" 23 "22" 24 "23" 25 "24" 26 "25" 27 "26" 28 "27" 29 "28" 30 "29" 31 "30" 32 "31" 33 "Reserved" 34 "Reserved" 35 "Reserved" 36 "Reserved" 37 "Reserved" 38 "Reserved" 39 "Reserved" 40 "Reserved" 41 "Reserved" 42 "Reserved" 43 "Reserved" 44 "Reserved" 45 "Reserved" 46 "Reserved" 47 "Reserved" 48 "Reserved" 49 "Reserved" 50 "Reserved" 51 "Reserved" 52 "Reserved" 53 "Reserved" 54 "Reserved" 55 "Reserved" 56 "Reserved" 57 "Reserved" 58 "Reserved" 59 "Reserved" 60 "Reserved" 61 "Reserved" 62 "Reserved" 63 "Reserved" ;
VAL_ 1331 ICC_AMPA2BChimeSoundReq 0 "Not Active" 1 "ON" 2 "OFF" 3 "Reserved" ;
VAL_ 1331 ICC_AMPA2BKTVvoiceSoundReq 0 "Not Active" 1 "IESS OFF and KTV OFF（默认值)" 2 "IESS OFF and KTV ON" 3 "IESS ON and KTV OFF" 4 "IESS ON and KTV ON" ;
VAL_ 1331 Set_AMPSoundFocus_2 0 "Not Active" 1 "Customized" 2 "All" 3 "Driver" 4 "Sleep" 5 "VIP" 6 "FrontRow" 7 "BackRow" ;
VAL_ 1331 ICC_MedStatusSet 0 "Not Active" 1 "ON" 2 "OFF" 3 "Not Used" ;
VAL_ 1331 Set_AMPLoudness 0 "Not Active" 1 "ON" 2 "OFF" 3 "Reserved" ;
VAL_ 1331 ICC_MedAreaSet 0 "Not Active" 1 "Dvr" 2 "Pass" 3 "Drv and Pass" 4 "2Row Drv" 5 "2Row Pass" 6 "2Row Drv and 2Row Pass" 7 "Front Drv and 2Row Pass" 8 "Front Pass and 2Row Drv" 9 "Front Drv and 2Row Drv" 10 "Front Pass and 2Row Pass" ;
VAL_ 1331 ICC_LeftElectricPedalsSet 0 "Not active" 1 "Open" 2 "Close" 3 "Reserved" ;
VAL_ 1331 ICC_RightElectricPedalsSet 0 "Not active" 1 "Open" 2 "Close" 3 "Reserved" ;
VAL_ 1331 ICC_NapAreaSet2 0 "Not Active" 1 "2Row Drv" 2 "2Row Pass" 3 "2Row Drv and Pass" 4 "Front Drv and 2Row Pass" 5 "Front Pass and 2Row Drv" 6 "Front Left and 2Row Drv" 7 "Front Pass and 2Row Pass" ;
VAL_ 1331 Set_AMPExSoundmode 0 "Not Active" 1 "Soundmode1" 2 "Soundmode2" 3 "Soundmode3" 4 "OFF" 5 "Reserved" 6 "Reserved" 7 "Reserved" ;
VAL_ 1331 Set_AMPKeyVolume 0 "Not Active" 1 "0" 2 "1" 3 "2" 4 "3" 5 "4" 6 "5" 7 "6" 8 "7" 9 "8" 10 "9" 11 "10" 12 "11" 13 "12" 14 "13" 15 "14" 16 "15" 17 "16" 18 "17" 19 "18" 20 "19" 21 "20" 22 "21" 23 "22" 24 "23" 25 "24" 26 "25" 27 "26" 28 "27" 29 "28" 30 "29" 31 "30" 32 "31" 33 "Reserved" 34 "Reserved" 35 "Reserved" 36 "Reserved" 37 "Reserved" 38 "Reserved" 39 "Reserved" 40 "Reserved" 41 "Reserved" 42 "Reserved" 43 "Reserved" 44 "Reserved" 45 "Reserved" 46 "Reserved" 47 "Reserved" 48 "Reserved" 49 "Reserved" 50 "Reserved" 51 "Reserved" 52 "Reserved" 53 "Reserved" 54 "Reserved" 55 "Reserved" 56 "Reserved" 57 "Reserved" 58 "Reserved" 59 "Reserved" 60 "Reserved" 61 "Reserved" 62 "Reserved" 63 "Reserved" ;
VAL_ 1331 ICC_CMSMTouchSts 0 "Not active" 1 "Touch" 2 "No Touch" 3 "Reserved" ;
VAL_ 1331 Set_AMPA2BENCSound 0 "Not Active" 1 "FL+FR+RL+SWF" 2 "FL+FR+SWF+RR" 3 "FL+FR+RL+RR" 4 "OFF" 5 "reserved" 6 "reserved" 7 "reserved" ;
VAL_ 1333 ICC_SRFCmd 0 "Not Active" 1 "Open" 2 "Close" 3 "Tilt" 4 "Reserved" 5 "Reserved" 6 "Reserved" 7 "Reserved" ;
VAL_ 1333 ICC_SRFPercentCmd 0 "Not Active" 1 "0" 2 "10%" 3 "20%" 4 "30%" 5 "40%" 6 "50%" 7 "60%" 8 "70%" 9 "80%" 10 "90%" 11 "100%" ;
VAL_ 1333 ICC_SunshadeCmd 0 "Not Acitive" 1 "Open" 2 "Close" 3 "Half_Open" 4 "Reserved" 5 "Reserved" 6 "Reserved" 7 "Reserved" ;
VAL_ 1333 ICC_SunshadePercentCmd 0 "No Acitive" 1 "0%" 2 "10%" 3 "20%" 4 "30%" 5 "40%" 6 "50%" 7 "60%" 8 "70%" 9 "80%" 10 "90%" 11 "100%" ;
VAL_ 1333 ICC_CSunshadeReq 0 "Not Active" 1 "Open" 2 "Close" 3 "HalfOpen" ;
VAL_ 1333 ICC_CSunshadePercentReq 0 "Not Active" 1 "0%" 2 "10%" 3 "20%" 4 "30%" 5 "40%" 6 "50%" 7 "60%" 8 "70%" 9 "80%" 10 "90%" 11 "100%" ;
VAL_ 1333 CSunshadeLearnedReq_535h 0 "Not Active" 1 "StartLearn" 2 "StopLearn" 3 "reserved" ;
VAL_ 1333 CSunshadePercentReq_535h 0 "No request" 1 "Sunshade 0%" 2 "Sunshade 1%" 3 "Sunshade 2%" 4 "Sunshade 3%" 5 "Sunshade 4%" 6 "Sunshade 5%" 7 "Sunshade 6%" 8 "Sunshade 7%" 9 "Sunshade 8%" 10 "Sunshade 9%" 11 "Sunshade 10%" 12 "Sunshade 11%" 13 "Sunshade 12%" 14 "Sunshade 13%" 15 "Sunshade 14%" 16 "Sunshade 15%" 17 "Sunshade 16%" 18 "Sunshade 17%" 19 "Sunshade 18%" 20 "Sunshade 19%" 21 "Sunshade 20%" 22 "Sunshade 21%" 23 "Sunshade 22%" 24 "Sunshade 23%" 25 "Sunshade 24%" 26 "Sunshade 25%" 27 "Sunshade 26%" 28 "Sunshade 27%" 29 "Sunshade 28%" 30 "Sunshade 29%" 31 "Sunshade 30%" 32 "Sunshade 31%" 33 "Sunshade 32%" 34 "Sunshade 33%" 35 "Sunshade 34%" 36 "Sunshade 35%" 37 "Sunshade 36%" 38 "Sunshade 37%" 39 "Sunshade 38%" 40 "Sunshade 39%" 41 "Sunshade 40%" 42 "Sunshade 41%" 43 "Sunshade 42%" 44 "Sunshade 43%" 45 "Sunshade 44%" 46 "Sunshade 45%" 47 "Sunshade 46%" 48 "Sunshade 47%" 49 "Sunshade 48%" 50 "Sunshade 49%" 51 "Sunshade 50%" 52 "Sunshade 51%" 53 "Sunshade 52%" 54 "Sunshade 53%" 55 "Sunshade 54%" 56 "Sunshade 55%" 57 "Sunshade 56%" 58 "Sunshade 57%" 59 "Sunshade 58%" 60 "Sunshade 59%" 61 "Sunshade 60%" 62 "Sunshade 61%" 63 "Sunshade 62%" 64 "Sunshade 63%" 65 "Sunshade 64%" 66 "Sunshade 65%" 67 "Sunshade 66%" 68 "Sunshade 67%" 69 "Sunshade 68%" 70 "Sunshade 69%" 71 "Sunshade 70%" 72 "Sunshade 71%" 73 "Sunshade 72%" 74 "Sunshade 73%" 75 "Sunshade 74%" 76 "Sunshade 75%" 77 "Sunshade 76%" 78 "Sunshade 77%" 79 "Sunshade 78%" 80 "Sunshade 79%" 81 "Sunshade 80%" 82 "Sunshade 81%" 83 "Sunshade 82%" 84 "Sunshade 83%" 85 "Sunshade 84%" 86 "Sunshade 85%" 87 "Sunshade 86%" 88 "Sunshade 87%" 89 "Sunshade 88%" 90 "Sunshade 89%" 91 "Sunshade 90%" 92 "Sunshade 91%" 93 "Sunshade 92%" 94 "Sunshade 93%" 95 "Sunshade 94%" 96 "Sunshade 95%" 97 "Sunshade 96%" 98 "Sunshade 97%" 99 "Sunshade 98%" 100 "Sunshade 99%" 101 "Sunshade 100%" 102 "Stop" 103 "initialize" 104 "Reserved" 105 "Reserved" 106 "Reserved" 107 "Reserved" 108 "Reserved" 109 "Reserved" 110 "Reserved" 111 "Reserved" 112 "Reserved" 113 "Reserved" 114 "Reserved" 115 "Reserved" 116 "Reserved" 117 "Reserved" 118 "Reserved" 119 "Reserved" 120 "Reserved" 121 "Reserved" 122 "Reserved" 123 "Reserved" 124 "Reserved" 125 "Reserved" 126 "Reserved" 127 "Reserved" 128 "Reserved" 129 "Reserved" 130 "Reserved" 131 "Reserved" 132 "Reserved" 133 "Reserved" 134 "Reserved" 135 "Reserved" 136 "Reserved" 137 "Reserved" 138 "Reserved" 139 "Reserved" 140 "Reserved" 141 "Reserved" 142 "Reserved" 143 "Reserved" 144 "Reserved" 145 "Reserved" 146 "Reserved" 147 "Reserved" 148 "Reserved" 149 "Reserved" 150 "Reserved" 151 "Reserved" 152 "Reserved" 153 "Reserved" 154 "Reserved" 155 "Reserved" 156 "Reserved" 157 "Reserved" 158 "Reserved" 159 "Reserved" 160 "Reserved" 161 "Reserved" 162 "Reserved" 163 "Reserved" 164 "Reserved" 165 "Reserved" 166 "Reserved" 167 "Reserved" 168 "Reserved" 169 "Reserved" 170 "Reserved" 171 "Reserved" 172 "Reserved" 173 "Reserved" 174 "Reserved" 175 "Reserved" 176 "Reserved" 177 "Reserved" 178 "Reserved" 179 "Reserved" 180 "Reserved" 181 "Reserved" 182 "Reserved" 183 "Reserved" 184 "Reserved" 185 "Reserved" 186 "Reserved" 187 "Reserved" 188 "Reserved" 189 "Reserved" 190 "Reserved" 191 "Reserved" 192 "Reserved" 193 "Reserved" 194 "Reserved" 195 "Reserved" 196 "Reserved" 197 "Reserved" 198 "Reserved" 199 "Reserved" 200 "Reserved" 201 "Reserved" 202 "Reserved" 203 "Reserved" 204 "Reserved" 205 "Reserved" 206 "Reserved" 207 "Reserved" 208 "Reserved" 209 "Reserved" 210 "Reserved" 211 "Reserved" 212 "Reserved" 213 "Reserved" 214 "Reserved" 215 "Reserved" 216 "Reserved" 217 "Reserved" 218 "Reserved" 219 "Reserved" 220 "Reserved" 221 "Reserved" 222 "Reserved" 223 "Reserved" 224 "Reserved" 225 "Reserved" 226 "Reserved" 227 "Reserved" 228 "Reserved" 229 "Reserved" 230 "Reserved" 231 "Reserved" 232 "Reserved" 233 "Reserved" 234 "Reserved" 235 "Reserved" 236 "Reserved" 237 "Reserved" 238 "Reserved" 239 "Reserved" 240 "Reserved" 241 "Reserved" 242 "Reserved" 243 "Reserved" 244 "Reserved" 245 "Reserved" 246 "Reserved" 247 "Reserved" 248 "Reserved" 249 "Reserved" 250 "Reserved" 251 "Reserved" 252 "Reserved" 253 "Reserved" 254 "Reserved" 255 "Reserved" ;
VAL_ 1335 ICC_SET_EPS_SteerReturnRmdSts 0 "Not Active" 1 "ON" 2 "OFF" 3 "reserved" ;
VAL_ 1335 ICC_SET_MFSShake 0 "Not Active" 1 "ON" 2 "OFF" 3 "reserved" ;
VAL_ 1335 ICC_DMS_1_DistractionLevel 0 "Not Active" 1 "DISTRACTION_LEVEL_LIGHT" 2 "DISTRACTION_LEVEL_MEDIUM" 3 "DISTRACTION_LEVEL_HEAVY" ;
VAL_ 1335 ICC_SET_EPS_AsociWithDrvModSts 0 "Not_Active" 1 "ON" 2 "OFF" 3 "reserved" ;
VAL_ 1335 ICC_OverLoadWarnShieldSet 0 "Not Active" 1 "ON" 2 "OFF" 3 "reserved" ;
VAL_ 1335 ICC_BSWReq 0 "Not Active" 1 "ON" 2 "OFF" 3 "reserved" ;
VAL_ 1335 ICC_horizontalReq 0 "Not Active" 1 "ON" 2 "OFF" 3 "Not Used" ;
VAL_ 1335 ICC_RolloverSetCmd 0 "Not Active" 1 "Rollover Deploy OFF" 2 "Rollover Deploy ON" 3 "reserved" ;
VAL_ 1335 ICC_TrekThroughReq_537h 0 "Not Active" 1 "ON" 2 "OFF" 3 "Reserved" ;
VAL_ 1335 ICC_InflateReq_537h 0 "Not Active" 1 "ON" 2 "OFF" 3 "Reserved" ;
VAL_ 1335 ICC_UndergroundModeReq_537h 0 "Not Active" 1 "ON" 2 "OFF" 3 "Reserved" ;
VAL_ 1335 ICC_SandABSSw_537h 0 "Not_Active" 1 "ON" 2 "OFF" 3 "Reserved" ;
VAL_ 1335 ICC_SandABSCmd_537h 0 "Not_Active" 1 "ON" 2 "OFF" 3 "Reserved" ;
VAL_ 1335 ICC_EPBAUTOCmd_537h 0 "Not_Active" 1 "Switch_On" 2 "Switch_Off" 3 "Not_Used" ;
VAL_ 1335 ICC_SpeParkSet_537h 0 "Not_Active" 1 "ON" 2 "OFF" 3 "Not_Used" ;
VAL_ 1337 ICC_SET_BT_ReduceWindSpeed 0 "Not_Active" 1 "ON" 2 "OFF" 3 "Reserved" ;
VAL_ 1337 ICC_SET_IPM_FirstBlowing 0 "Not Active" 1 "ON" 2 "OFF" 3 "Reserved" ;
VAL_ 1337 ICC_SET_IPM_BlowerDelay 0 "Not Active" 1 "ON" 2 "OFF" 3 "Reserved" ;
VAL_ 1337 ICC_SET_CirculationInTunnels 0 "Not Active" 1 "ON" 2 "OFF" 3 "Reserved" ;
VAL_ 1337 ICC_UVCLuminanceReq 0 "Not Active" 1 "high" 2 "lower" 3 "reserved" ;
VAL_ 1337 ICC_UVCControlReq 0 "Not Active" 1 "ON" 2 "OFF" 3 "AUTO" ;
VAL_ 1337 ICC_CrossCountryCoolingReq 0 "Not Active" 1 "ON" 2 "OFF" 3 "Reserved" ;
VAL_ 1337 ICC_KeepWarmReq 0 "Not Active" 1 "Open_AC" 2 "Open_NotAC" 3 "Closed" ;
VAL_ 1337 ICC_keepwarmSetTemperatureReq 0 "Not Active" 1 "Temperature 20°C" 2 "Temperature 25°C" 3 "Temperature 30°C" 4 "Temperature 35°C" 5 "Temperature 40°C" 6 "Temperature 45°C" 7 "Temperature 50°C" 8 "Temperature 55°C" 9 "Temperature 60°C" ;
VAL_ 1337 ICC_ParkingAirConditioning 0 "Not Active" 1 "Disable" 2 "AUTO" 3 "ventilate" ;
VAL_ 1337 ICC_CoolantFill_Req 0 "Not Active" 1 "ON" 2 "OFF" 3 "Reserved" ;
VAL_ 1337 ICC_FraganceLightoffReq 0 "No Active" 1 "FraganceLight_on" 2 "FraganceLight_off" 3 "Reserved" ;
VAL_ 1337 ICC_FraganceMemoffReq 0 "Not_Active" 1 "FraganceMem_on" 2 "FraganceMem_off" 3 "Reserved" ;
VAL_ 1337 ICC_TimingLevel 0 "Not_Active" 1 "CFSTiming level1" 2 "CFSTiming level2" 3 "CFSTiming level3" 4 "CFSTiming level4" 5 "reserved" 6 "reserved" 7 "reserved" ;
VAL_ 1337 ICC_CFSCycleLevel 0 "Not_Active" 1 "CFSCycle level1" 2 "CFSCycle level2" 3 "CFSCycle level3" 4 "CFSCycle level4" 5 "reserved" 6 "reserved" 7 "reserved" ;
VAL_ 1337 ICC_AirPurgeReminderReq 0 "Not_Active" 1 "ON" 2 "OFF" 3 "Not_Used" ;
VAL_ 1337 ICC_TimedVentilationReq 0 "Not Active" 1 "ON" 2 "OFF" 3 "Reserved" ;
VAL_ 1337 ICC_BiochemicalFuncReq 0 "Not Active" 1 "ON" 2 "OFF" 3 "Reserved" ;
VAL_ 1337 ICC_ModeAdjustDisplaySts 0 "BlowFace" 1 "BlowFaceAndBlowFoot" 2 "BlowFoot" 3 "BlowFootAndBlowWindow" 4 "BlowWindow" 5 "Not?Active" 6 "BlowFaceAndBlowWindow" 7 "BlowFaceAndBlowFootAndBlowWindow" 8 "Auto" 9 "reserved" 10 "reserved" 11 "reserved" 12 "reserved" 13 "reserved" 14 "reserved" 15 "reserved" ;
VAL_ 1337 ICC_PetModeSetTemperature_R_C 31 "Not active" ;
VAL_ 1337 ICC_PetmodeSetTemperature_L_C 31 "Not active" ;
VAL_ 1337 ICC_PetModeSetCirculationSts 0 "Not Active" 1 "Recirculation mode" 2 "Air circulation mode" 3 "Two-Layer Flow Mode" ;
VAL_ 1337 ICC_PetModeSetAutoKeySts 0 "Not Active" 1 "On" 2 "Off" 3 "Not Used" ;
VAL_ 1337 ICC_PetModeSetCLMOn 0 "Not Active" 1 "On" 2 "Off" 3 "Not Used" ;
VAL_ 1337 ICC_ISSFctCmd_539h 0 "Not Active" 1 "ON" 2 "OFF" 3 "Not Used" ;
VAL_ 1338 FMCU_ErrLvlDis 0 "No Error" 1 "Err_level1" 2 "Err_level2" 3 "Err_level3" 4 "Err_level4" 5 "Err_level5" 6 "Err_level6" ;
VAL_ 1338 FMCU_SpdAct_EDR 65535 "Invalid" ;
VAL_ 1345 DVR_1_DVRFailReasons 0 "NoFailure" 1 "DVR360StorageFailure" 2 "DVRFCMStorageFailure" 3 "DVRAllFailure" 4 "Reserved" 5 "Reserved" 6 "Reserved" 7 "Reserved" ;
VAL_ 1345 DVR_1_RecordSts 0 "Initinal" 1 "Recording" 2 "RecordStop" 3 "Reserved" ;
VAL_ 1345 DVR_1_Sdcard_Sts 0 "Normal" 1 "Not inserted" 2 "Filesystem unsupported" 3 "Capacity unsupported" 4 "Abnormal" 5 "Full" 6 "Reserved" 7 "Reserved" ;
VAL_ 1349 SBOX_MSD_Res 0 "Reserved" 1 "send successfully" 2 "no signal" 3 "uncast net" 4 "short messages not enough" ;
VAL_ 1349 SBOX_Ecallphonenub_Res 0 "Reserved" 1 "dialing" 2 "ringing" 3 "on the line" 4 "hang up" 5 "no signal" 6 "uncast net" ;
VAL_ 1353 SBOX_ICC_MACReq 0 "invalid" 1 "request connect" ;
VAL_ 1356 ICC_flag 0 "invalid" 1 "sim" 2 "tsp register" ;
VAL_ 1356 ICC_ActiveTsp_Req 0 "invalid" 1 "Do not initiate TSP registration" 2 "initiate TSP registration" ;
VAL_ 1356 ICC_ActiveSim_Req 0 "invalid" 1 "sim not activate" 2 "sim activate" ;
VAL_ 1356 ICC_GetMac_req 0 "invalid" 1 "search" ;
VAL_ 1356 ICC_GetIccid_Vin 0 "invalid" 1 "search" ;
VAL_ 1356 ICC_GivePlatformNumber_Flag 0 "platform_number invalid" 1 "platform_number valid" ;
VAL_ 1356 ICC_Mac_Flag 0 "IccMacInvalid" 1 "IccMacValid" ;
VAL_ 1360 ICC_LISD_DisplaySwitch 0 "Default value" 1 "Display ON" 2 "Display OFF" 3 "Reserved" ;
VAL_ 1360 ICC_LISD_ParkingShowCMD 0 "Default value" 1 "ON" 2 "OFF" 3 "Reserved" ;
VAL_ 1360 ICC_RISD_DisplaySwitch 0 "Default value" 1 "Display ON" 2 "Display OFF" 3 "Reserved" ;
VAL_ 1360 ICC_RISD_ParkingShowCMD 0 "Default value" 1 "ON" 2 "OFF" 3 "Reserved" ;
VAL_ 1360 ICC_LogoParkingReq 0 "Not Active" 1 "ON" 2 "OFF" 3 "Reserved" ;
VAL_ 1360 ICC_LogoChargingReq 0 "Not Active" 1 "ON" 2 "OFF" 3 "Reserved" ;
VAL_ 1360 ICC_DRLSw 0 "Not active" 1 "ON" 2 "OFF" 3 "Reserved" ;
VAL_ 1360 ICC_LISD_ParkingShowMod 0 "Default value" 1 "Mode1" 2 "Mode2" 3 "Mode3" 4 "Mode4" 5 "Reserved" 6 "Reserved" 7 "Reserved" 8 "Reserved" 9 "Reserved" 10 "Reserved" 11 "Reserved" 12 "Reserved" 13 "Reserved" 14 "Reserved" 15 "Reserved" ;
VAL_ 1360 ICC_RISD_ParkingShowMod 0 "Default value" 1 "Mode1" 2 "Mode2" 3 "Mode3" 4 "Mode4" 5 "Reserved" 6 "Reserved" 7 "Reserved" 8 "Reserved" 9 "Reserved" 10 "Reserved" 11 "Reserved" 12 "Reserved" 13 "Reserved" 14 "Reserved" 15 "Reserved" ;
VAL_ 1360 ICC_LogoColorReq 0 "Not_Active" ;
VAL_ 1360 ICC_MusicLampShowSW 0 "Not active" 1 "OFF" 2 "ON" 3 "Reserved" ;
VAL_ 1360 ICC_PenetrationLampSetF 0 "Not_Active" 1 "ON" 2 "OFF" 3 "reserved" ;
VAL_ 1360 ICC_XDriveMode 0 "Not Active" 1 "unidentifiable" 2 "Normal" 3 "SNOW" 4 "MUD" 5 "ROCK" 6 "SAND" 7 "WATERSURFACE" 8 "Normal" 9 "SNOW" 10 "MUD" 11 "ROCK" 12 "SAND" 13 "WATERSURFACE" 14 "Normal" 15 "SNOW" 16 "MUD" 17 "ROCK" 18 "SAND" 19 "Reserved" 20 "Reserved" 21 "Reserved" 22 "Reserved" 23 "Reserved" 24 "Reserved" 25 "Reserved" 26 "Reserved" 27 "Reserved" 28 "Reserved" 29 "Reserved" 30 "Reserved" 31 "Reserved" ;
VAL_ 1360 ICC_DowWaringSw 0 "Not_Active" 1 "ON" 2 "OFF" 3 "reserved" ;
VAL_ 1360 ICC_CarSearhSetSwitchSts 0 "Not Active" 1 "Only Lighting" 2 "Sound and Lighting" 3 "Reserved" ;
VAL_ 1360 ICC_TDL_NightBright_SW_550h 0 "Not_Active" 1 "ON" 2 "OFF" 3 "reserved" ;
VAL_ 1361 EPC_LeftPedalSystem_Sts 0 "Normal" 1 "Voltage_protect" 2 "System_fault" 3 "Over_temperature" 4 "Disable_mode" 5 "Left_steer" 6 "Left_pedal_Anti-pinch" 7 "Reserved" 8 "Reserved" 9 "Reserved" 10 "Reserved" 11 "Reserved" 12 "Reserved" 13 "Reserved" 14 "Reserved" 15 "Reserved" ;
VAL_ 1361 EPC_RightPedalSystem_Sts 0 "Normal" 1 "Voltage_protect" 2 "System_fault" 3 "Over_temperature" 4 "Disable_mode" 5 "Right_steer" 6 "Right_pedal_Anti-pinch" 7 "Reserved" 8 "Reserved" 9 "Reserved" 10 "Reserved" 11 "Reserved" 12 "Reserved" 13 "Reserved" 14 "Reserved" 15 "Reserved" ;
VAL_ 1361 EPC_RightPedalRealTime_Sts 0 "Invalid" 1 "Right_pedal_retract_back_in_place" 2 "Right_pedal_is_retracting" 3 "Right_pedal_retract_failed" 4 "Right_pedal_spread_in_place" 5 "Right_pedal_is_spreading" 6 "Right_pedal_is_spread_failed" 7 "Reserved" ;
VAL_ 1361 EPC_LeftPedalBreakIce_Sts 0 "Invalid" 1 "Left_pedal_is_breaking_ice" 2 "Left_pedal_break_ice_successfully" 3 "Left_pedal_break_ice_failed" ;
VAL_ 1361 EPC_LeftPedalRealTime_Sts 0 "Invalid" 1 "Left_pedal_retract_back_in_place" 2 "Left_pedal_is_retracting" 3 "Left_pedal_retract_failed" 4 "Left_pedal_spread_in_place" 5 "Left_pedal_is_spreading" 6 "Left_pedal_is_spread_failed" 7 "Reserved" ;
VAL_ 1361 EPC_RightPedalCmdStatus 0 "Not active" 1 "Spread_RightPedal" 2 "Retract_RightPedal" 3 "Auto" ;
VAL_ 1361 EPC_LeftPedalCmdStatus 0 "Not active" 1 "Spread_LeftPedal" 2 "Retract_LeftPedal" 3 "Auto" ;
VAL_ 1361 EPC_Enable_CmdStatus 0 "Not active" 1 "ON" 2 "OFF" 3 "Invaild" ;
VAL_ 1361 EPC_RightPedalBreakIce_Sts 0 "Invalid" 1 "Right_pedal_is_breaking_ice" 2 "Right_pedal_break_ice_successfully" 3 "Right_pedal_break_ice_failed" ;
VAL_ 1361 EPC_RightPedal3D_Sts 0 "Not Active" 1 "Open" 2 "Close" 3 "Reserved" ;
VAL_ 1361 EPC_LeftPedal3D_Sts 0 "Not Active" 1 "Open" 2 "Close" 3 "Reserved" ;
